VERSION ""

NS_ :

BS_:

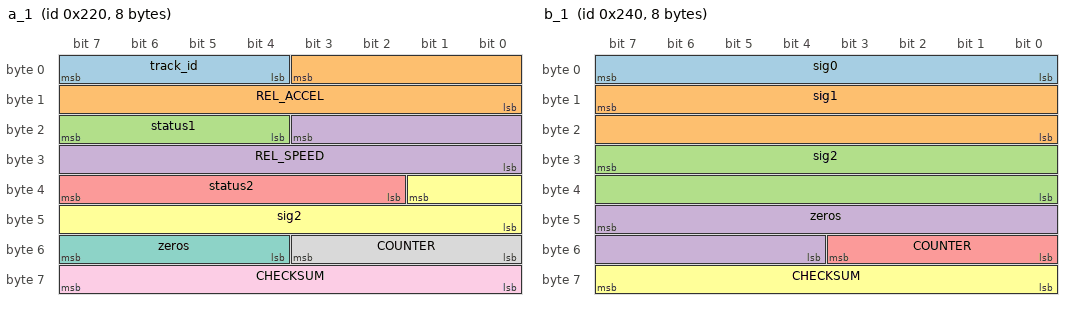
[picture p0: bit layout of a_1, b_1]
BO_ 544 a_1: 8 XXX
 SG_ track_id : 7|4@0+ (1,0) [0|15] "" XXX
 SG_ REL_ACCEL : 3|12@0+ (1,0) [0|31] "" XXX
 SG_ status1 : 23|4@0+ (1,0) [0|15] "" XXX
 SG_ REL_SPEED : 19|12@0+ (1,0) [0|65535] "" XXX
 SG_ status2 : 39|6@0+ (1,0) [0|15] "" XXX
 SG_ sig2 : 33|10@0+ (1,0) [0|255] "" XXX
 SG_ zeros : 55|4@0+ (1,0) [0|15] "" XXX
 SG_ COUNTER : 51|4@0+ (1,0) [0|15] "" XXX
 SG_ CHECKSUM : 63|8@0+ (1,0) [0|255] "" XXX

BO_ 576 b_1: 8 XXX
 SG_ sig0 : 7|8@0+ (1,0) [0|255] "" XXX
 SG_ sig1 : 15|16@0+ (1,0) [0|65535] "" XXX
 SG_ sig2 : 31|16@0+ (1,0) [0|255] "" XXX
 SG_ zeros : 47|12@0+ (1,0) [0|255] "" XXX
 SG_ COUNTER : 51|4@0+ (1,0) [0|15] "" XXX
 SG_ CHECKSUM : 63|8@0+ (1,0) [0|255] "" XXX

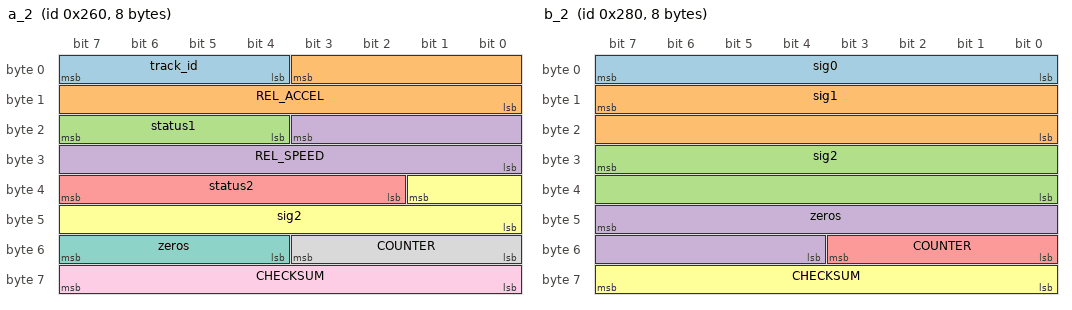
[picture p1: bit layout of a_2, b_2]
BO_ 608 a_2: 8 XXX
 SG_ track_id : 7|4@0+ (1,0) [0|15] "" XXX
 SG_ REL_ACCEL : 3|12@0+ (1,0) [0|31] "" XXX
 SG_ status1 : 23|4@0+ (1,0) [0|15] "" XXX
 SG_ REL_SPEED : 19|12@0+ (1,0) [0|65535] "" XXX
 SG_ status2 : 39|6@0+ (1,0) [0|15] "" XXX
 SG_ sig2 : 33|10@0+ (1,0) [0|255] "" XXX
 SG_ zeros : 55|4@0+ (1,0) [0|15] "" XXX
 SG_ COUNTER : 51|4@0+ (1,0) [0|15] "" XXX
 SG_ CHECKSUM : 63|8@0+ (1,0) [0|255] "" XXX

BO_ 640 b_2: 8 XXX
 SG_ sig0 : 7|8@0+ (1,0) [0|255] "" XXX
 SG_ sig1 : 15|16@0+ (1,0) [0|65535] "" XXX
 SG_ sig2 : 31|16@0+ (1,0) [0|255] "" XXX
 SG_ zeros : 47|12@0+ (1,0) [0|255] "" XXX
 SG_ COUNTER : 51|4@0+ (1,0) [0|15] "" XXX
 SG_ CHECKSUM : 63|8@0+ (1,0) [0|255] "" XXX

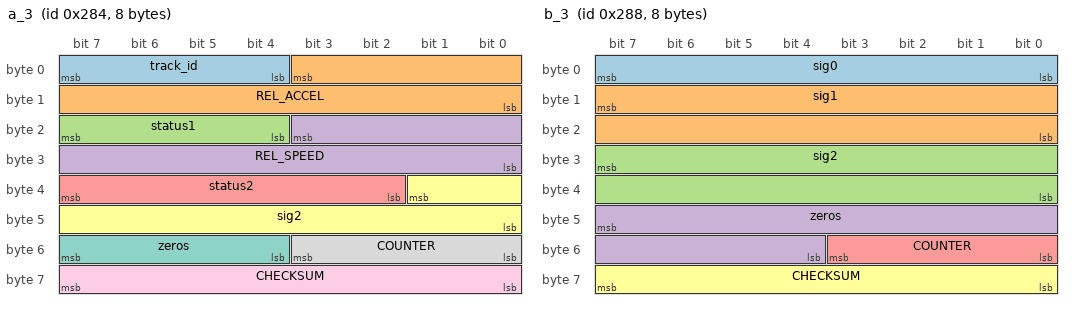
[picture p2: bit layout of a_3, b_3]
BO_ 644 a_3: 8 XXX
 SG_ track_id : 7|4@0+ (1,0) [0|15] "" XXX
 SG_ REL_ACCEL : 3|12@0+ (1,0) [0|31] "" XXX
 SG_ status1 : 23|4@0+ (1,0) [0|15] "" XXX
 SG_ REL_SPEED : 19|12@0+ (1,0) [0|65535] "" XXX
 SG_ status2 : 39|6@0+ (1,0) [0|15] "" XXX
 SG_ sig2 : 33|10@0+ (1,0) [0|255] "" XXX
 SG_ zeros : 55|4@0+ (1,0) [0|15] "" XXX
 SG_ COUNTER : 51|4@0+ (1,0) [0|15] "" XXX
 SG_ CHECKSUM : 63|8@0+ (1,0) [0|255] "" XXX

BO_ 648 b_3: 8 XXX
 SG_ sig0 : 7|8@0+ (1,0) [0|255] "" XXX
 SG_ sig1 : 15|16@0+ (1,0) [0|65535] "" XXX
 SG_ sig2 : 31|16@0+ (1,0) [0|255] "" XXX
 SG_ zeros : 47|12@0+ (1,0) [0|255] "" XXX
 SG_ COUNTER : 51|4@0+ (1,0) [0|15] "" XXX
 SG_ CHECKSUM : 63|8@0+ (1,0) [0|255] "" XXX

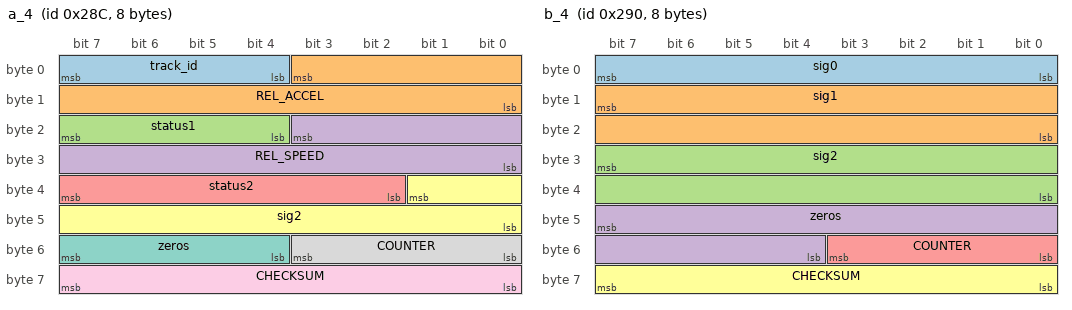
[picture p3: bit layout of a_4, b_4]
BO_ 652 a_4: 8 XXX
 SG_ track_id : 7|4@0+ (1,0) [0|15] "" XXX
 SG_ REL_ACCEL : 3|12@0+ (1,0) [0|31] "" XXX
 SG_ status1 : 23|4@0+ (1,0) [0|15] "" XXX
 SG_ REL_SPEED : 19|12@0+ (1,0) [0|65535] "" XXX
 SG_ status2 : 39|6@0+ (1,0) [0|15] "" XXX
 SG_ sig2 : 33|10@0+ (1,0) [0|255] "" XXX
 SG_ zeros : 55|4@0+ (1,0) [0|15] "" XXX
 SG_ COUNTER : 51|4@0+ (1,0) [0|15] "" XXX
 SG_ CHECKSUM : 63|8@0+ (1,0) [0|255] "" XXX

BO_ 656 b_4: 8 XXX
 SG_ sig0 : 7|8@0+ (1,0) [0|255] "" XXX
 SG_ sig1 : 15|16@0+ (1,0) [0|65535] "" XXX
 SG_ sig2 : 31|16@0+ (1,0) [0|255] "" XXX
 SG_ zeros : 47|12@0+ (1,0) [0|255] "" XXX
 SG_ COUNTER : 51|4@0+ (1,0) [0|15] "" XXX
 SG_ CHECKSUM : 63|8@0+ (1,0) [0|255] "" XXX

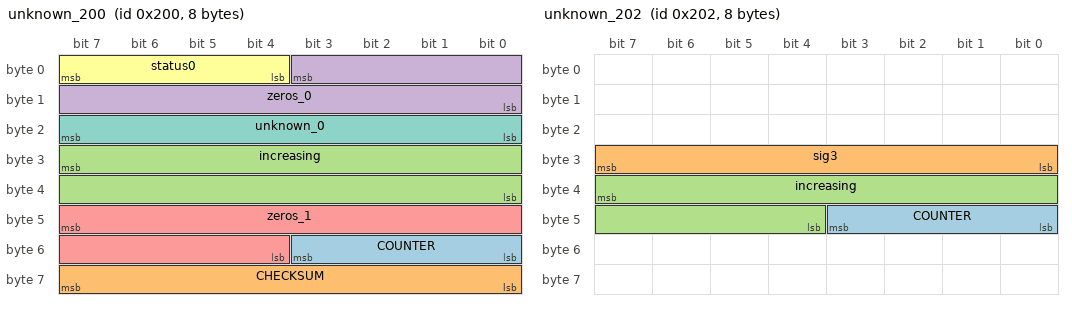
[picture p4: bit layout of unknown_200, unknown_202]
BO_ 512 unknown_200: 8 XXX
 SG_ COUNTER : 51|4@0+ (1,0) [0|15] "" XXX
 SG_ CHECKSUM : 63|8@0+ (1,0) [0|255] "" XXX
 SG_ increasing : 31|16@0+ (1,0) [0|255] "" XXX
 SG_ zeros_0 : 3|12@0+ (1,0) [0|63] "" XXX
 SG_ zeros_1 : 47|12@0+ (1,0) [0|63] "" XXX
 SG_ status0 : 7|4@0+ (1,0) [0|15] "" XXX
 SG_ unknown_0 : 23|8@0+ (1,0) [0|255] "" XXX

BO_ 514 unknown_202: 8 XXX
 SG_ COUNTER : 43|4@0+ (1,0) [0|15] "" XXX
 SG_ sig3 : 31|8@0+ (1,0) [0|65535] "" XXX
 SG_ increasing : 39|12@0+ (1,0) [0|15] "" XXX

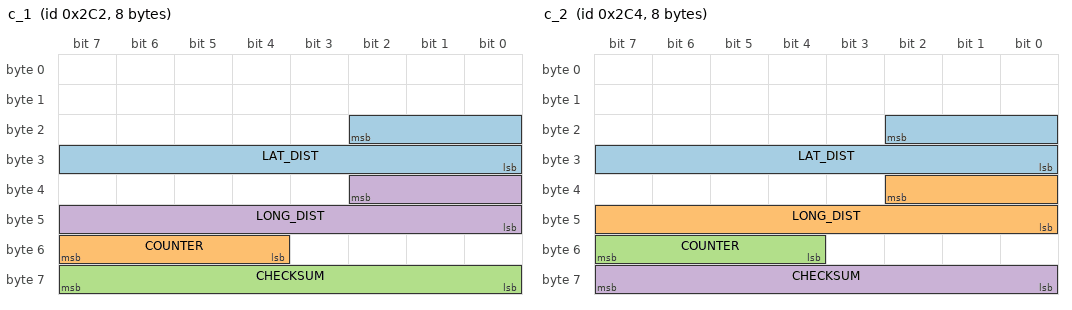
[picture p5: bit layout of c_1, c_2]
BO_ 706 c_1: 8 XXX
 SG_ LAT_DIST : 18|11@0+ (0.005,-1000) [0|2047] "m" XXX
 SG_ COUNTER : 55|4@0+ (1,0) [0|15] "" XXX
 SG_ CHECKSUM : 63|8@0+ (1,0) [0|255] "" XXX
 SG_ LONG_DIST : 34|11@0+ (0.073,0) [0|255] "m" XXX

BO_ 708 c_2: 8 XXX
 SG_ LAT_DIST : 18|11@0+ (0.005,-1000) [0|2047] "m" XXX
 SG_ LONG_DIST : 34|11@0+ (0.073,0) [0|255] "m" XXX
 SG_ COUNTER : 55|4@0+ (1,0) [0|15] "" XXX
 SG_ CHECKSUM : 63|8@0+ (1,0) [0|255] "" XXX

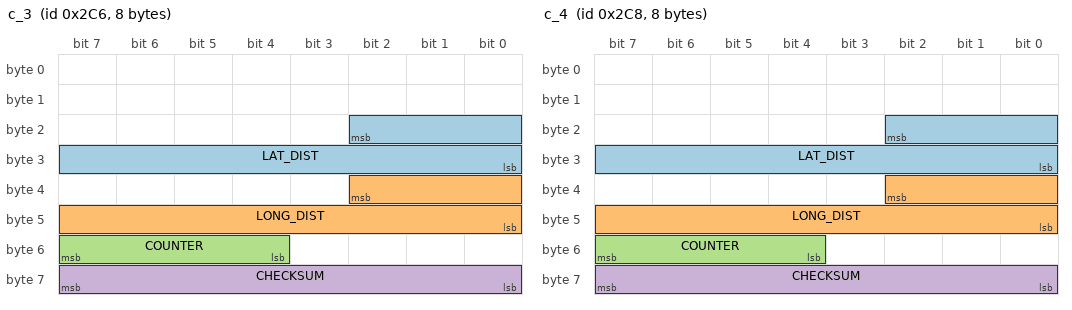
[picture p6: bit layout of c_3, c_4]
BO_ 710 c_3: 8 XXX
 SG_ LAT_DIST : 18|11@0+ (0.005,-1000) [0|2047] "m" XXX
 SG_ LONG_DIST : 34|11@0+ (0.073,0) [0|255] "m" XXX
 SG_ COUNTER : 55|4@0+ (1,0) [0|15] "" XXX
 SG_ CHECKSUM : 63|8@0+ (1,0) [0|255] "" XXX

BO_ 712 c_4: 8 XXX
 SG_ LAT_DIST : 18|11@0+ (0.005,-1000) [0|2047] "m" XXX
 SG_ LONG_DIST : 34|11@0+ (0.073,0) [0|255] "m" XXX
 SG_ COUNTER : 55|4@0+ (1,0) [0|15] "" XXX
 SG_ CHECKSUM : 63|8@0+ (1,0) [0|255] "" XXX

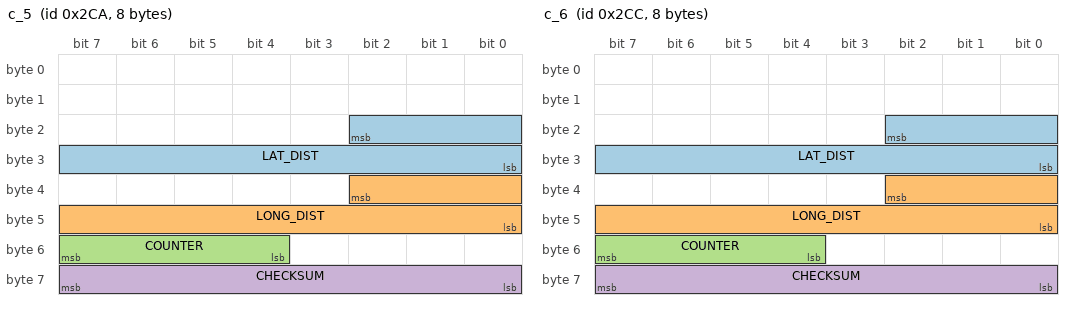
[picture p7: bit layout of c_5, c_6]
BO_ 714 c_5: 8 XXX
 SG_ LAT_DIST : 18|11@0+ (0.005,-1000) [0|2047] "m" XXX
 SG_ LONG_DIST : 34|11@0+ (0.073,0) [0|255] "m" XXX
 SG_ COUNTER : 55|4@0+ (1,0) [0|15] "" XXX
 SG_ CHECKSUM : 63|8@0+ (1,0) [0|255] "" XXX

BO_ 716 c_6: 8 XXX
 SG_ LAT_DIST : 18|11@0+ (0.005,-1000) [0|2047] "m" XXX
 SG_ LONG_DIST : 34|11@0+ (0.073,0) [0|255] "m" XXX
 SG_ COUNTER : 55|4@0+ (1,0) [0|15] "" XXX
 SG_ CHECKSUM : 63|8@0+ (1,0) [0|255] "" XXX

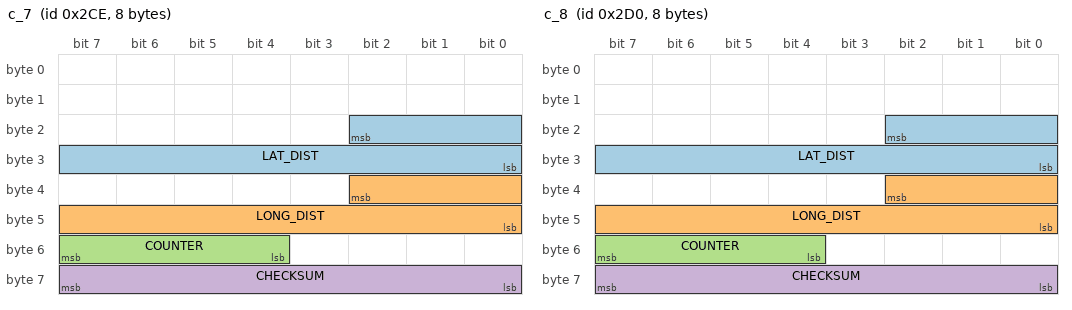
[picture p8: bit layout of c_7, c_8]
BO_ 718 c_7: 8 XXX
 SG_ LAT_DIST : 18|11@0+ (0.005,-1000) [0|2047] "m" XXX
 SG_ LONG_DIST : 34|11@0+ (0.073,0) [0|255] "m" XXX
 SG_ COUNTER : 55|4@0+ (1,0) [0|15] "" XXX
 SG_ CHECKSUM : 63|8@0+ (1,0) [0|255] "" XXX

BO_ 720 c_8: 8 XXX
 SG_ LAT_DIST : 18|11@0+ (0.005,-1000) [0|2047] "m" XXX
 SG_ LONG_DIST : 34|11@0+ (0.073,0) [0|255] "m" XXX
 SG_ COUNTER : 55|4@0+ (1,0) [0|15] "" XXX
 SG_ CHECKSUM : 63|8@0+ (1,0) [0|255] "" XXX

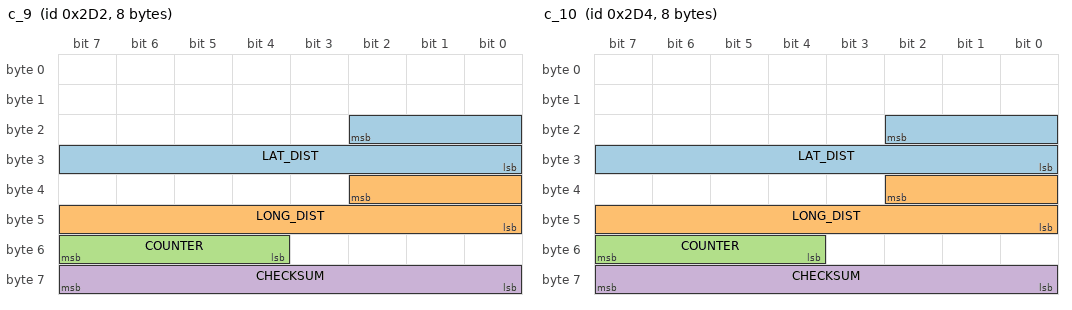
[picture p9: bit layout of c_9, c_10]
BO_ 722 c_9: 8 XXX
 SG_ LAT_DIST : 18|11@0+ (0.005,-1000) [0|2047] "m" XXX
 SG_ LONG_DIST : 34|11@0+ (0.073,0) [0|255] "m" XXX
 SG_ COUNTER : 55|4@0+ (1,0) [0|15] "" XXX
 SG_ CHECKSUM : 63|8@0+ (1,0) [0|255] "" XXX

BO_ 724 c_10: 8 XXX
 SG_ LAT_DIST : 18|11@0+ (0.005,-1000) [0|2047] "m" XXX
 SG_ LONG_DIST : 34|11@0+ (0.073,0) [0|255] "m" XXX
 SG_ COUNTER : 55|4@0+ (1,0) [0|15] "" XXX
 SG_ CHECKSUM : 63|8@0+ (1,0) [0|255] "" XXX

BO_ 674 d_1: 8 XXX
 SG_ REL_SPEED : 17|10@0+ (0.2857,-146.278) [0|1023] "m/s" XXX

BO_ 676 d_2: 8 XXX
 SG_ REL_SPEED : 17|10@0+ (0.2857,-146.278) [0|1023] "m/s" XXX

BO_ 678 d_3: 8 XXX
 SG_ REL_SPEED : 17|10@0+ (0.2857,-146.278) [0|1023] "m/s" XXX

BO_ 680 d_4: 8 XXX
 SG_ REL_SPEED : 17|10@0+ (0.2857,-146.278) [0|1023] "m/s" XXX

BO_ 682 d_5: 8 XXX
 SG_ REL_SPEED : 17|10@0+ (0.2857,-146.278) [0|1023] "m/s" XXX

BO_ 684 d_6: 8 XXX
 SG_ REL_SPEED : 17|10@0+ (0.2857,-146.278) [0|1023] "m/s" XXX

BO_ 686 d_7: 8 XXX
 SG_ REL_SPEED : 17|10@0+ (0.2857,-146.278) [0|1023] "m/s" XXX

BO_ 688 d_8: 8 XXX
 SG_ REL_SPEED : 17|10@0+ (0.2857,-146.278) [0|1023] "m/s" XXX

BO_ 690 d_9: 8 XXX
 SG_ REL_SPEED : 17|10@0+ (0.2857,-146.278) [0|1023] "m/s" XXX

BO_ 692 d_10: 8 XXX
 SG_ REL_SPEED : 17|10@0+ (0.2857,-146.278) [0|1023] "m/s" XXX

BO_ 672 NEW_MSG_5: 8 XXX
 SG_ NEW_SIGNAL_1 : 9|10@0+ (1,0) [0|1023] "" XXX
 SG_ NEW_SIGNAL_2 : 45|10@0+ (1,0) [0|1023] "" XXX

BU_: RRSRR_FO LRSRR_FO CIPM_FO _DOFIMU2_FO _DOFIMU1_FO DMS_FO AMM_FO EOCM2B_IMX6_FO EOCM2B_K2_FO EOCM2B_K1_FO EOCM2A_IMX6_FO EOCM2A_K2_FO EOCM2A_K1_FO NVS_FO Dummy_FO TestTool_FO LRR_FO RFSRR_FO LFSRR_FO RSRR_FO VIS_FO EOCM_F_FO VIS2_FO
VAL_TABLE_ vt_BooleanValues 1 "true" 0 "false" ;
VAL_TABLE_ FrntVsnInPthVehBrkNwSt 10 "Active" 5 "Inactive" ;
VAL_TABLE_ FrntVsnClostPedBrkNwSt 10 "Active" 5 "Inactive" ;
VAL_TABLE_ DrvrMonSysEngSt 7 "Unused and Reserved 1" 6 "Recovering" 5 "Tracking" 4 "Searching" 3 "Video test port only" 2 "Idle" 1 "Invalid state" 0 "Does not exist or DME" ;
VAL_TABLE_ DrvrMonEngUnrecvrFltCod 7 "Unused and Reserved 3" 6 "Unused and Reserved 2" 5 "Unused and Reserved 1" 4 "Vehicle power supply Errors" 3 "Problem with LED illuminators" 2 "Vehicle input signals Errors" 1 "Problem with imager" 0 "Ok" ;
VAL_TABLE_ DrvrMonEngRecvrFltCod 3 "Engine is unable to find a face" 2 "Input Images too dark" 1 "Input images too bright" 0 "Ok" ;
VAL_TABLE_ DrvrMntrSysVTP 1 "Video test port active" 0 "Video test port inactive" ;
VAL_TABLE_ DrvrAttnStatCnfdc 3 "High" 2 "Medium" 1 "Low" 0 "Lowest" ;
VAL_TABLE_ DrvrAttnStat 7 "Invalid" 6 "Driver is exhibiting sleep" 5 "Driver is exhibiting microsleep" 4 "Attention is Center Console" 3 "Attention is Drivers Lap" 2 "Attention is Off Road" 1 "Attention is On Road" 0 "Unknown" ;
VAL_TABLE_ PPSMd 7 "GNSS and RTX and DR and MM" 6 "DR ONLY" 5 "GNSS and RTX and DR" 4 "GNSS and SBAS and DR" 3 "GNSS and DR" 2 "GNSS and  RTX" 1 "GNSS and SBAS" 0 "GNSS Standalone" ;
VAL_TABLE_ AdvDrvAstMpPrfShrtAcur 3 "Accuracy Is Unknown" 2 "Lowest Accuracy" 1 "Medium Accuracy" 0 "Highest Accuracy" ;
VAL_TABLE_ AdvDrAstMpStbRtOfWay 3 "Not Applicable" 2 "Unknown" 1 "Sub Path Has Right Of Way Over Path" 0 "Path Has Right Of Way Over Sub Path" ;
VAL_TABLE_ AdvDrAstMpStbPrtCalRut 3 "Not Applicable" 2 "Unknown" 1 "Path From This Point On Is Part Of Calculated Route" 0 "Path From This Point On Is Not Part Of Calculated Route" ;
VAL_TABLE_ AdvDrAstMpStbMsgTyp 7 "Unused and Reserved 2" 6 "Metadata" 5 "Profile Long" 4 "Profile Short" 3 "Stub" 2 "Segment" 1 "Position" 0 "Unused and Reserved 1" ;
VAL_TABLE_ AdvDrAstMpStbFmOfWay 15 "Not Applicable" 14 "Pedestrian Zone" 13 "Entrance To Or Exit To Service" 12 "Entrance To Or Exit Of A Car Park" 11 "Service Road Or Frontage Road" 10 "Slip Road per Ramp" 9 "Slip Road per Ramp On A Freeway Or Controlled Access Road" 8 "Parallel Road" 7 "Unused and Reserved 2" 6 "Unused and Reserved 1" 5 "Traffic Square per Special Traffic Figure" 4 "Roundabout Circle" 3 "Single Carriageway" 2 "Multiple Carriageway Or Multiply Digitized Road" 1 "Freeway Or Controlled Access Road That Is Not A Slip Road Or Ramp" 0 "Unknown" ;
VAL_TABLE_ AdvDrAstMpStbCmplxInsct 3 "Not Applicable" 2 "Unknown" 1 "Stub Is Part Of Complex Intersection" 0 "Stub Is Not Part Of Complex Intersection" ;
VAL_TABLE_ AdvDrAstMpSegTunl 3 "Not Applicable" 2 "Unknown" 1 "Segment Is Part Of Tunnel" 0 "Segment Is Not A Part Of Tunnel" ;
VAL_TABLE_ AdvDrAstMpSegPrtCalRut 3 "Not Applicable" 2 "Unknown" 1 "Segment Is Part Of Calculated Route" 0 "Segment Is Not Part Of Calculated Route" ;
VAL_TABLE_ AdvDrAstMpSegMsgTyp 7 "Unused and Reserved 2" 6 "Metadata" 5 "Profile Long" 4 "Profile Short" 3 "Stub" 2 "Segment" 1 "Position" 0 "Unused and Reserved 1" ;
VAL_TABLE_ AdvDrAstMpSegFrmOfWay 15 "Not Applicable" 14 "Pedestrian Zone" 13 "Entrance To Or Exit To Service" 12 "Entrance To Or Exit Of A Car Park" 11 "Service Road Or Frontage Road" 10 "Slip Road per Ramp" 9 "Slip Road per Ramp On A Freeway Or Controlled Access Road" 8 "Parallel Road" 7 "Unused and Reserved 2" 6 "Unused and Reserved 1" 5 "Traffic Square per Special Traffic Figure" 4 "Roundabout Circle" 3 "Single Carriageway" 2 "Multiple Carriageway Or Multiply Digitized Road" 1 "Freeway Or Controlled Access Road That Is Not A Slip Road or Ramp" 0 "Unknown" ;
VAL_TABLE_ AdvDrAstMpSegEffSdLmtTp 7 "Not Applicable" 6 "Explicit Snow" 5 "Explicit Rain" 4 "Explicit Time Of Day" 3 "Explicit By Day" 2 "Explicit By Night" 1 "Explicit On Traffic Sign" 0 "Implicit" ;
VAL_TABLE_ AdvDrAstMpSegDivdRd 3 "Not Applicable" 2 "Unknown" 1 "Segment Is Part Of Divided Road" 0 "Segment Is Not Part Of Divided Road" ;
VAL_TABLE_ AdvDrAstMpSegCmplxInsct 3 "Not Applicable" 2 "Unknown" 1 "Segment Is Part Of Complex Intersection" 0 "Segment Is Not Part Of Complex Intersection" ;
VAL_TABLE_ AdvDrAstMpSegBrdg 3 "Not Applicable" 2 "Unknown" 1 "Segment Is Part Of Bridge" 0 "Segment Not Part Of Bridge" ;
VAL_TABLE_ AdvDrAstMpSegBldUpAra 3 "Not Applicable" 2 "Unknown" 1 "Segment Is Part Of Built Up Area" 0 "Segment Is Not Part Of Built Up Area" ;
VAL_TABLE_ AdvDrAstMpMtdtSpdUnt 1 "Miles Per Hour" 0 "Kilometers Per Hour" ;
VAL_TABLE_ AdvDrAstMpMtdtDrvSd 1 "Driving Side Right" 0 "Driving Side Left" ;
VAL_TABLE_ WSMR_WiFiAssnReq 3 "Unexpected Undefined Connection Behavior" 2 "Wi Fi association failed with available credentials" 1 "Failed to receive Wi Fi credentials after 255 attempts" 0 "SSID and Passphrase Request" ;
VAL_TABLE_ StrgColCommsFlt 2 "Disabled Communications DTC" 1 "No Communications Fault" 0 "Communications Fault" ;
VAL_TABLE_ CPMAPINFO4 1 "Hardware Or Software Error" 0 "No Hardware Or Software Error" ;
VAL_TABLE_ AdvDrvAstMpPrfShrt2Acur 3 "Accuracy Is Unknown" 2 "Lowest Accuracy" 1 "Medium Accuracy" 0 "Highest Accuracy" ;
VAL_TABLE_ InterLghtStat 1 "Interior Lights On" 0 "Interior Light Off" ;
VAL_TABLE_ VehLnStatConf 2 "High Confidence" 1 "Low Confidence" 0 "No Confidence" 3 "Very High Confidence" ;
VAL_TABLE_ VehLnStat 3 "Lane Change To Right" 2 "Lane Change To Left" 1 "Staying in Lane" 0 "Unknown" ;
VAL_TABLE_ HrznPrvdRstRq 1 "Reset Not Required" 0 "Reset Required" ;
VAL_TABLE_ ExptNxtTrnstnDirConf 3 "Very High Confidence" 2 "High Confidence" 1 "Low Confidence" 0 "No Confidence" ;
VAL_TABLE_ ExptNxtTrnstnDir 7 "Reserved4" 6 "Reserved3" 5 "Reserved2" 4 "Reserved1" 3 "Traversing Middle Transition" 2 "Traversing Next Transition Right" 1 "Traversing Next Transition Left" 0 "Unknown" ;
VAL_TABLE_ ADASISMsgTypRetrans 7 "GM System Specific" 6 "Meta Data" 5 "Profile Long" 4 "Profile Short" 3 "Stub" 2 "Segment" 1 "Position" 0 "Checksum" ;
VAL_TABLE_ NVSysStat 7 "Needs Headlights" 6 "Temporarily Unavailable" 5 "Not Dark" 4 "Needs Service" 3 "Active" 2 "Inactive" 1 "Initializing" 0 "Unknown" ;
VAL_TABLE_ NVSysPedWrnIndReq 3 "Unused & Reserved" 2 "Pedestrian Alert" 1 "Pedestrian Detected" 0 "None" ;
VAL_TABLE_ NVSysPedDetCstReq 2 "On" 1 "Off" 0 "No Value" ;
VAL_TABLE_ NVSysPedDetCsCrStVal 2 "On" 1 "Off" 0 "No Value" ;
VAL_TABLE_ FwVsnCinCoutPotT9Rev 2 "Right" 1 "Left" 0 "None" ;
VAL_TABLE_ FwVsnCinCoutPotT8Rev 2 "Right" 1 "Left" 0 "None" ;
VAL_TABLE_ FwVsnCinCoutPotT7Rev 2 "Right" 1 "Left" 0 "None" ;
VAL_TABLE_ FwVsnCinCoutPotT6Rev 2 "Right" 1 "Left" 0 "None" ;
VAL_TABLE_ FwVsnCinCoutPotT5Rev 2 "Right" 1 "Left" 0 "None" ;
VAL_TABLE_ FwVsnCinCoutPotT4Rev 2 "Right" 1 "Left" 0 "None" ;
VAL_TABLE_ FwVsnCinCoutPotT3Rev 2 "Right" 1 "Left" 0 "None" ;
VAL_TABLE_ FwVsnCinCoutPotT2Rev 2 "Right" 1 "Left" 0 "None" ;
VAL_TABLE_ FwVsnCinCoutPotT1Rev 2 "Right" 1 "Left" 0 "None" ;
VAL_TABLE_ FwVsnCinCoutPotT12Rev 2 "Right" 1 "Left" 0 "None" ;
VAL_TABLE_ FwVsnCinCoutPotT11Rev 2 "Right" 1 "Left" 0 "None" ;
VAL_TABLE_ FwVsnCinCoutPotT10Rev 2 "Right" 1 "Left" 0 "None" ;
VAL_TABLE_ GFHBObjDirTrk8 1 "Ahead Traffic" 0 "Incoming Traffic" ;
VAL_TABLE_ GFHBObjDirTrk7 1 "Ahead Traffic" 0 "Incoming Traffic" ;
VAL_TABLE_ GFHBObjDirTrk6 1 "Ahead Traffic" 0 "Incoming Traffic" ;
VAL_TABLE_ GFHBObjDirTrk5 1 "Ahead Traffic" 0 "Incoming Traffic" ;
VAL_TABLE_ GFHBObjDirTrk4 1 "Ahead Traffic" 0 "Incoming Traffic" ;
VAL_TABLE_ GFHBObjDirTrk3 1 "Ahead Traffic" 0 "Incoming Traffic" ;
VAL_TABLE_ GFHBObjDirTrk2 1 "Ahead Traffic" 0 "Incoming Traffic" ;
VAL_TABLE_ GFHBObjDirTrk1 1 "Ahead Traffic" 0 "Incoming Traffic" ;
VAL_TABLE_ GFHBFwVsnRelLaneTrk8 3 "Left Lane" 2 "Right Lane" 1 "Host Lane" 0 "Unknown" ;
VAL_TABLE_ GFHBFwVsnRelLaneTrk7 3 "Left Lane" 2 "Right Lane" 1 "Host Lane" 0 "Unknown" ;
VAL_TABLE_ GFHBFwVsnRelLaneTrk6 3 "Left Lane" 2 "Right Lane" 1 "Host Lane" 0 "Unknown" ;
VAL_TABLE_ GFHBFwVsnRelLaneTrk5 3 "Left Lane" 2 "Right Lane" 1 "Host Lane" 0 "Unknown" ;
VAL_TABLE_ GFHBFwVsnRelLaneTrk4 3 "Left Lane" 2 "Right Lane" 1 "Host Lane" 0 "Unknown" ;
VAL_TABLE_ GFHBFwVsnRelLaneTrk3 3 "Left Lane" 2 "Right Lane" 1 "Host Lane" 0 "Unknown" ;
VAL_TABLE_ GFHBFwVsnRelLaneTrk2 3 "Left Lane" 2 "Right Lane" 1 "Host Lane" 0 "Unknown" ;
VAL_TABLE_ GFHBFwVsnRelLaneTrk1 3 "Left Lane" 2 "Right Lane" 1 "Host Lane" 0 "Unknown" ;
VAL_TABLE_ GFHBFwVsnMesStatTrk8 3 "Measured this cycle" 2 "Latent track not detected this cycle" 1 "New Object" 0 "No Object" ;
VAL_TABLE_ GFHBFwVsnMesStatTrk7 3 "Measured this cycle" 2 "Latent track not detected this cycle" 1 "New Object" 0 "No Object" ;
VAL_TABLE_ GFHBFwVsnMesStatTrk6 3 "Measured this cycle" 2 "Latent track not detected this cycle" 1 "New Object" 0 "No Object" ;
VAL_TABLE_ GFHBFwVsnMesStatTrk5 3 "Measured this cycle" 2 "Latent track not detected this cycle" 1 "New Object" 0 "No Object" ;
VAL_TABLE_ GFHBFwVsnMesStatTrk4 3 "Measured this cycle" 2 "Latent track not detected this cycle" 1 "New Object" 0 "No Object" ;
VAL_TABLE_ GFHBFwVsnMesStatTrk3 3 "Measured this cycle" 2 "Latent track not detected this cycle" 1 "New Object" 0 "No Object" ;
VAL_TABLE_ GFHBFwVsnMesStatTrk2 3 "Measured this cycle" 2 "Latent track not detected this cycle" 1 "New Object" 0 "No Object" ;
VAL_TABLE_ GFHBFwVsnMesStatTrk1 3 "Measured this cycle" 2 "Latent track not detected this cycle" 1 "New Object" 0 "No Object" ;
VAL_TABLE_ GFHBFwVsnCnfdncTrk8 3 "Confident" 2 "Speculative" 1 "Highly Speculative" 0 "Invalid" ;
VAL_TABLE_ GFHBFwVsnCnfdncTrk7 3 "Confident" 2 "Speculative" 1 "Highly Speculative" 0 "Invalid" ;
VAL_TABLE_ GFHBFwVsnCnfdncTrk6 3 "Confident" 2 "Speculative" 1 "Highly Speculative" 0 "Invalid" ;
VAL_TABLE_ GFHBFwVsnCnfdncTrk5 3 "Confident" 2 "Speculative" 1 "Highly Speculative" 0 "Invalid" ;
VAL_TABLE_ GFHBFwVsnCnfdncTrk4 3 "Confident" 2 "Speculative" 1 "Highly Speculative" 0 "Invalid" ;
VAL_TABLE_ GFHBFwVsnCnfdncTrk3 3 "Confident" 2 "Speculative" 1 "Highly Speculative" 0 "Invalid" ;
VAL_TABLE_ GFHBFwVsnCnfdncTrk2 3 "Confident" 2 "Speculative" 1 "Highly Speculative" 0 "Invalid" ;
VAL_TABLE_ GFHBFwVsnCnfdncTrk1 0 "Invalid" 3 "Confident" 2 "Speculative" 1 "Highly Speculative" ;
VAL_TABLE_ GFHBFVsnObjTypTrkRev8 12 "Cluster Object" 11 "Child Close to Danger Zone" 10 "Pedestrian Moving Out of Danger Zone" 9 "Pedestrian Moving Into Danger Zone" 8 "Pedestrian Standing Outside Danger Zone" 7 "No Object Present" 6 "Fixed Roadside Object" 5 "Fixed Overhead Object" 4 "Pedestrian" 3 "Motorcycle/ Bicycle" 2 "Large Vehicle (Semi)" 1 "4 Wheel Vehicle (Car)" 0 "Unknown" ;
VAL_TABLE_ GFHBFVsnObjTypTrkRev7 12 "Cluster Object" 11 "Child Close to Danger Zone" 10 "Pedestrian Moving Out of Danger Zone" 9 "Pedestrian Moving Into Danger Zone" 8 "Pedestrian Standing Outside Danger Zone" 7 "No Object Present" 6 "Fixed Roadside Object" 5 "Fixed Overhead Object" 4 "Pedestrian" 3 "Motorcycle/ Bicycle" 2 "Large Vehicle (Semi)" 1 "4 Wheel Vehicle (Car)" 0 "Unknown" ;
VAL_TABLE_ GFHBFVsnObjTypTrkRev6 12 "Cluster Object" 11 "Child Close to Danger Zone" 10 "Pedestrian Moving Out of Danger Zone" 9 "Pedestrian Moving Into Danger Zone" 8 "Pedestrian Standing Outside Danger Zone" 7 "No Object Present" 6 "Fixed Roadside Object" 5 "Fixed Overhead Object" 4 "Pedestrian" 3 "Motorcycle/ Bicycle" 2 "Large Vehicle (Semi)" 1 "4 Wheel Vehicle (Car)" 0 "Unknown" ;
VAL_TABLE_ GFHBFVsnObjTypTrkRev5 12 "Cluster Object" 11 "Child Close to Danger Zone" 10 "Pedestrian Moving Out of Danger Zone" 9 "Pedestrian Moving Into Danger Zone" 8 "Pedestrian Standing Outside Danger Zone" 7 "No Object Present" 6 "Fixed Roadside Object" 5 "Fixed Overhead Object" 4 "Pedestrian" 3 "Motorcycle/ Bicycle" 2 "Large Vehicle (Semi)" 1 "4 Wheel Vehicle (Car)" 0 "Unknown" ;
VAL_TABLE_ GFHBFVsnObjTypTrkRev4 12 "Cluster Object" 11 "Child Close to Danger Zone" 10 "Pedestrian Moving Out of Danger Zone" 9 "Pedestrian Moving Into Danger Zone" 8 "Pedestrian Standing Outside Danger Zone" 7 "No Object Present" 6 "Fixed Roadside Object" 5 "Fixed Overhead Object" 4 "Pedestrian" 3 "Motorcycle/ Bicycle" 2 "Large Vehicle (Semi)" 1 "4 Wheel Vehicle (Car)" 0 "Unknown" ;
VAL_TABLE_ GFHBFVsnObjTypTrkRev3 12 "Cluster Object" 11 "Child Close to Danger Zone" 10 "Pedestrian Moving Out of Danger Zone" 9 "Pedestrian Moving Into Danger Zone" 8 "Pedestrian Standing Outside Danger Zone" 7 "No Object Present" 6 "Fixed Roadside Object" 5 "Fixed Overhead Object" 4 "Pedestrian" 3 "Motorcycle/ Bicycle" 2 "Large Vehicle (Semi)" 1 "4 Wheel Vehicle (Car)" 0 "Unknown" ;
VAL_TABLE_ GFHBFVsnObjTypTrkRev2 12 "Cluster Object" 11 "Child Close to Danger Zone" 10 "Pedestrian Moving Out of Danger Zone" 9 "Pedestrian Moving Into Danger Zone" 8 "Pedestrian Standing Outside Danger Zone" 7 "No Object Present" 6 "Fixed Roadside Object" 5 "Fixed Overhead Object" 4 "Pedestrian" 3 "Motorcycle/ Bicycle" 2 "Large Vehicle (Semi)" 1 "4 Wheel Vehicle (Car)" 0 "Unknown" ;
VAL_TABLE_ GFHBFVsnObjTypTrkRev1 12 "Cluster Object" 11 "Child Close to Danger Zone" 10 "Pedestrian Moving Out of Danger Zone" 9 "Pedestrian Moving Into Danger Zone" 8 "Pedestrian Standing Outside Danger Zone" 7 "No Object Present" 6 "Fixed Roadside Object" 5 "Fixed Overhead Object" 4 "Pedestrian" 3 "Motorcycle/ Bicycle" 2 "Large Vehicle (Semi)" 1 "4 Wheel Vehicle (Car" 0 "Unknown" ;
VAL_TABLE_ CRL_Cnfdnc 7 "Reserved4" 6 "Reserved3" 5 "Reserved2" 4 "Reserved1" 3 "Best" 2 "Marking Present" 1 "Weak Marking" 0 "No Lane" ;
VAL_TABLE_ CLL_Cnfdnc 7 "Reserved4" 6 "Reserved3" 5 "Reserved2" 4 "Reserved1" 3 "Best" 2 "Marking Present" 1 "Weak Marking" 0 "No Lane" ;
VAL_TABLE_ VBBrkCtrlSt 4 "Release Control" 3 "Hold Vehicle" 2 "Apply Brake" 1 "Decrease Torque" 0 "No Action" ;
VAL_TABLE_ ObstacleType 6 "NO_OBJECT" 5 "OBJ_GUARDRAIL" 4 "OBJ_TUNNEL " 3 "OBJ_TRAFFIC_SIGN" 2 "OBJ_VEHICLE" 1 "OBJ_BRIDGE " 0 "OBJ_UNKNOWN" ;
VAL_TABLE_ VpathMode 2 "Mid Hi Speed" 1 "Low Speed" 0 "Disabled" ;
VAL_TABLE_ LaneChngStatus 2 "Lane Change Right" 1 "Lane Change Left" 0 "Idle" ;
VAL_TABLE_ TravelDirection 3 "Other (excessive side slip)" 2 "reverse / stopped in rvrs gear" 1 "Forward / stopped in frwd gear" 0 "Unknown" ;
VAL_TABLE_ TrueOrFalse 1 "true" 0 "false" ;
VAL_TABLE_ ModeCommand 5 "Sensing with Reduced Power" 4 "Undefined" 3 "Radio Silent" 2 "Sensing" 1 "Not Sensing" 0 "Undefined" ;
VAL_TABLE_ LaneSnsLLnPosValid 1 "Invalid" 0 "Valid" ;
VAL_TABLE_ LnSnsRLnPosValid 1 "Invalid" 0 "Valid" ;
VAL_TABLE_ Elevation 3 "Low " 2 "mid (reserved)" 1 "high " 0 "Unknown" ;
VAL_TABLE_ ModeCommandFdbk 5 "Sensing with reduced power" 4 "Undefined" 3 "Radio Silent" 2 "Sensing" 1 "Not Sensing" 0 "Undefined" ;
VAL_TABLE_ relativeLane 3 "Left Lane" 2 "Right Lane" 1 "Host Lane" 0 "Unknown" ;
VAL_TABLE_ RoadTypeInfo 5 "Constiction Zone Exit" 4 "Construction Zone Entry" 3 "Highway" 2 "Secondary Road" 1 "City" 0 "Unknown" ;
VAL_TABLE_ ObjectLossInfo 2 "elevation conditions" 1 "tight curve" 0 "not lost" ;
VAL_TABLE_ MeasurementStatus 3 "Measured this cycle" 2 "Latent track not detctd this cyc" 1 "New Object" 0 "No Object" ;
VAL_TABLE_ ObjectType 7 "no object present" 6 "fixed roadside object" 5 "fixed overhead object" 4 "pedestrian" 3 "motocycle  / bicycle" 2 "Large vehicle (semi)" 1 "4 Wheel Vehicle (car, small trk)" 0 "Unknown" ;
VAL_TABLE_ Confidence 3 "confident" 2 "speculative" 1 "highly speculative" 0 "invalid" ;
VAL_TABLE_ DynamicProp 4 "Moving in opposite direction" 3 "Moving in same direction as host" 2 "Has moved but currently stopped" 1 "Has never moved" 0 "Unknown" ;
VAL_TABLE_ DrvWndPosSt 6 "Fully Opened" 5 "Open More Than C" 4 "Position C" 3 "Position B" 2 "Position A" 1 "Open Less Than A" 0 "Fully Closed" ;
VAL_TABLE_ VehMovSta 4 "Invalid" 3 "Reverse" 2 "Forward" 1 "Neutral" 0 "Parked" ;
VAL_TABLE_ OtsdAmbtLtLvlStat 2 "Day" 1 "Night" 0 "Unknown" ;
VAL_TABLE_ RtTrnLmpAtv 2 "On with telltale" 1 "On without telltale" 0 "Off" ;
VAL_TABLE_ LftTrnLmpAtv 2 "On with telltale" 1 "On without telltale" 0 "Off" ;
VAL_TABLE_ HdlmpBmSelectStat 2 "High Beams" 1 "Low Beams" 0 "Unknown" ;
VAL_TABLE_ DTCI_DTCFaultType 3 "Type C" 2 "Type B" 1 "Type A" 0 "Not Supported" ;
VAL_TABLE_ TrnsShftLvrPos 13 "Forward Range J" 12 "Forward Range I" 15 "Lever Position Unknown" 11 "Forward Range H" 10 "Forward Range G" 9 "Forward Range F" 8 "Forward Range E" 7 "Forward Range D" 6 "Forward Range C" 5 "Forward Range B" 4 "Forward Range A" 3 "Neutral Range" 2 "Reverse Range" 1 "Park Range" 0 "Between Ranges" ;
VAL_TABLE_ SysPwrMd 3 "Crank Request" 2 "Run" 1 "Accessory" 0 "Off" ;
VAL_TABLE_ ValidityStates 1 "Invalid" 0 "Valid" ;

CM_ "AUTOGENERATED FILE, DO NOT EDIT";

CM_ "honda_crv_ex_2017_body.dbc starts here";
VAL_ 823 DteAcceptNew_B_Rq 1 "Yes" 0 "No";
VAL_ 824 DteCldTrlrOn_B_Stat 1 "Yes" 0 "No";
VAL_ 824 DteCldTrlrOff_B_Stat 1 "Yes" 0 "No";
VAL_ 824 DteCldTraffic_B_Stat 1 "Yes" 0 "No";
VAL_ 824 DteCldTerrain_B_Stat 1 "Yes" 0 "No";
VAL_ 824 DteCldRoute_B_Stat 1 "Yes" 0 "No";
VAL_ 824 DteCldPayload_B_Stat 1 "Yes" 0 "No";
VAL_ 824 DteCldExtTe_B_Stat 1 "Yes" 0 "No";
VAL_ 824 DteCldDcac_B_Stat 1 "Yes" 0 "No";
VAL_ 949 Tire_Press_RR_ORR_Data 65535 "Not_Supported" 65534 "Invalid" 65533 "Unknown";
VAL_ 949 Tire_Press_LR_OLR_Data 65535 "Not_Supported" 65534 "Invalid" 65533 "Unknown";
VAL_ 949 Tire_Press_LF_Data 65535 "Not_Supported" 65534 "Invalid" 65533 "Unknown";
VAL_ 949 Tire_Press_RF_Data 65535 "Not_Supported" 65534 "Invalid" 65533 "Unknown";
VAL_ 740 BattAuxCnnct_B_Cmd 1 "Close" 0 "Open";
VAL_ 1160 DgtlCommPncReset_B_Req 1 "Yes" 0 "No";
VAL_ 1160 DataMntrSustn_B_Rq 1 "Active" 0 "Inactive";
VAL_ 1160 PwSustnRdata_B_RqTelem 1 "Active" 0 "Inactive";
VAL_ 776 ScChrgrPwMax_Pw_RqCld 4095 "Faulty";
VAL_ 776 PrcondEdit_D_RqCld 7 "NotUsed_3" 6 "NotUsed_2" 5 "NotUsed_1" 4 "High" 3 "Medium" 2 "Low" 1 "Off" 0 "Null";
VAL_ 776 GoTEditMnte_T_RqCld 15 "Faulty" 14 "NoDataExists" 13 "NotUsed_2" 12 "NotUsed_1" 11 "Minute_55" 10 "Minute_50" 9 "Minute_45" 8 "Minute_40" 7 "Minute_35" 6 "Minute_30" 5 "Minute_25" 4 "Minute_20" 3 "Minute_15" 2 "Minute_10" 1 "Minute_5" 0 "Minute_0";
VAL_ 776 GoTEditHr_T_RqCld 31 "Faulty" 30 "NoDataExists";
VAL_ 776 ChrgToPcEdit_Pc_RqCld 127 "Faulty" 126 "NoDataExists";
VAL_ 776 ScFreshDataEnbl_B_Rq 1 "Yes" 0 "No";
VAL_ 776 ScEnbl_D_RqCld 3 "NotUsed" 2 "On" 1 "Off" 0 "Null";
VAL_ 775 ScDayOfWeekId_D_RqCld 7 "Sunday" 6 "Saturday" 5 "Friday" 4 "Thursday" 3 "Wednesday" 2 "Tuesday" 1 "Monday" 0 "NotUsed";
VAL_ 775 ScChrgDurSet_D_RqCld 3 "NotUsed" 2 "On" 1 "Off" 0 "Null";
VAL_ 775 ScChrgDur_T_RqCld 2047 "Faulty" 2046 "NoDataExists";
VAL_ 774 ScLocLongPostv_B_RqCld 1 "Yes" 0 "No";
VAL_ 774 ScLocLattPostv_B_RqCld 1 "Yes" 0 "No";
VAL_ 774 ScLocDelete_B_RqCld 1 "Request" 0 "NoRequest";
VAL_ 811 DistToStopover_L_Actl 65535 "Faulty";
VAL_ 811 ExtLghtDsply_D_Stat 7 "NotUsed" 6 "PressToOn3" 5 "PressToOff3" 4 "PressToOn2" 3 "PressToOff2" 2 "PressToOn1" 1 "PressToOff1" 0 "Reset";
VAL_ 811 ExtLghtRight_D_RqMnu 7 "NotUsed" 6 "PressToOn3" 5 "PressToOff3" 4 "PressToOn2" 3 "PressToOff2" 2 "PressToOn1" 1 "PressToOff1" 0 "Reset";
VAL_ 811 AutoLghtOvrrd_B_RqDrv 1 "Allowed" 0 "NotAllowed";
VAL_ 811 ExtLghtRear_D_RqMnu 7 "NotUsed" 6 "PressToOn3" 5 "PressToOff3" 4 "PressToOn2" 3 "PressToOff2" 2 "PressToOn1" 1 "PressToOff1" 0 "Reset";
VAL_ 811 ExtLghtLeft_D_RqMnu 7 "NotUsed" 6 "PressToOn3" 5 "PressToOff3" 4 "PressToOn2" 3 "PressToOff2" 2 "PressToOn1" 1 "PressToOff1" 0 "Reset";
VAL_ 811 ExtLghtFront_D_RqMnu 7 "NotUsed" 6 "PressToOn3" 5 "PressToOff3" 4 "PressToOn2" 3 "PressToOff2" 2 "PressToOn1" 1 "PressToOff1" 0 "Reset";
VAL_ 811 GoTEditMnte_T_RqMnu 15 "Faulty" 14 "NoDataExists" 13 "NotUsed_2" 12 "NotUsed_1" 11 "Minute_55" 10 "Minute_50" 9 "Minute_45" 8 "Minute_40" 7 "Minute_35" 6 "Minute_30" 5 "Minute_25" 4 "Minute_20" 3 "Minute_15" 2 "Minute_10" 1 "Minute_5" 0 "Minute_0";
VAL_ 811 GoTEditHr_T_RqMnu 31 "Faulty" 30 "NoDataExists";
VAL_ 850 VehElRngeNut_L_Dsply 4095 "Faulty" 4094 "NoDataExists";
VAL_ 850 NxtUsgSocEst_Pc_Dsply 255 "Faulty" 254 "NoDataExists";
VAL_ 850 EstmChrgTimeLP_St 255 "Invalid";
VAL_ 850 EstmChrgTimeHP_St 255 "Invalid";
VAL_ 850 ChargeNowDuration_St 255 "Invalid";
VAL_ 563 DrvBhavWarn_B_Rq 1 "On" 0 "Off";
VAL_ 563 OfbChrgSetSync_D_Rq 3 "Fail" 2 "Success" 1 "InProgress" 0 "NoSyncInProgress";
VAL_ 563 KeyOffPwMde_D_Stat 7 "NotUsed_6" 6 "NotUsed_5" 5 "NotUsed_4" 4 "NotUsed_3" 0 "Inactive" 1 "On" 2 "NotUsed_1" 3 "NotUsed_2";
VAL_ 563 ModemReset_D_Stat 15 "NotUsed_10" 14 "NotUsed_9" 13 "NotUsed_8" 12 "NotUsed_7" 11 "NotUsed_6" 10 "NotUsed_5" 9 "NotUsed_4" 8 "NotUsed_3" 7 "NotUsed_2" 6 "NotUsed_1" 5 "WifiHotSpotResetComplete" 4 "CcsResetComplete" 3 "OnlineTrafficResetComplete" 2 "PaakResetComplete" 1 "ResetNotComplete" 0 "Null";
VAL_ 563 FactoryReset_St 3 "NotUsed_2" 2 "NotUsed_1" 1 "FactoryDefaultsRestored" 0 "Null";
VAL_ 570 SuspClkSync_No_Rq 255 "Faulty" 254 "NoDataExists";
VAL_ 570 SuspRearRight_L_Actl 511 "Faulty";
VAL_ 570 SuspFrntRight_L_Actl 511 "Faulty";
VAL_ 570 SuspRear_L_Prev 511 "Fault";
VAL_ 570 SuspRear_L_Actl 511 "Fault";
VAL_ 570 SuspFrnt_L_Prev 511 "Fault";
VAL_ 570 SuspFrnt_L_Actl 511 "Fault";
VAL_ 837 Ccd_B_Falt 1 "Yes" 0 "No";
VAL_ 837 SelDrvMdeSusp_D_Stat 3 "Faulty" 2 "TemporarilyNotAvailable" 1 "Available" 0 "NotAvailable";
VAL_ 837 AdptDrvMdePt_D_Rq 7 "Faulty" 6 "NotUsed3" 5 "NotUsed2" 4 "NotUsed1" 3 "Powertrain2Sport" 2 "Powertrain2Normal" 1 "Powertrain2Comfort" 0 "AdaptiveNotActive";
VAL_ 837 AdptDrvMdeChassis_D_Rq 7 "Faulty" 6 "NotUsed3" 5 "NotUsed2" 4 "NotUsed1" 3 "Chassis2Sport" 2 "Chassis2Normal" 1 "Chassis2Comfort" 0 "AdaptiveNotActive";
VAL_ 837 CcdMsgTxt_D_RqDsply 15 "Unused8" 14 "Unused7" 13 "Unused6" 12 "Unused5" 11 "Unused4" 10 "Unused3" 9 "Unused2" 8 "StationaryMode" 7 "Mode_Change_Unavailable" 6 "CCD_Temporarily_Off" 5 "CCD_Service_Required" 4 "Faulty" 3 "Sport" 2 "Normal" 1 "Comfort" 0 "No_Mode_Selected";
VAL_ 885 BattULoChrg_D_RqOta 1 "Yes" 0 "No";
VAL_ 885 VehStrtInhbt_T_Dsply 15 "NotUsed_12" 14 "NotUsed_11" 13 "NotUsed_10" 12 "NotUsed_9" 11 "NotUsed_8" 10 "NotUsed_7" 9 "NotUsed_6" 8 "NotUsed_5" 7 "NotUsed_4" 6 "NotUsed_3" 5 "NotUsed_2" 4 "NotUsed_1" 3 "PostOtaActivatePermFail" 2 "PostOtaActivateWarning" 1 "DuringOtaActivate" 0 "NoMessage";
VAL_ 885 VehStrtInhbt_D_Dsply 15 "NotUsed_12" 14 "NotUsed_11" 13 "NotUsed_10" 12 "NotUsed_9" 11 "NotUsed_8" 10 "NotUsed_7" 9 "NotUsed_6" 8 "NotUsed_5" 7 "NotUsed_4" 6 "NotUsed_3" 5 "NotUsed_2" 4 "NotUsed_1" 3 "PostOtaActivatePermFail" 2 "PostOtaActivateWarning" 1 "DuringOtaActivate" 0 "NoMessage";
VAL_ 885 VehOnRqstr_D_Stat 11 "NotUsed_8" 10 "NotUsed_7" 9 "NotUsed_6" 8 "NotUsed_5" 7 "NotUsed_4" 6 "NotUsed_3" 5 "NotUsed_2" 4 "NotUsed_1" 3 "FleetVehInhbt" 2 "StolenVehInhbt" 1 "OverTheAir" 0 "NoRequestor" 15 "NotUsed_12" 14 "NotUsed_11" 13 "NotUsed_10" 12 "NotUsed_9";
VAL_ 885 VehStrtInhbt_D_RqCld 3 "NotUsed" 2 "On" 1 "Off" 0 "Null";
VAL_ 885 VehOn_D_RqCld 3 "NoControl" 2 "On" 1 "Off" 0 "Null";
VAL_ 885 OtaActv_D_Stat 15 "NotUsed_10" 14 "NotUsed_9" 13 "NotUsed_8" 12 "NotUsed_7" 11 "NotUsed_6" 10 "NotUsed_5" 9 "NotUsed_4" 8 "NotUsed_3" 7 "NotUsed_2" 6 "NotUsed_1" 5 "NonInterruptible_Pending" 4 "NonInterruptible_Config" 3 "NonInterruptible_ER" 2 "NonInterruptible_AB" 1 "Interruptible_AB" 0 "NoInVehicleOta";
VAL_ 810 OBCCSerial_D_Rq 3 "PresentAndProvisioned" 2 "PresentAndProvAlertAck" 1 "PresentAndUnprovisioned" 0 "NotPresent";
VAL_ 810 TlghtTest_D_RqArb 3 "TestEndAcknowledge" 2 "StartTest" 1 "StopTest" 0 "Null";
VAL_ 810 ChrgrPncSustn_B_Rq 1 "Active" 0 "Inactive";
VAL_ 810 NtfyDrvTrgtDist_L_Rq 4095 "Trip_dist_alert_disabled" 0 "Inactive";
VAL_ 810 NtfyDrvSocLvl1_Pc_Rq 127 "TargetSOCNotificationAlert" 0 "Inactive";
VAL_ 810 PtRmtRprt_D_Stat 15 "NotUsed_4" 14 "NotUsed_3" 13 "NotUsed_2" 12 "NotUsed_1" 11 "SettingUpdated" 10 "FastChargeComplete" 9 "ChargeNotOccurring" 8 "OneTimeSocReached" 7 "BatteryTemperatureRemind" 6 "ReducedPerformance" 5 "LimitedPerformance" 4 "ChargeFault" 3 "ChargeComplete" 2 "VehiclePreconditioned" 1 "TripDistanceAchieved" 0 "NoReportRequest";
VAL_ 810 ChrgrPncEnbl_D_Rq 3 "NotUsed" 2 "Enable" 1 "Disable" 0 "Null";
VAL_ 810 ExtLghtDsply_B_StatArb 1 "On" 0 "Off";
VAL_ 810 ExtLghtRight_D_RqOta 7 "NotUsed" 6 "PressToOn3" 5 "PressToOff3" 4 "PressToOn2" 3 "PressToOff2" 2 "PressToOn1" 1 "PressToOff1" 0 "Reset";
VAL_ 810 ExtLghtRear_D_RqOta 7 "NotUsed" 6 "PressToOn3" 5 "PressToOff3" 4 "PressToOn2" 3 "PressToOff2" 2 "PressToOn1" 1 "PressToOff1" 0 "Reset";
VAL_ 810 ExtLghtLeft_D_RqOta 7 "NotUsed" 6 "PressToOn3" 5 "PressToOff3" 4 "PressToOn2" 3 "PressToOff2" 2 "PressToOn1" 1 "PressToOff1" 0 "Reset";
VAL_ 810 ExtLghtFront_D_RqOta 7 "NotUsed" 6 "PressToOn3" 5 "PressToOff3" 4 "PressToOn2" 3 "PressToOff2" 2 "PressToOn1" 1 "PressToOff1" 0 "Reset";
VAL_ 550 PtWakeupActv1_B_Rq 1 "Wake_up_Powertrain_via_HW" 0 "Don_t_Wake_Up_Powertrain";
VAL_ 639 OfbChrgPrflUpdate_B_Rq 1 "Request" 0 "NoRequest";
VAL_ 639 OfbChrgClearAll_B_Rq 1 "Request" 0 "NoRequest";
VAL_ 639 OfbChrgGoTTouch_D_Rq 3 "NotUsed" 2 "On" 1 "Off" 0 "Null";
VAL_ 639 OfbChrgGoTPrcond_D_Rq 3 "High" 2 "Medium" 1 "Low" 0 "Off";
VAL_ 639 OfbChrgGoTOn_D_Rq 3 "NotUsed" 2 "On" 1 "Off" 0 "Null";
VAL_ 639 OfbChrgGoTMnte_D_Rq 15 "NotUsed_4" 14 "NotUsed_3" 13 "NotUsed_2" 12 "NotUsed_1" 11 "Minute_55" 10 "Minute_50" 9 "Minute_45" 8 "Minute_40" 7 "Minute_35" 6 "Minute_30" 5 "Minute_25" 4 "Minute_20" 3 "Minute_15" 2 "Minute_10" 1 "Minute_5" 0 "Minute_0";
VAL_ 639 OfbChrgGoTHr_T_Rq 31 "Faulty" 30 "NoDataExists";
VAL_ 639 OfbChrgGoTExtHtr_D_Rq 3 "NotUsed" 2 "On" 1 "Off" 0 "Null";
VAL_ 639 OfbChrgGoTDelete_B_Rq 1 "Request" 0 "NoRequest";
VAL_ 639 OfbChrgGoTUpdate_B_Rq 1 "Request" 0 "NoRequest";
VAL_ 530 OfbChrgToPcWknd_D_Actl 7 "Percent_50" 6 "Percent_60" 5 "Percent_70" 4 "Percent_80" 3 "Percent_85" 2 "Percent_90" 1 "Percent_95" 0 "Percent_100";
VAL_ 530 OfbChrgToPcWkdy_D_Actl 7 "Percent_50" 6 "Percent_60" 5 "Percent_70" 4 "Percent_80" 3 "Percent_85" 2 "Percent_90" 1 "Percent_95" 0 "Percent_100";
VAL_ 530 OfbChrgSetNow_D_Rq 3 "NotUsed" 2 "On" 1 "Off" 0 "Null";
VAL_ 530 OfbChrgSetDelete_B_Rq 1 "Request" 0 "NoRequest";
VAL_ 530 OfbChrgLocIdUns_B_Rq 1 "Request" 0 "NoRequest";
VAL_ 1142 ConsTipV_No_Dsply 1023 "Faulty" 1022 "NoDataExists";
VAL_ 817 ChildLckMde_B_Stat 1 "Enable" 0 "Disable";
VAL_ 817 VehLckInd_D_Rq 3 "NotUsed" 2 "On_Day" 1 "On_Night" 0 "Off";
VAL_ 817 DrTgateOpen_B_Rq 1 "Open" 0 "Null";
VAL_ 817 DrTgateExtSwMde_B_Stat 1 "Enable" 0 "Disable";
VAL_ 817 Remote_Device_Feedback 7 "Unused3" 6 "Unused2" 5 "Unused1" 4 "Shutdown" 3 "Running" 2 "Starting" 1 "Acknowledge" 0 "Null";
VAL_ 817 Veh_Lock_Requestor 31 "Unused8" 30 "Unused7" 29 "Unused6" 28 "Rgtm_Shutlock_Switch" 27 "Boundary_Alert" 26 "Transit_Vehicle_Relock" 25 "Transit_Cargo_Relock" 24 "Transit_Ajar_Lock" 23 "Diagnostics" 22 "Console_Lock" 21 "Child_Lock" 20 "Double_Lock" 19 "Passive_Pasenger" 18 "Passive_Driver" 17 "Slam_Lock_Protect" 16 "SYNC" 15 "Passport" 14 "Passive_Smart_Unlock" 13 "Autorelock" 12 "RemoteStart" 0 "Null" 1 "Autolock" 11 "Smart_Unlock" 10 "Sliding_Door" 9 "Passive" 8 "Remote" 7 "Programming" 6 "Powerslide" 5 "Keypad" 4 "Key_Cylinder" 3 "Interior" 2 "Auto_Unlock";
VAL_ 817 R_Pwr_Sliding_Dr_Rqst 1 "Active" 0 "Null";
VAL_ 817 Power_Liftgate_Rqst 1 "Active" 0 "Null";
VAL_ 817 Power_Decklid_Rqst 1 "Active" 0 "Null";
VAL_ 817 L_Pwr_Sliding_Dr_Rqst 1 "Active" 0 "Null";
VAL_ 817 Veh_Lock_Sub_Id 15 "Unused7" 14 "Unused6" 13 "Unused5" 12 "Unused4" 11 "Unused3" 10 "Unused2" 9 "Unused1" 8 "Customer_8" 7 "Customer_7" 6 "Customer_6" 5 "Customer_5" 4 "Customer_4" 3 "Customer_3" 2 "Customer_2" 1 "Customer_1" 0 "Null";
VAL_ 817 Veh_Lock_Status 3 "UNLOCK_DRV" 2 "UNLOCK_ALL" 1 "LOCK_ALL" 0 "LOCK_DBL";
VAL_ 817 ChildLck_D_Dsply 3 "NOT_SUPPORTED" 2 "ERROR" 1 "CHILD_UNLOCK" 0 "CHILD_LOCK";
VAL_ 817 WindowLockout_B_Stat 1 "Locked" 0 "Unlock";
VAL_ 817 Lockmsgtxt_D_Rq 7 "MSG7" 6 "MSG6" 5 "MSG5" 4 "MSG4" 3 "MSG3" 2 "MSG2" 1 "MSG1" 0 "NO_WARNING";
VAL_ 817 FobComm_D_Stat 3 "NotUsed" 2 "RemEngStartOK" 1 "RemEngStartFail" 0 "Null";
VAL_ 817 LockInhibit 1 "Inhibit" 0 "No_Inhibit";
VAL_ 879 WndwRearHeat_I_Actl 2047 "Faulty";
VAL_ 879 WndwRearHeat_D_Stat 7 "NotUsed" 6 "FetLiftLimitReached" 5 "FetOpenCircuit" 4 "FetOutputShortToPower" 3 "FetOutputShortToGround" 2 "FetNotControlled" 1 "OnPowerToLoad" 0 "OffNoPowerToLoad";
VAL_ 878 DcacGfciTest_B_Rq 1 "Pressed" 0 "Not_Pressed";
VAL_ 878 DcacOut_Pw_DsplyMx 1023 "Faulty";
VAL_ 878 DcacOut1_Pw_Dsply 63 "Faulty";
VAL_ 878 DcacOut2_Pw_Dsply 63 "Faulty";
VAL_ 878 DcacHw_D_Confg 15 "NotUsed_11" 14 "NotUsed_10" 13 "NotUsed_9" 12 "NotUsed_8" 11 "NotUsed_7" 10 "NotUsed_6" 9 "NotUsed_5" 8 "NotUsed_4" 7 "NotUsed_3" 6 "NotUsed_2" 5 "NotUsed_1" 4 "Power_2300W" 3 "Power_7200W" 2 "Power_2400W" 1 "Power_2000W" 0 "NoDcacHardware";
VAL_ 878 DcacFaltMsgTxt_D_Rq 15 "NotUsed" 14 "OvercurrentLP" 13 "EngineRun" 12 "Service" 11 "NotAvailable" 10 "PlugWarn" 9 "PlugWarnDrive" 8 "BreakerC" 7 "BreakerB" 6 "BreakerA" 5 "FuelLow" 4 "AcOnOutput" 3 "Temperature" 2 "Gfci" 1 "Overcurrent" 0 "Ok";
VAL_ 878 DcacLoFuelMsgTxt_D_Rq 31 "Minute_31" 30 "Minute_30" 29 "Minute_29" 28 "Minute_28" 27 "Minute_27" 26 "Minute_26" 25 "Minute_25" 24 "Minute_24" 23 "Minute_23" 22 "Minute_22" 21 "Minute_21" 20 "Minute_20" 19 "Minute_19" 18 "Minute_18" 17 "Minute_17" 16 "Minute_16" 15 "Minute_15" 14 "Minute_14" 13 "Minute_13" 12 "Minute_12" 11 "Minute_11" 10 "Minute_10" 9 "Minute_9" 8 "Minute_8" 7 "Minute_7" 6 "Minute_6" 5 "Minute_5" 4 "Minute_4" 3 "Minute_3" 2 "Minute_2" 1 "Minute_1" 0 "Ok";
VAL_ 878 DcacEngOnMsgTxt_D_Rq 3 "NotUsed" 2 "DisplayQuestion" 1 "DisplayWarning" 0 "Ok";
VAL_ 878 DcacElPw_D_Stat 3 "NotUsed" 2 "High" 1 "Low" 0 "Off";
VAL_ 878 PwBedPnlEnbl_B_Rq 1 "Enable" 0 "Disable";
VAL_ 878 DcacOn_B_Rq 1 "Enable" 0 "Disable";
VAL_ 878 DcacSys_B_Falt 1 "Yes" 0 "No";
VAL_ 878 DcacLedCtl_D_Rq 3 "Fast_Flash" 2 "Slow_Flash" 1 "On" 0 "Off";
VAL_ 395 SelDrvMdeCnfm_D_Stat 3 "NotUsed" 2 "Accepted" 1 "NotAccepted" 0 "Null";
VAL_ 984 PersIndexIpma_D_Actl 7 "Unused_3" 6 "Unused_2" 5 "Unused_1" 4 "Vehicle" 3 "PERS_4" 2 "PERS_3" 1 "PERS_2" 0 "PERS_1";
VAL_ 984 AhbcRampingV_D_Rq 3 "Slow" 2 "Medium" 1 "Fast" 0 "Immediately";
VAL_ 984 LaActvStats_D_Dsply 31 "Unused7" 30 "LA_Off" 29 "Unused5" 28 "Unused4" 27 "Unused3" 26 "Unused2" 25 "Unused1" 24 "InerveneLeft_InterveneRght" 23 "WarnLeft_InterveneRight" 22 "SuppressLeft_InterveneRght" 21 "AvailLeft_InterveneRhtt" 20 "NoLeft_InterveneRight" 19 "InterveneLeft_WarnRight" 18 "WarnLeft_WarnRight" 17 "SuppressLeft_WarnRight" 16 "AvailableLeft_WarnRight" 15 "NoLeft_WarnRight" 14 "InterveneLeft_SuppressRght" 13 "WarnLeft_SuppressRight" 12 "SuppressLeft_SuppressRight" 11 "AvailLeft_SuppressRight" 10 "NoLeft_SuppressRight" 9 "InterveneLeft_AvailRight" 8 "WarnLeft_AvailRight" 7 "SuppressLeft_AvailRight" 6 "AvailableLeft_AvailRight" 5 "NoLeft_AvailableRight" 4 "InterveneLeft_NoRight" 3 "WarnLeft_NoRight" 2 "SuppressLeft_NoRight" 1 "AvailableLeft_NoRight" 0 "NoLeft_NoRight";
VAL_ 984 LaDenyStats_B_Dsply 1 "Unavailable" 0 "Available";
VAL_ 984 LaHandsOff_D_Dsply 3 "Suppressed" 2 "Level2" 1 "Level1" 0 "HandsOn";
VAL_ 984 CamraDefog_B_Req 1 "On" 0 "Off";
VAL_ 984 CamraStats_D_Dsply 3 "FrtCam_TempUnavailOther" 2 "FrtCam_TempUnavailVisibile" 1 "Front_Camera_Service_Reqd" 0 "Front_Camera_OK";
VAL_ 984 DasAlrtLvl_D_Dsply 5 "Alertness_Level_5" 4 "Alertness_Level_4" 3 "Alertness_Level_3" 2 "Alertness_Level_2" 1 "Alertness_Level_1" 0 "Undefined";
VAL_ 984 DasStats_D_Dsply 3 "Available" 2 "Unavailable_Other" 1 "Feedback_due_to_Speed" 0 "Off";
VAL_ 984 DasWarn_D_Dsply 3 "Undefined" 2 "Warning_Level_2" 1 "Warning_Level_1" 0 "No_Warning";
VAL_ 984 AhbHiBeam_D_Rq 3 "NotUsed" 2 "HighBeamRecommended" 1 "LowBeamRecommended" 0 "DeactivatedUnavailable";
VAL_ 985 LdwChime_B_Rq 1 "On" 0 "Off";
VAL_ 985 TsrRegionTxt_D_Stat 31 "Faulty" 30 "NotUsed_8" 29 "NotUsed_7" 28 "NotUsed_6" 27 "NotUsed_5" 26 "NotUsed_4" 25 "NotUsed_3" 24 "NotUsed_2" 23 "NotUsed_1" 22 "Region_22" 21 "Region_21" 20 "Region_20" 19 "Region_19" 18 "Region_18" 17 "Region_17" 16 "Region_16" 15 "Region_15" 14 "Region_14" 13 "Region_13" 12 "Region_12" 11 "Region_11" 10 "Region_10" 9 "Region_09" 8 "Region_08" 7 "Region_07" 6 "Region_06" 5 "Region_05" 4 "Region_04" 3 "Region_03" 2 "Region_02" 1 "Region_01" 0 "NotDetermined";
VAL_ 985 SblmPedCrossScnr_B_Stat 1 "Yes" 0 "No";
VAL_ 985 LongCtrlEnbl_D_Rq 7 "NotUsed_4" 6 "NotUsed_3" 5 "NotUsed_2" 4 "NotUsed_1" 3 "RemoteParking" 2 "Autohitch" 1 "AutomaticParking" 0 "None";
VAL_ 985 SblmRndAbtScnr_B_Stat 1 "Yes" 0 "No";
VAL_ 985 DasAlrtInfo_D_Dsply 3 "NotUsed" 2 "On" 1 "Off" 0 "Null";
VAL_ 985 IaccVLim_D_Rq 252 "NotUsed_2" 250 "LimitSpeed_250" 240 "LimitSpeed_240" 230 "LimitSpeed_230" 220 "LimitSpeed_220" 210 "LimitSpeed_210" 200 "LimitSpeed_200" 190 "LimitSpeed_190" 150 "LimitSpeed_150" 140 "LimitSpeed_140" 130 "LimitSpeed_130" 120 "LimitSpeed_120" 110 "LimitSpeed_110" 100 "LimitSpeed_100" 90 "LimitSpeed_90" 80 "LimitSpeed_80" 70 "LimitSpeed_70" 60 "LimitSpeed_60" 50 "LimitSpeed_50" 40 "LimitSpeed_40" 30 "LimitSpeed_30" 20 "LimtSpeed_20" 251 "NotUsed_1" 255 "Faulty" 254 "NoDataExists" 253 "NotUsed_3" 180 "LimitSpeed_180" 179 "LimitSpeed_179" 178 "LimitSpeed_178" 177 "LimitSpeed_177" 176 "LimitSpeed_176" 175 "LimitSpeed_175" 174 "LimitSpeed_174" 173 "LimitSpeed_173" 172 "LimitSpeed_172" 171 "LimitSpeed_171" 170 "LimitSpeed_170" 169 "LimitSpeed_169" 168 "LimitSpeed_168" 167 "LimitSpeed_167" 166 "LimitSpeed_166" 165 "LimitSpeed_165" 164 "LimitSpeed_164" 163 "LimitSpeed_163" 162 "LimitSpeed_162" 161 "LimitSpeed_161" 160 "LimitSpeed_160" 15 "LimitSpeed_15" 14 "LimitSpeed_14" 13 "LimitSpeed_13" 12 "LimitSpeed_12" 11 "LimitSpeed_11" 10 "LimitSpeed_10" 9 "LimitSpeed_9" 8 "LimitSpeed_8" 7 "LimitSpeed_7" 6 "LimitSpeed_6" 5 "LimitSpeed_5" 4 "LimitSpeed_4" 3 "LimitSpeed_3" 2 "LimitSpeed_2" 1 "LimitSpeed_1" 0 "LimitSpeed_0";
VAL_ 985 IaccVLimUnit_D_Rq 3 "NoDataExists" 2 "Mph" 1 "Kph" 0 "Null";
VAL_ 985 IsaVLim_D_Rq 252 "NotUsed_2" 250 "LimitSpeed_250" 240 "LimitSpeed_240" 230 "LimitSpeed_230" 220 "LimitSpeed_220" 210 "LimitSpeed_210" 200 "LimitSpeed_200" 190 "LimitSpeed_190" 150 "LimitSpeed_150" 140 "LimitSpeed_140" 130 "LimitSpeed_130" 120 "LimitSpeed_120" 110 "LimitSpeed_110" 100 "LimitSpeed_100" 90 "LimitSpeed_90" 80 "LimitSpeed_80" 70 "LimitSpeed_70" 60 "LimitSpeed_60" 50 "LimitSpeed_50" 40 "LimitSpeed_40" 30 "LimitSpeed_30" 20 "LimtSpeed_20" 251 "NotUsed_1" 255 "Faulty" 254 "NoDataExists" 253 "NotUsed_3" 180 "LimitSpeed_180" 179 "LimitSpeed_179" 178 "LimitSpeed_178" 177 "LimitSpeed_177" 176 "LimitSpeed_176" 175 "LimitSpeed_175" 174 "LimitSpeed_174" 173 "LimitSpeed_173" 172 "LimitSpeed_172" 171 "LimitSpeed_171" 170 "LimitSpeed_170" 169 "LimitSpeed_169" 168 "LimitSpeed_168" 167 "LimitSpeed_167" 166 "LimitSpeed_166" 165 "LimitSpeed_165" 164 "LimitSpeed_164" 163 "LimitSpeed_163" 162 "LimitSpeed_162" 161 "LimitSpeed_161" 160 "LimitSpeed_160" 15 "LimitSpeed_15" 14 "LimitSpeed_14" 13 "LimitSpeed_13" 12 "LimitSpeed_12" 11 "LimitSpeed_11" 10 "LimitSpeed_10" 9 "LimitSpeed_9" 8 "LimitSpeed_8" 7 "LimitSpeed_7" 6 "LimitSpeed_6" 5 "LimitSpeed_5" 4 "LimitSpeed_4" 3 "LimitSpeed_3" 2 "LimitSpeed_2" 1 "LimitSpeed_1" 0 "LimitSpeed_0";
VAL_ 985 SblmStopScnr_B_Stat 1 "Yes" 0 "No";
VAL_ 985 SblmYieldScnr_B_Stat 1 "Yes" 0 "No";
VAL_ 985 IsaVLimUnit_D_Rq 3 "NoDataExists" 2 "Mph" 1 "Kph" 0 "Null";
VAL_ 985 AdbDividedRoad_B_Stat 1 "Yes" 0 "No";
VAL_ 985 LcwaMsgTxt_D_Stat 3 "SodXFaulty" 2 "SodXBlocked" 1 "TrailerConnected" 0 "NoMessage";
VAL_ 985 AdbDrvSide_B_Stat 1 "Left_Hand_Traffic" 0 "Right_Hand_Traffic";
VAL_ 992 MsgCntrDsplyOp_D_Rq 7 "Unused_2" 6 "Unused_1" 5 "Copy" 4 "Restore" 3 "Upload" 2 "Set" 1 "Query" 0 "Null";
VAL_ 992 MsgCntrPersIndex_D_Rq 7 "Unused_3" 6 "Unused_2" 5 "Unused_1" 4 "Vehicle" 3 "PERS_4" 2 "PERS_3" 1 "PERS_2" 0 "PERS_1";
VAL_ 943 VehVActlAdas_D_Qf 3 "OK" 2 "Not_Within_Specifications" 1 "No_Data_Exists" 0 "Faulty";
VAL_ 943 AdasLcDistToObj_L_Actl 4095 "Faulty" 4094 "NoDataExists";
VAL_ 515 PtIgnSwtch_D_Stat 3 "Faulty" 2 "No_Data_Exists" 1 "On" 0 "Off";
VAL_ 1111 TrlrYawWActl_D_Qf 3 "OK" 2 "Not_Within_Specifications" 1 "No_Data_Exists" 0 "Faulty";
VAL_ 1111 TrlrYaw_W_Actl 65535 "Faulty" 65534 "NoDataExists";
VAL_ 1111 TrlrHitYaw_AnRate_Actl 4095 "Fault" 4094 "NoDataExists";
VAL_ 1111 TrlrHitchYaw_D_Stat 15 "Faulty" 14 "NotUsed_4" 13 "NotUsed_3" 12 "NotUsed_2" 11 "NotUsed_1" 10 "FaultyYrsuConnection" 9 "FaultyYrsu" 8 "HiConfdLrndAngle" 7 "LowConfdLrndAngle" 6 "HiConfdAngleMem" 5 "LowConfdAngleMem" 4 "InitNoTadAngle" 3 "InitInputs" 2 "TadTrlrDataOutOfRange" 1 "TadNotWithinSpecification" 0 "NoConnectionWithYrsu";
VAL_ 1111 TrlrHitchYaw_An_Actl 4095 "Faulty" 4094 "NoDataExists";
VAL_ 1106 TrlrSnsId_No_Actl -1 "Faulty_FFFFFFFFFFFF" -2 "NoDataExists_FFFFFFFFFFFE";
VAL_ 982 LatCtl_D2_Rq 7 "NotUsed_5" 6 "NotUsed_4" 5 "NotUsed_3" 4 "NotUsed_2" 3 "SafeRampOut" 2 "PathFollowingExtendedMode" 1 "PathFollowingLimitedMode" 0 "NoLateralControl";
VAL_ 982 HandsOffCnfm_B_Rq 1 "Active" 0 "Inactive";
VAL_ 982 LatCtlRampType_D_Rq 3 "Immediately" 2 "Fast" 1 "Medium" 0 "Slow";
VAL_ 982 LatCtlPrecision_D_Rq 3 "NotUsed2" 2 "NotUsed1" 1 "Precise" 0 "Comfortable";
VAL_ 1104 DrvEngageLevel_D_Stat 7 "Faulty" 6 "NotUsed_2" 5 "NotUsed_1" 4 "Disengaged" 3 "Distracted" 2 "Attentive" 1 "Invalid" 0 "NotDetermined";
VAL_ 1104 DrvImpLvlConfid_D_Stat 7 "Faulty" 6 "NotUsed" 5 "High" 4 "MediumHigh" 3 "Medium" 2 "LowMedium" 1 "Low" 0 "NotDetermined";
VAL_ 1104 DrvImpairLvl_D_Stat 15 "Faulty" 14 "NotUsed_5" 13 "NotUsed_4" 12 "NotUsed_3" 11 "NotUsed_2" 10 "NotUsed_1" 9 "Incapacitated" 8 "Asleep" 7 "Microsleep" 6 "MostDrowsy" 5 "Drowsy_4" 4 "Drowsy_3" 3 "Drowsy_2" 2 "LeastDrowsy" 1 "Alert" 0 "NotDetermined";
VAL_ 1104 DrvEngLvlConfid_D_Stat 7 "Faulty" 6 "NotUsed" 5 "High" 4 "MediumHigh" 3 "Medium" 2 "LowMedium" 1 "Low" 0 "NotDetermined";
VAL_ 1104 DrvCamPassIR_D_Stat 3 "Faulty" 2 "Blocked" 1 "Ok" 0 "TemporaryUnavailable";
VAL_ 1104 DrvCamera_D_Stat 3 "Faulty" 2 "Blocked" 1 "Ok" 0 "TemporaryUnavailable";
VAL_ 1104 DrvCamDrvIR_D_Stat 3 "Faulty" 2 "Blocked" 1 "Ok" 0 "TemporaryUnavailable";
VAL_ 1104 DrvAttentZone_D_Stat 15 "Faulty" 14 "NotUsed_5" 13 "NotUsed_4" 12 "NotUsed_3" 11 "NotUsed_2" 10 "NotUsed_1" 9 "PassengerSideWindow" 8 "DriverSideWindow" 7 "DriverSideMirror" 6 "RearviewMirror" 5 "PassengerSideMirror" 4 "Infotainment" 3 "Cluster" 2 "FrontWindshield" 1 "Other" 0 "NotDetermined";
VAL_ 1104 DrvAlertSt_D_Stat 3 "Faulty" 2 "EyesOffRoad" 1 "EyesOnRoad" 0 "NotDetermined";
VAL_ 1114 TrailCtlSwtch_B_Stat2 1 "Pressed" 0 "Not_Pressed";
VAL_ 1114 TrlBrkInitOut_D_Rq 3 "Heavy" 2 "Medium" 1 "Light" 0 "Null";
VAL_ 1116 TrlrAidSetup_D2_Rq 15 "NotUsed_9" 14 "NotUsed_8" 13 "NotUsed_7" 12 "NotUsed_6" 11 "NotUsed_5" 10 "NotUsed_4" 9 "NotUsed_3" 8 "NotUsed_2" 7 "NotUsed_1" 6 "CompleteSetup" 5 "ReturnToSetup" 4 "StickerNotCircled" 3 "ConfirmSetup" 2 "EndSetup" 1 "BeginSetup" 0 "Inactive";
VAL_ 1116 TrlrAidEnbl_D2_Rq 7 "NotUsed_4" 6 "NotUsed_3" 5 "NotUsed_2" 4 "NotUsed_1" 3 "Deactivate" 2 "ActivateTrg" 1 "ActivateTba" 0 "Inactive";
VAL_ 1116 TrlrRvrseCancl_B_Rq 1 "Cancel" 0 "Null";
VAL_ 1116 TrlrIdType_D_Stat 3 "Gooseneck" 2 "FifthWheel" 1 "Conventional" 0 "Null";
VAL_ 1116 TrlrAnOffstDir_D_Mem 3 "NotUSed" 2 "Right" 1 "Left_or_Center" 0 "Null";
VAL_ 1085 ULoRgenTestMde_B_Stat 1 "Active" 0 "Inactive";
VAL_ 1085 PwSrcULoOvrTe_B_Actl 1 "Yes" 0 "No";
VAL_ 1085 PwSrcULoFalt_D_Stat 3 "Fault_No_Output" 2 "Fault_Reduced_Output" 1 "Fault_NonSpecific" 0 "No_Fault";
VAL_ 1085 PwSrcULoDcnnt_B_Stat 1 "Loose_or_Disconnected" 0 "Connected";
VAL_ 1085 PwSrcULo_Pc_Mx 255 "Fault";
VAL_ 1085 PwSrcULoComm_B_Falt 1 "Fault" 0 "No_Fault";
VAL_ 1085 PwSrcULo_I_Mx 255 "Fault";
VAL_ 1085 PwSrcULo_I_Actl 255 "Fault";
VAL_ 981 AdbBrdrTop_An_Rq 255 "Faulty" 254 "NoDataExists";
VAL_ 981 AdbBrdrRight_L_Stat 511 "Faulty" 510 "NoDataExists";
VAL_ 981 AdbBrdrRight_An_Rq 1023 "Faulty" 1022 "NoDataExists";
VAL_ 981 AdbBrdrLeft_L_Stat 511 "Faulty" 510 "NoDataExists";
VAL_ 981 AdbBrdrLeft_An_Rq 1023 "Faulty" 1022 "NoDataExists";
VAL_ 981 AdbBrdrBottom_An_Rq 63 "Faulty" 62 "NoDataExists";
VAL_ 981 AdbBeam_D_Rq 7 "NotUsed_3" 6 "NotUsed_2" 5 "NotUsed_1" 4 "FullHighBeam" 3 "Spot_BothSide" 2 "Spot_OnlyRightSide" 1 "Spot_OnlyLeftSide" 0 "NoHighBeam";
VAL_ 791 EngAirFilt_B_RqReset 1 "Yes" 0 "No";
VAL_ 791 GpsElMdeSel_B_Rq 1 "On" 0 "Off";
VAL_ 791 LongTermReset_B_Rq 1 "On" 0 "Off";
VAL_ 791 DrvEffLvl_No_Stat 63 "Fault" 62 "NoDataExists";
VAL_ 868 BattRgenLoStat_D_Qlty 3 "OK" 2 "Not_Within_Spec" 1 "Eval_In_Progress" 0 "Faulty";
VAL_ 868 BattRgenLoPrtct_B_Stat 1 "Yes" 0 "No";
VAL_ 868 BattRgenLoDChrg_D_Stat 3 "StuckClosed" 2 "StuckOpen" 1 "Closed" 0 "Open";
VAL_ 868 BattRgenLoDchrg_B_Rq 1 "Yes" 0 "No";
VAL_ 868 BattRgenLoChrg_D_Stat 3 "StuckClosed" 2 "StuckOpen" 1 "Closed" 0 "Open";
VAL_ 868 BattRgenLoChrg_B_Rq 1 "Yes" 0 "No";
VAL_ 868 BattRgenLo_B_Falt 1 "Yes" 0 "No";
VAL_ 867 BattRgenLoBalnc_B_Rq 1 "Yes" 0 "No";
VAL_ 867 BattRgenLo_Te_Actl 255 "Fault";
VAL_ 865 BattRgenLo_U_Actl 2047 "Faulty";
VAL_ 865 BattRgenLo_I_Actl 65535 "Faulty";
VAL_ 1144 WakeAlarm0_B_Typ 1 "CanAndEcuDriveCircuit" 0 "CanOnly";
VAL_ 1144 PreCondBatt_B_Actl 1 "On" 0 "Off";
VAL_ 1144 HtrnDcdcDis_B_Rq 1 "Yes" 0 "No";
VAL_ 1144 ChrgNowEvnt_B_Stat 1 "Active" 0 "Inactive";
VAL_ 1144 CabinDrvSustn_B_Rq 1 "Active" 0 "Inactive";
VAL_ 1144 BattChrgTrgtSoC_D_Rq 7 "Percent_50" 6 "Percent_60" 5 "Percent_70" 4 "Percent_80" 3 "Percent_85" 2 "Percent_90" 1 "Percent_95" 0 "Percent_100";
VAL_ 1144 CabnEvapSovFront_B_Rq 1 "On" 0 "Off";
VAL_ 1144 HeatCoreSovRear_B_Rq 1 "On" 0 "Off";
VAL_ 1144 BattChlrSov_B_Rq 1 "On" 0 "Off";
VAL_ 1144 CabnEvapSovRear_B_Rq 1 "On" 0 "Off";
VAL_ 1144 BrkAppl_D_RqPt 3 "BrakesSlowRelease" 2 "BrakesFastRelease" 1 "BrakesEngage" 0 "NotActive";
VAL_ 1144 HtrnCnnctPwr_B_Stat 1 "Asserted" 0 "NotAsserted";
VAL_ 1144 PtcHtr_D_Stat 3 "Faulty" 2 "NotUsed" 1 "On" 0 "Off";
VAL_ 1144 HtrnClntFlw_D_Rq 3 "High" 2 "Medium" 1 "Low" 0 "Off";
VAL_ 1144 BattTracDrvSustn_B_Rq 1 "Active" 0 "Inactive";
VAL_ 1144 BattTracClntVlv_B_Rq 1 "On" 0 "Off";
VAL_ 1141 OfbChrgSetSync_D_Stat 3 "Fail" 2 "Success" 1 "InProgress" 0 "NoSyncInProgress";
VAL_ 1141 PtRmtRprt_D_Rq 15 "NotUsed_4" 14 "NotUsed_3" 13 "NotUsed_2" 12 "PlugInToMaintain12vBattery" 11 "SettingUpdated" 10 "FastChargeComplete" 9 "ChargeNotOccurring" 8 "OneTimeSocReached" 7 "BatteryTemperatureReminder" 6 "ReducedPerformance" 5 "LimitedPerformance" 4 "ChargeFault" 3 "ChargeComplete" 2 "VehiclePreconditioned" 1 "TripDistanceAchieved" 0 "NoReportRequest";
VAL_ 1141 NtfctnConflict1_D_Rq 7 "NotUsed5" 6 "NotUsed4" 5 "NotUsed3" 4 "NotUsed2" 3 "NotUsed1" 2 "Clonflict_Exists" 1 "No_Conflict" 0 "Invalid";
VAL_ 1140 RgenEvntLvl_Pc_Dsply 1023 "Fault" 1022 "NoDataExists";
VAL_ 1140 BrkEvntComplt_B_Dsply 1 "On" 0 "Off";
VAL_ 1140 PreCondStat_D_Dsply 7 "Reserved3" 6 "Reserved2" 5 "Reserved1" 4 "Faulted" 3 "Complete" 2 "In_Progress" 1 "Scheduled" 0 "Not_Scheduled";
VAL_ 1139 BattChrgTrgtLMax_T_Est 2047 "Faulty" 2046 "NoDataExists";
VAL_ 1139 ActChrgStrtYr_No_Actl 31 "Invalid";
VAL_ 1139 ActChrgStrtMin_No_Actl 63 "Invalid" 62 "Unknown";
VAL_ 1139 ActChrgStrtHr_No_Actl 31 "Invalid" 30 "Unknown";
VAL_ 1139 ActChrgStrtDay_No_Actl 31 "Invalid";
VAL_ 1139 ActChrgStrMnth_No_Actl 15 "Invalid";
VAL_ 1138 BattChrgTrgtLMin_T_Est 2047 "Faulty" 2046 "NoDataExists";
VAL_ 1138 ActChrgEndYr_No_Actl 31 "Invalid";
VAL_ 1138 ActChrgEndMnth_No_Actl 15 "Invalid";
VAL_ 1138 ActChrgEndMin_No_Actl 63 "Invalid" 62 "Unknown";
VAL_ 1138 ActChrgEndHr_No_Actl 31 "Invalid" 30 "Unknown";
VAL_ 1138 ActChrgEndDay_No_Actl 31 "Invalid";
VAL_ 1089 Mtr2Aout_W_ActlMntr 1023 "Faulty";
VAL_ 1089 Inv1_Te_Actl 255 "Faulty" 254 "NoDataExists";
VAL_ 1089 MtrTrac2Coil_Te_Actl 255 "Faulty" 254 "NoDataExists";
VAL_ 1089 MtrTrac2Falt_B_Stat 1 "Active" 0 "Inactive";
VAL_ 1089 MtrTrac2TeAlrm_B_Stat 1 "Active" 0 "Inactive";
VAL_ 1089 Mtr2CntlTeAlrm_B_Stat 1 "Active" 0 "Inactive";
VAL_ 1089 MtrTrac2Inv_Te_Actl 255 "Faulty" 254 "NoDataExists";
VAL_ 1089 MtrTrac2_I_Actl 65535 "Faulty";
VAL_ 1088 ChrgTMatch_B_Stat 1 "True" 0 "False";
VAL_ 1088 ChrgStat_D2_Dsply 15 "NotUsed_2" 14 "NotUsed_1" 13 "ChargeTargetReached" 12 "DriveConditioning" 11 "CabinPreconditioning" 10 "ChargingSystemMaintain" 9 "ChargingInductive" 8 "ChargingDCFastChange" 7 "ChargingAC" 6 "ChargeScheduled" 5 "EvsePaused" 4 "EvseNotDetected" 3 "EvseNotCompatible" 2 "FaultOutsideCar" 1 "FaultInsideCar" 0 "NotReady";
VAL_ 1088 HvacPrecondRecirc_D_Rq 3 "Last_User_Setting" 2 "Auto" 1 "Recirc" 0 "Outside";
VAL_ 1088 HvacPrecondMode2_D_Rq 15 "NotUsed4" 14 "NotUsed3" 13 "NotUsed2" 12 "NotUsed1" 11 "Last_User_Settings" 10 "Auto" 9 "Max_Defrost" 8 "Windshield_Panel_Floor" 7 "Windshield_Panel" 6 "Windshield" 5 "Windshield_Floor" 4 "Floor" 3 "Panel_Floor" 2 "Panel" 1 "MAX_AC" 0 "Off";
VAL_ 1088 HvacPrecondBlwr2_D_Rq 15 "NotUsed6" 14 "NotUsed5" 13 "NotUsed4" 12 "NotUsed3" 11 "NotUsed2" 10 "NotUsed1" 9 "Last_User_Setting" 8 "Auto" 7 "Speed7" 6 "Speed6" 5 "Speed5" 4 "Speed4" 3 "Speed3" 2 "Speed2" 1 "Speed1" 0 "Off";
VAL_ 1088 HvacPrecondAC_D_Rq 3 "Last_User_Setting" 2 "Auto" 1 "On" 0 "Off";
VAL_ 1088 BattChrgInhbt_D_Rq 3 "MaintainTargetSoc" 2 "NotUsed" 1 "InhibitChargingThermal" 0 "Enable_Charging";
VAL_ 1040 ElCmprEnbl_B_Rq 1 "Enable" 0 "Disable";
VAL_ 1016 ChrgGoTElement_B_Dsply 1 "Yes" 0 "No";
VAL_ 1016 ChrgGoTTouchEnbl_B_Rq 1 "Request" 0 "NoRequest";
VAL_ 1016 ChrgGoTTouch_B_Stat 1 "On" 0 "Off";
VAL_ 1016 ChrgGoTPrcond_D_Stat 3 "High" 2 "Medium" 1 "Low" 0 "Off";
VAL_ 1016 ChrgGoTMnte_D_Stat 15 "NotUsed_4" 14 "NotUsed_3" 13 "NotUsed_2" 12 "NotUsed_1" 11 "Minute_55" 10 "Minute_50" 9 "Minute_45" 8 "Minute_40" 7 "Minute_35" 6 "Minute_30" 5 "Minute_25" 4 "Minute_20" 3 "Minute_15" 2 "Minute_10" 1 "Minute_5" 0 "Minute_0";
VAL_ 1016 ChrgGoTHr_T_Stat 31 "Faulty" 30 "NoDataExists";
VAL_ 1016 ChrgGoTExtHtrEnbl_B_Rq 1 "Request" 0 "NoRequest";
VAL_ 1016 ChrgGoTExtHtr_B_Stat 1 "On" 0 "Off";
VAL_ 1016 ChrgGoTAllOn_B_Stat 1 "On" 0 "Off";
VAL_ 1013 ChrgToPcWkndSav_D_Stat 7 "Percent_50" 6 "Percent_60" 5 "Percent_70" 4 "Percent_80" 3 "Percent_85" 2 "Percent_90" 1 "Percent_95" 0 "Percent_100";
VAL_ 1013 ChrgToPcWkdySav_D_Stat 7 "Percent_50" 6 "Percent_60" 5 "Percent_70" 4 "Percent_80" 3 "Percent_85" 2 "Percent_90" 1 "Percent_95" 0 "Percent_100";
VAL_ 1013 ChrgNowEnbl_B_Saved 1 "On" 0 "Off";
VAL_ 1013 ChrgLocIdUnsAck_B_Stat 1 "Yes" 0 "No";
VAL_ 1012 ChrgNowCurnt_B_Dsply 1 "On" 0 "Off";
VAL_ 1012 ChrgLocSaved_B_Dsply 1 "Yes" 0 "No";
VAL_ 1012 ChrgLocLongPostv_B_Sav 1 "Yes" 0 "No";
VAL_ 1012 ChrgLocLattPostv_B_Sav 1 "Yes" 0 "No";
VAL_ 1011 ChrgLocLongPostv_B_Uns 1 "Yes" 0 "No";
VAL_ 1011 ChrgLocLattPostv_B_Uns 1 "Yes" 0 "No";
VAL_ 871 BattElecPerf_D_Actl 7 "NotUsed" 6 "Hot_Batt_Severe_Lim_Perf" 5 "Hot_Batt_Reduced_Perf" 4 "Hot_Batt_Close_to_lim_Per" 3 "Cold_Batt_Severe_Lim_Perf" 2 "Cold_Batt_Reduced_Perf" 1 "Cold_Batt_Close_to_lim_Pe" 0 "Ok_no_message_displayed";
VAL_ 871 BattChrgTrgtLPt_T_Est 2047 "Faulty" 2046 "NoDataExists";
VAL_ 871 BattChrgTrgSocPt_T_Est 2047 "Faulty" 2046 "NoDataExists";
VAL_ 871 BattChrgCmpltPt_T_Est 2047 "Faulty" 2046 "NoDataExists";
VAL_ 786 RgenTrip_L_Dsply 65535 "Fault" 65534 "NoDataExists";
VAL_ 786 ChrgStat_D_Dsply 7 "NotUsed" 6 "Complete" 5 "Scheduled" 4 "In_Progress" 3 "Fault_Outside_Car" 2 "Fault_Inside_Car" 1 "Fault_Unknown_Location" 0 "Not_Ready";
VAL_ 72 immoTarget2Status 7 "Unused4" 6 "Unused3" 5 "Unused2" 4 "Unused1" 3 "DISABLED_RESET   " 2 "ENABLED_NONMOTIVE_START" 1 "ENABLED_MOTIVE_START" 0 "DISABLED";
VAL_ 72 immoTarget2Cmd 7 "Unused4" 6 "Unused3" 5 "Unused2" 4 "Unused1" 3 "TARGET1_IDBLOCK2" 2 "TARGET1_IDBLOCK1" 1 "CHALLENGE" 0 "IDLE";
VAL_ 912 CabnEvapSovFront_D_Stat 7 "NotUsed_1" 6 "FetLifeLimitReached" 5 "FetOpenCircuit" 4 "FetOutputShortToPower" 3 "FetOutputShortToGround" 2 "FetNotControlled" 1 "OnPowerToLoad" 0 "OffNoPowerToLoad";
VAL_ 912 BattChlrSov_D_Stat 7 "NotUsed_1" 6 "FetLifeLimitReached" 5 "FetOpenCircuit" 4 "FetOutputShortToPower" 3 "FetOutputShortToGround" 2 "FetNotControlled" 1 "OnPowerToLoad" 0 "OffNoPowerToLoad";
VAL_ 912 BattTracClntVlv_D_Stat 7 "NotUsed" 6 "FetLifeLimitReached" 5 "FetOpenCircuit" 4 "FetOutputShortToPower" 3 "FetOutputShortToGround" 2 "FetNotControlled" 1 "OnPowerToLoad" 0 "OffNoPowerToLoad";
VAL_ 874 AirCondCluOpen_D_Falt 3 "NotUsed" 2 "Pass" 1 "Fail" 0 "Not_Diagnose_Yet";
VAL_ 874 AirCondCluLife_D_Falt 3 "NotUsed" 2 "Pass" 1 "Fail" 0 "Not_Diagnose_Yet";
VAL_ 874 AirCondCluGnd_D_Falt 3 "NotUsed" 2 "Pass" 1 "Fail" 0 "Not_Diagnose_Yet";
VAL_ 874 AirCondClu_D_Stat 7 "NotUsed" 6 "FetLifeLimitReached" 5 "FetOpenCircuit" 4 "FetOutputShortToPower" 3 "FetOutputShortToGround" 2 "FetNotControlled" 1 "OnPowerToLoad" 0 "OffNoPowerToLoad";
VAL_ 874 AirCondCluBatt_D_Falt 3 "NotUsed" 2 "Pass" 1 "Fail" 0 "Not_Diagnose_Yet";
VAL_ 874 BattTracShrtGrnd_D_Falt 3 "NotUsed" 2 "Pass" 1 "Fail" 0 "Not_Diagnose_Yet";
VAL_ 874 BattTracShrtBatt_D_Falt 3 "NotUsed" 2 "Pass" 1 "Fail" 0 "Not_Diagnose_Yet";
VAL_ 874 BattTracOpnCirct_D_Falt 3 "NotUsed" 2 "Pass" 1 "Fail" 0 "Not_Diagnose_Yet";
VAL_ 874 BattTracLifeLim_D_Falt 3 "NotUsed" 2 "Pass" 1 "Fail" 0 "Not_Diagnose_Yet";
VAL_ 874 BattChlrShrtGrnd_D_Falt 3 "NotUsed" 2 "Pass" 1 "Fail" 0 "Not_Diagnose_Yet";
VAL_ 874 BattChlrShrtBatt_D_Falt 3 "NotUsed" 2 "Pass" 1 "Fail" 0 "Not_Diagnose_Yet";
VAL_ 874 BattChlrOpnCirct_D_Falt 3 "NotUsed" 2 "Pass" 1 "Fail" 0 "Not_Diagnose_Yet";
VAL_ 874 BattChlrLifeLim_D_Falt 3 "NotUsed" 2 "Pass" 1 "Fail" 0 "Not_Diagnose_Yet";
VAL_ 874 BattTracLow_D_Falt 3 "NotUsed" 2 "Pass" 1 "Fail" 0 "Not_Diagnose_Yet";
VAL_ 651 TelematicsSrvc_D_St 7 "NotUsed" 6 "NotifyNotActivatedYet" 5 "NotActivatedYet" 4 "NotifyExpired" 3 "Expired" 2 "ExpiringSoon" 1 "Active" 0 "Null";
VAL_ 651 EmgcyCallMute_D_Stat 7 "NotUsed4" 6 "NotUsed3" 5 "NotUsed2" 4 "NotUsed1" 3 "ManualEmergencyCallMute" 2 "AutomaticEmergencyCallMute" 1 "EmergencyCallUnmute" 0 "Null";
VAL_ 651 OfbChrgSetSync_D_Rq 3 "Fail" 2 "Success" 1 "InProgress" 0 "NoSyncInProgress";
VAL_ 529 OnbChrgToPcWknd_D_Actl 7 "Percent_50" 6 "Percent_60" 5 "Percent_70" 4 "Percent_80" 3 "Percent_85" 2 "Percent_90" 1 "Percent_95" 0 "Percent_100";
VAL_ 529 OnbChrgToPcWkdy_D_Actl 7 "Percent_50" 6 "Percent_60" 5 "Percent_70" 4 "Percent_80" 3 "Percent_85" 2 "Percent_90" 1 "Percent_95" 0 "Percent_100";
VAL_ 529 OnbChrgSetNow_D_Rq 3 "NotUsed" 2 "On" 1 "Off" 0 "Null";
VAL_ 529 OnbChrgSetDelete_B_Rq 1 "Request" 0 "NoRequest";
VAL_ 529 OnbChrgPrflUpdate_B_Rq 1 "Request" 0 "NoRequest";
VAL_ 529 OnbChrgLocIdUns_B_Rq 1 "Request" 0 "NoRequest";
VAL_ 66 immoControlCmd_T2 0 "IDLE" 1 "MOTIVE_START_RQST" 2 "NONMOTIVE_START_RQST" 3 "RQST_TARGET2_IDBLOCK1" 4 "RQST_TARGET2_IDBLOCK2" 5 "Unused" 6 "ECHO_TARGET2_IDBLOCK2" 7 "SHUTDOWN";
VAL_ 1124 GPS_Vdop 31 "Invalid" 30 "Unknown";
VAL_ 1124 GPS_Speed 255 "Invalid" 254 "Unknown";
VAL_ 1124 GPS_Sat_num_in_view 31 "Invalid" 30 "Unknown";
VAL_ 1124 GPS_MSL_altitude 4095 "Fault" 4094 "Unknown";
VAL_ 1124 GPS_Heading 65535 "Fault" 65534 "Unknown";
VAL_ 1124 GPS_Hdop 31 "Invalid" 30 "Unknown";
VAL_ 1124 GPS_dimension 2 "_3D" 1 "_2D" 0 "No_Fix";
VAL_ 1119 CoolFanDcdc_D_Rq 3 "High" 2 "Medium" 1 "Low" 0 "Off";
VAL_ 1119 DcdcClntFlw_D_Rq 3 "High" 2 "Medium" 1 "Low" 0 "Off";
VAL_ 1123 GpsUtcYr_No_Actl 31 "Fault";
VAL_ 1123 GpsUtcMnth_No_Actl 15 "Fault";
VAL_ 1123 GPS_UTC_seconds 63 "Fault" 62 "Unknown";
VAL_ 1123 GPS_UTC_minutes 63 "Fault" 62 "Unknown";
VAL_ 1123 GPS_UTC_hours 31 "Invalid" 30 "Unknown";
VAL_ 1123 GPS_Pdop 31 "Invalid" 30 "Unknown";
VAL_ 1123 GPS_Compass_direction 7 "NorthWest" 6 "West" 5 "SouthWest" 4 "South" 3 "SouthEast" 2 "East" 1 "NorthEast" 0 "North";
VAL_ 1123 GPS_Actual_vs_Infer_pos 1 "Inferred_Position" 0 "Actual_Postition";
VAL_ 1123 Gps_B_Falt 1 "Yes" 0 "No";
VAL_ 1122 GpsHsphLongEast_D_Actl 0 "Invalid" 1 "Eastern" 2 "Western" 3 "Fault";
VAL_ 1122 GpsHsphLattSth_D_Actl 3 "Fault" 2 "Northern" 1 "Southern" 0 "Invalid";
VAL_ 1122 GPS_Longitude_Minutes 63 "Fault" 62 "Unknown";
VAL_ 1122 GPS_Longitude_Min_dec 16383 "Invalid" 16382 "Unknown";
VAL_ 1122 GPS_Longitude_Degrees 511 "Fault" 510 "Unknown";
VAL_ 1122 GPS_Latitude_Minutes 63 "Fault" 62 "Unknown";
VAL_ 1122 GPS_Latitude_Min_dec 16383 "Invalid" 16382 "Unknown";
VAL_ 1122 GPS_Latitude_Degrees 255 "Invalid" 254 "Unknown";
VAL_ 1003 PersRecallSrc_D_Actl 7 "NotUsed_3" 6 "NotUsed_2" 5 "NotUsed_1" 4 "MemorySwitch" 3 "RemoteStart" 2 "KeyFob" 1 "CenterStack" 0 "Null";
VAL_ 1003 Pers4Key_D_Stat 3 "NotUsed_1" 2 "KeyUnAssociated" 1 "KeyAssociated" 0 "Null";
VAL_ 1003 Pers3Key_D_Stat 3 "NotUsed_1" 2 "KeyUnAssociated" 1 "KeyAssociated" 0 "Null";
VAL_ 1003 Pers2Key_D_Stat 3 "NotUsed_1" 2 "KeyUnAssociated" 1 "KeyAssociated" 0 "Null";
VAL_ 1003 Pers1Key_D_Stat 3 "NotUsed_1" 2 "KeyUnAssociated" 1 "KeyAssociated" 0 "Null";
VAL_ 1003 EmPrflNo_D_Stat 7 "NotUsed_3" 6 "NotUsed_2" 5 "NotUsed_1" 4 "Pers4" 3 "Pers3" 2 "Pers2" 1 "Pers1" 0 "Null";
VAL_ 1003 EmPrflKeyAssoc_D_Stat 7 "WrongDevice" 6 "KeyAssociateFailed" 5 "KeyAssociateSuccess" 4 "KeyAlreadyInUse" 3 "KeyDisassociated" 2 "KeyAssociationExited" 1 "KeyAssociationEntered" 0 "Null";
VAL_ 1003 VehKeyActv_D_Stat 15 "NotUsed7" 14 "NotUsed6" 13 "NotUsed5" 12 "NotUsed4" 11 "NotUsed3" 10 "NotUsed2" 9 "NotUsed1" 8 "Key8Active" 7 "Key7Active" 6 "Key6Active" 5 "Key5Active" 4 "Key4Active" 3 "Key3Active" 2 "Key2Active" 1 "Key1Active" 0 "NoKeyActive";
VAL_ 1003 PersNoPos_D_Actl 7 "Unused_3" 6 "Unused_2" 5 "Unused_1" 4 "Vehicle" 3 "PERS_4" 2 "PERS_3" 1 "PERS_2" 0 "PERS_1";
VAL_ 1003 PersSetupRestr_D_Actl 3 "Non_Moveable_Person" 2 "Moveable_Person" 1 "Vehicle" 0 "Factory";
VAL_ 1003 PersSetupAccessCtrl 1 "Limited" 0 "Full";
VAL_ 1003 PersConflict_D_Actl 1 "Conflict" 0 "No_Conflict";
VAL_ 1003 AssocConfirm_D_Actl 0 "None" 7 "Associate" 6 "Keycode_Rejected" 5 "Keycode_Accepted" 4 "In_Progress" 3 "Erase" 2 "Duplicate" 1 "Disassociate";
VAL_ 1003 PersNo_D_Actl 7 "Unused_3" 6 "Unused_2" 5 "NotDetermined" 4 "Vehicle" 3 "PERS_4" 2 "PERS_3" 1 "PERS_2" 0 "PERS_1";
VAL_ 994 PersStore_D_Rq 7 "Unused_2" 6 "Unused_1" 5 "Vehicle" 4 "PERS_4" 3 "PERS_3" 2 "PERS_2" 1 "PERS_1" 0 "Null";
VAL_ 994 Pers4OptIn_B_Stats 1 "OPTED_IN" 0 "NOT_OPTED_IN";
VAL_ 994 Pers3OptIn_B_Stats 1 "OPTED_IN" 0 "NOT_OPTED_IN";
VAL_ 994 Pers2OptIn_B_Stats 1 "OPTED_IN" 0 "NOT_OPTED_IN";
VAL_ 994 Pers1OptIn_B_Stats 1 "OPTED_IN" 0 "NOT_OPTED_IN";
VAL_ 994 CtrStkPersIndex_D_Actl 7 "Unused_3" 6 "Unused_2" 5 "Unused_1" 4 "Vehicle" 3 "PERS_4" 2 "PERS_3" 1 "PERS_2" 0 "PERS_1";
VAL_ 994 CtrStkDsplyOp_D_Rq 7 "Unused_2" 6 "Unused_1" 5 "Copy" 4 "Restore" 3 "Upload" 2 "Set" 1 "Query" 0 "Null";
VAL_ 778 PrkAidFront_D_RqDrv 2 "Status" 3 "NotUsed" 1 "Enabled" 0 "Disabled";
VAL_ 778 PrkAidAcsyRear_D_RqDrv 3 "NotUsed" 2 "On" 1 "Off" 0 "Null";
VAL_ 778 PrkAidAcsyFront_D_RqDrv 3 "NotUsed" 2 "On" 1 "Off" 0 "Null";
VAL_ 778 Cta_D_Rq 3 "Unused" 2 "NoDataExists" 1 "On" 0 "Off";
VAL_ 778 PrkAidRear_D_RqDrv 2 "Status" 3 "NotUsed" 1 "Enabled" 0 "Disabled";
VAL_ 778 SteEffort_D_Rq 7 "NotUsed_3" 6 "NotUsed_2" 5 "NotUsed_1" 4 "SpecialMode_2" 3 "SpecialMode_1" 2 "Comfort" 1 "Sport" 0 "Normal";
VAL_ 778 Sod_D_Rq 2 "BLIS_On_Second_Warning_ON" 1 "BLIS_On_Second_Warning_OFF" 0 "Off";
VAL_ 549 IPC_MyKeyVolLimit_St 0 "Invalid" 1 "Off" 2 "On";
VAL_ 549 HdcOn_B_Rq 1 "On" 0 "Off";
VAL_ 549 IPC_Attn_Info_Audio 7 "Unknown" 6 "Attenuation_6" 5 "Attenuation_5" 4 "Attenuation_4" 3 "Attenuation_3" 2 "Attenuation_2" 1 "Attenuation_1" 0 "No_Attenuation_of_Audio";
VAL_ 549 BeltminderAudioMute 2 "On" 1 "Off" 0 "Invalid";
VAL_ 549 Power_Up_Chime_Modules 1 "Active" 0 "Inactive";
VAL_ 549 Chime_Source 2 "Cluster" 1 "Infotainment_Sys" 0 "Invalid";
VAL_ 549 IPC_New_Attn_Event 1 "Active" 0 "Inactive";
VAL_ 551 PmCabnLvl_D_Stat 7 "NotUsed_1" 6 "Level_6_Worst" 5 "Level_5" 4 "Level_4" 3 "Level_3" 2 "Level_2" 1 "Level_1_Best" 0 "NotKnown";
VAL_ 551 PmCabn_D_Stat 3 "FilteringComplete" 2 "FilteringOn" 1 "FilteringOff" 0 "NotKnown";
VAL_ 551 Cntr_Plg_Mode_Cmd 1 "Enable" 0 "Disable";
VAL_ 551 ChrgCrdLckEnbl_B_Stat 1 "Enable" 0 "Disable";
VAL_ 551 PwRnngBoardT_D_Rq 3 "NotUsed" 2 "Timer2" 1 "Timer1" 0 "Inactive";
VAL_ 551 PwRnngBoardSwtch_D_Rq 3 "NotUsed" 2 "DeployUnlocked" 1 "AlwaysActive" 0 "Inactive";
VAL_ 551 PwRnngBoardMde_D_Rq 0 "Inactive" 1 "Off" 2 "Out" 3 "Auto";
VAL_ 551 Btt_L_Actl2 127 "Faulty" 126 "NoDataExists";
VAL_ 551 Rba_D_Rq 3 "NotUsed" 2 "On" 1 "Off" 0 "Null";
VAL_ 551 EmPrflNo_D_Rq 7 "NotUsed_3" 6 "NotUsed_2" 5 "NotUsed_1" 4 "Pers4" 3 "Pers3" 2 "Pers2" 1 "Pers1" 0 "Null";
VAL_ 551 EmPrflButtnAssoc_D_Rq 3 "NotUsed" 2 "ExitButtonAssociation" 1 "EnterButtonAssociation" 0 "Null";
VAL_ 551 EmPrflKeyAssoc_D_Rq 7 "NotUsed_3" 6 "DisassociatePhone" 5 "EnterPhoneAssociation" 4 "OverwriteKey" 3 "DisassociateKey" 2 "ExitKeyAssociation" 1 "EnterKeyAssociation" 0 "Null";
VAL_ 551 Em_D_Stat 3 "NotSupported" 2 "ProfilesOff" 1 "ProfilesOn" 0 "Null";
VAL_ 551 ChrgOvrdExitScrn_D_Rq 3 "NotUsed_1" 2 "Request_override" 1 "Do_not_request_override" 0 "Inactive";
VAL_ 1010 MbdblActv_B_RqAdas 1 "Yes" 0 "No";
VAL_ 1010 CbdblActv_B_RqAdas 1 "Yes" 0 "No";
VAL_ 1010 AdbUrbanArea_B_Stat 1 "Yes" 0 "No";
VAL_ 1070 BattULo24_D_Falt 3 "NotUsed" 2 "TemporaryFault" 1 "Fault" 0 "NoFault";
VAL_ 1070 BattULo24_Te_Actl 127 "Fault";
VAL_ 1070 BattULo24State_D_Qlty 3 "OK" 2 "Not_Within_Spec" 1 "Eval_In_Progress" 0 "Faulty";
VAL_ 1070 BattULo24_I_Actl 16383 "Faulty";
VAL_ 1070 BattULo24_B_Falt 1 "Yes" 0 "No";
VAL_ 1186 SelDrvMdeAwd2_D_Stat 31 "Faulty" 30 "NotUsed_17" 29 "NotUsed_16" 28 "NotUsed_15" 27 "NotUsed_14" 26 "NotUsed_13" 25 "NotUsed_12" 24 "NotUsed_11" 23 "NotUsed_10" 22 "NotUsed_9" 21 "NotUsed_8" 20 "NotUsed_7" 19 "NotUsed_6" 18 "NotUsed_5" 17 "EvLaterChargeMode" 16 "EvNowMode" 15 "TrackMode" 14 "RoughRoadMode" 13 "NotAvailable" 12 "HighSpeedDesertMode_Baja" 11 "SportAdaptiveMode" 10 "RockCrawlMode" 9 "MudRutsMode" 8 "SandMode" 7 "EconomyMode" 6 "GrassGravelSnow" 5 "TowHaulMode" 4 "SportMode" 3 "Normal_4L" 2 "Normal_4A" 1 "Normal_2H" 0 "NormalMode";
VAL_ 1186 RearDiffLckMsg_D_Rq 7 "Locker_Disabled" 6 "Locker_Enabled" 5 "Locker_Accel_Pedal" 4 "Speed4" 3 "Speed3" 2 "Spee2" 1 "Speed1" 0 "Normal__No_Message ";
VAL_ 1186 RearDiffLckLamp_D_Rq 3 "Not_Used" 2 "Flash" 1 "On" 0 "Off";
VAL_ 1186 RearDiffLck_Tq_Actl 4095 "Fault" 4094 "Unknown";
VAL_ 1186 RearDiffFalt_D_Stat 3 "Diff_Failed_Closed" 2 "Diff_Failed_Open" 1 "Fault_Non_Specific" 0 "No_Fault";
VAL_ 1186 LsdSrvcRqd_B_Rq 1 "On" 0 "Off";
VAL_ 611 AwdSys_D_Stat 3 "Faulty" 2 "NotUsed" 1 "_4x4_L_H_Active" 0 "_4x4_L_H_Inactive";
VAL_ 611 AwdStat_D_RqDsply 31 "NotUsed9" 30 "NotUsed8" 29 "NotUsed7" 28 "To_Engage_4x4_Release_Aped" 27 "To_Engage_4x4_Slow_To_3MPH" 26 "Shift_To_Neutral" 25 "Lkr_Mode_Unavail_TMS" 24 " _4x4_Mode_Unavail_TMS" 23 "Out_of_4Low_Crawl" 22 "AWD_PTU_Oil_Changed" 21 "Change_AWD_PTU_Oil" 20 "Neutral_Tow_Disabled" 19 "Neutral_Tow_Enabled" 18 "AWD_OFF" 17 "_4x4_Off_Road_Speed" 16 "_4x4_Extreme_Off_Road_Mode" 15 "_4x4_Exiting_Off_Road" 14 "_4x4_Off_Road_Mode" 10 "_4x4_Locked_Temporarily" 9 "Shift_In_Progress" 13 "Blocked_Shift_Assist" 12 "_4x4_Auto_Restored" 11 "_4x4_Disabled_Temporarily" 7 "Out_of_4Low__Neutral" 6 "Out_of_4Low__Brake" 5 "Out_of_4Low__Speed" 4 "Into_4Low__Clutch" 3 "Into_4Low__Neutral" 2 "Into_4Low__Brake" 1 "Into_4Low__Speed" 0 "Normal__No_Message" 8 "Out_of_4Low__Clutch";
VAL_ 611 AwdLck_D_Stat 9 "Undefined" 8 "Under_External_Torque_Ctrl" 7 "Torque_Limited_by_Cmd" 6 "Fully_Locked_by_Cmd" 5 "Disabled" 4 "Warning" 3 "Fault" 2 "Inactive" 1 "Completely_Opened_by_Cmd" 0 "OK";
VAL_ 611 AwdSrvcRqd_B_Rq 1 "On" 0 "Off";
VAL_ 611 NtrlTowAvail_B_Stat 1 "Available" 0 "NotAvailable";
VAL_ 611 AwdLck_Tq_Rq 4095 "Fault" 4094 "Unknown";
VAL_ 611 AwdOffRoadMode_D_Stats 3 "Invalid" 2 "Extreme_Off_Road" 1 "Off_Road" 0 "Normal_Mode";
VAL_ 611 AwdLoLamp_D_RqDsply 3 "Not_Used" 2 "Flash" 1 "On" 0 "Off";
VAL_ 611 AwdHiLamp_D_RqDsply 3 "Not_Used" 2 "Flash" 1 "On" 0 "Off";
VAL_ 611 AwdAutoLamp_D_RqDsply 3 "Not_Used" 2 "Flash" 1 "On" 0 "Off";
VAL_ 611 Awd2wdLamp_D_RqDsply 3 "Not_Used" 2 "Flash" 1 "On" 0 "Off";
VAL_ 611 AwdRnge_D_Actl 7 "Unknown" 6 "High_Range_2wd" 5 "High_Range_Auto" 4 "High_Range_Locked" 3 "Neutral" 2 "Low_Range_2wd" 1 "Low_Range_Auto" 0 "Low_Range_Locked";
VAL_ 1047 TrlrAidSetup_D2_Stat 7 "NotUsed_2" 6 "NotUsed_1" 5 "SetupAcquisitionSuccess" 4 "TbaTadMonitor" 3 "SetupStartAcquisition" 2 "SetupPrepForAcquisition" 1 "TbaActive" 0 "Null";
VAL_ 1047 TrlrAidEnbl_D2_Stat 7 "NotUsed_1" 6 "TbaActiveExpertActive" 5 "TbaActiveExpertAvail" 4 "TbaOffTrgActive" 3 "TbaOffTrgSetup" 2 "TbaSetup" 1 "TbaActive" 0 "Inactive";
VAL_ 1047 TrlrAidMsgTxt_D2_Rq 63 "Message63" 62 "Message62" 61 "Message61" 60 "Message60" 55 "Message55" 50 "Message50" 45 "Message45" 40 "Message40" 35 "Message35" 31 "Message31" 30 "Message30" 29 "Message29" 28 "Message28" 27 "Message27" 26 "Message26" 25 "Message25" 24 "Message24" 23 "Message23" 22 "Message22" 21 "Message21" 20 "Message20" 19 "Message19" 18 "Message18" 17 "Message17" 16 "Message16" 15 "Message15" 14 "Message14" 13 "Message13" 12 "Message12" 11 "Message11" 10 "Message10" 9 "Message9" 8 "Message8" 7 "Message7" 6 "Message6" 5 "Message5" 4 "Message4" 3 "Message3" 2 "Message2" 1 "Message1" 0 "NoMessage";
VAL_ 1047 EsaOn_B_Stat 1 "On" 0 "Off";
VAL_ 1047 SelDrvMdeSte_D_Stat 0 "NotAvailable" 1 "Available" 2 "TemporarilyNotAvailable" 3 "Faulty";
VAL_ 972 LatCtlSte_D_Stat 7 "NotUsed3" 6 "NotUsed2" 5 "NotUsed1" 4 "Denied" 3 "RampOut" 2 "ContLatControlInProgress" 1 "Available" 0 "Unavailable";
VAL_ 972 LatCtlLim_D_Stat 3 "LimitWithDriverActive" 2 "LimitReached" 1 "LimitClose" 0 "LimitNotReached";
VAL_ 972 LatCtlCpblty_D_Stat 3 "Faulty" 2 "ExtendedModeAvailable" 1 "LimitedModeAvailable" 0 "NoModeAvailable";
VAL_ 972 LsmcBrkDecelEnbl_D_Rq 3 "NotUsed2" 2 "NotUsed1" 1 "On" 0 "Off";
VAL_ 972 TjaHandsOnCnfdnc_B_Est 1 "High_Confidence" 0 "Low_Confidence";
VAL_ 972 LaHandsOff_B_Actl 1 "Hands_Off" 0 "Hands_On";
VAL_ 972 LaActDeny_B_Actl 1 "LA_Denied" 0 "LA_Not_Denied";
VAL_ 972 LaActAvail_D_Actl 3 "LKA_LCA_LDW_Avail" 2 "LCA_LKA_Avail_LDW_Suppress" 1 "LCA_LKA_Suppress_LDW_Avail" 0 "LCA_LKA_LDW_Suppress";
VAL_ 130 TrlrHitchLamp_D_Rqst 1 "On" 0 "Off";
VAL_ 130 VehVTrlrAid_B_Rq 1 "Request" 0 "NoRequest";
VAL_ 130 DrvSteActv_B_Stat 1 "Active" 0 "Inactive";
VAL_ 130 DrvSte_Tq_Actl 255 "Invalid" 254 "Unknown";
VAL_ 130 SteMdule_D_Stat 7 "NotUsed" 6 "EPAS_Failure3" 5 "EPAS_Failure2" 4 "System_Failure" 3 "EPAS_Shutdown" 2 "Normal_Op_Full_Assist" 1 "Normal_Op_Limited_Assist" 0 "EPAS_Initialization";
VAL_ 130 SteMdule_U_Meas 255 "Invalid";
VAL_ 130 SteMdule_I_Est 4095 "Invalid";
VAL_ 130 EPAS_Failure 3 "SERVICE_POWER_STEERING_NOW" 2 "SERVICE_POWER_STEERING" 1 "POWER_STRG_ASSIST_FAULT" 0 "EPAS_OK_NO_MESSAGE";
VAL_ 130 SteeringColumnTorque 255 "Invalid" 254 "Unknown";
VAL_ 130 SAPPAngleControlStat6 1 "RequestedAngleNotReached" 0 "RequestedAngleCanBeReached";
VAL_ 130 SAPPAngleControlStat5 1 "StrgColTorqueExceed_EAROn" 0 "ExternalSigContentOKforEAC";
VAL_ 130 SAPPAngleControlStat4 1 "SpeedLimitExceededEAROn" 0 "ExternalSigContentOKforEAC";
VAL_ 130 SAPPAngleControlStat3 1 "EARactiveNoReverseEngage" 0 "ExternalSigContentOKforEAC";
VAL_ 130 SAPPAngleControlStat2 1 "Rel_ExtSteeringAngleReqx" 0 "NoRel_ExtSteeringAngleReqx";
VAL_ 130 SAPPAngleControlStat1 3 "Fault" 2 "Active" 1 "Open" 0 "Closed";
VAL_ 126 StePw_B_Rq 1 "Yes" 0 "No";
VAL_ 126 StePinRelInit_An_Sns 65535 "Faulty" 65534 "NoDataExists";
VAL_ 126 StePinCompAnEst_D_Qf 3 "OK" 2 "Degraded" 1 "No_Data_Exists" 0 "Faulty";
VAL_ 1200 BrkHold_D_Stat 7 "NotUsed_3" 6 "NotUsed_2" 5 "NotUsed_1" 4 "HeldSecondary" 3 "HeldSecure" 2 "Held" 1 "Inactive" 0 "Off";
VAL_ 1200 HsaTrnAout_Tq_Rq 65535 "Fault" 65534 "Unknown";
VAL_ 1200 BrkBstrVac_P_Actl 127 "Invalid";
VAL_ 1200 YawStabilityIndex 511 "Fault" 510 "NoDataExists";
VAL_ 1200 BrkTot_Tq_RqDrv 8191 "Fault";
VAL_ 1200 HsaStat_D_Dsply 7 "NotUsed3" 6 "NotUsed2" 5 "NotUsed1" 4 "NotAvailable" 3 "SlowReleaseWithChime" 2 "SlowReleaseWithoutChime" 1 "Active" 0 "Inactive";
VAL_ 1102 SelDrvMdePos12_D_Stat 31 "Faulty" 30 "SelDrvMde31" 29 "SelDrvMde30" 28 "SelDrvMde29" 27 "SelDrvMde28" 26 "SelDrvMde27" 25 "SelDrvMde26" 24 "SelDrvMde25" 23 "SelDrvMde24" 22 "SelDrvMde23" 21 "SelDrvMde22" 20 "SelDrvMde21" 19 "SelDrvMde20" 18 "SelDrvMde19" 17 "SelDrvMde18" 16 "SelDrvMde17" 15 "SelDrvMde16" 14 "SelDrvMde15" 13 "SelDrvMde14" 12 "SelDrvMde13" 11 "SelDrvMde12" 10 "SelDrvMde11" 9 "SelDrvMde10" 8 "SelDrvMde09" 7 "SelDrvMde08" 6 "SelDrvMde07" 5 "SelDrvMde06" 4 "SelDrvMde05" 3 "SelDrvMde04" 2 "SelDrvMde03" 1 "SelDrvMde02" 0 "SelDrvMde01";
VAL_ 1102 SelDrvMdePos11_D_Stat 31 "Faulty" 30 "SelDrvMde31" 29 "SelDrvMde30" 28 "SelDrvMde29" 27 "SelDrvMde28" 26 "SelDrvMde27" 25 "SelDrvMde26" 24 "SelDrvMde25" 23 "SelDrvMde24" 22 "SelDrvMde23" 21 "SelDrvMde22" 20 "SelDrvMde21" 19 "SelDrvMde20" 18 "SelDrvMde19" 17 "SelDrvMde18" 16 "SelDrvMde17" 15 "SelDrvMde16" 14 "SelDrvMde15" 13 "SelDrvMde14" 12 "SelDrvMde13" 11 "SelDrvMde12" 10 "SelDrvMde11" 9 "SelDrvMde10" 8 "SelDrvMde09" 7 "SelDrvMde08" 6 "SelDrvMde07" 5 "SelDrvMde06" 4 "SelDrvMde05" 3 "SelDrvMde04" 2 "SelDrvMde03" 1 "SelDrvMde02" 0 "SelDrvMde01";
VAL_ 1102 SelDrvMdePos10_D_Stat 31 "Faulty" 30 "SelDrvMde31" 29 "SelDrvMde30" 28 "SelDrvMde29" 27 "SelDrvMde28" 26 "SelDrvMde27" 25 "SelDrvMde26" 24 "SelDrvMde25" 23 "SelDrvMde24" 22 "SelDrvMde23" 21 "SelDrvMde22" 20 "SelDrvMde21" 19 "SelDrvMde20" 18 "SelDrvMde19" 17 "SelDrvMde18" 16 "SelDrvMde17" 15 "SelDrvMde16" 14 "SelDrvMde15" 13 "SelDrvMde14" 12 "SelDrvMde13" 11 "SelDrvMde12" 10 "SelDrvMde11" 9 "SelDrvMde10" 8 "SelDrvMde09" 7 "SelDrvMde08" 6 "SelDrvMde07" 5 "SelDrvMde06" 4 "SelDrvMde05" 3 "SelDrvMde04" 2 "SelDrvMde03" 1 "SelDrvMde02" 0 "SelDrvMde01";
VAL_ 1102 SelDrvMdePos09_D_Stat 31 "Faulty" 30 "SelDrvMde31" 29 "SelDrvMde30" 28 "SelDrvMde29" 27 "SelDrvMde28" 26 "SelDrvMde27" 25 "SelDrvMde26" 24 "SelDrvMde25" 23 "SelDrvMde24" 22 "SelDrvMde23" 21 "SelDrvMde22" 20 "SelDrvMde21" 19 "SelDrvMde20" 18 "SelDrvMde19" 17 "SelDrvMde18" 16 "SelDrvMde17" 15 "SelDrvMde16" 14 "SelDrvMde15" 13 "SelDrvMde14" 12 "SelDrvMde13" 11 "SelDrvMde12" 10 "SelDrvMde11" 9 "SelDrvMde10" 8 "SelDrvMde09" 7 "SelDrvMde08" 6 "SelDrvMde07" 5 "SelDrvMde06" 4 "SelDrvMde05" 3 "SelDrvMde04" 2 "SelDrvMde03" 1 "SelDrvMde02" 0 "SelDrvMde01";
VAL_ 1102 SelDrvMdePos08_D_Stat 31 "Faulty" 30 "SelDrvMde31" 29 "SelDrvMde30" 28 "SelDrvMde29" 27 "SelDrvMde28" 26 "SelDrvMde27" 25 "SelDrvMde26" 24 "SelDrvMde25" 23 "SelDrvMde24" 22 "SelDrvMde23" 21 "SelDrvMde22" 20 "SelDrvMde21" 19 "SelDrvMde20" 18 "SelDrvMde19" 17 "SelDrvMde18" 16 "SelDrvMde17" 15 "SelDrvMde16" 14 "SelDrvMde15" 13 "SelDrvMde14" 12 "SelDrvMde13" 11 "SelDrvMde12" 10 "SelDrvMde11" 9 "SelDrvMde10" 8 "SelDrvMde09" 7 "SelDrvMde08" 6 "SelDrvMde07" 5 "SelDrvMde06" 4 "SelDrvMde05" 3 "SelDrvMde04" 2 "SelDrvMde03" 1 "SelDrvMde02" 0 "SelDrvMde01";
VAL_ 1102 SelDrvMdePos07_D_Stat 31 "Faulty" 30 "SelDrvMde31" 29 "SelDrvMde30" 28 "SelDrvMde29" 27 "SelDrvMde28" 26 "SelDrvMde27" 25 "SelDrvMde26" 24 "SelDrvMde25" 23 "SelDrvMde24" 22 "SelDrvMde23" 21 "SelDrvMde22" 20 "SelDrvMde21" 19 "SelDrvMde20" 18 "SelDrvMde19" 17 "SelDrvMde18" 16 "SelDrvMde17" 15 "SelDrvMde16" 14 "SelDrvMde15" 13 "SelDrvMde14" 12 "SelDrvMde13" 11 "SelDrvMde12" 10 "SelDrvMde11" 9 "SelDrvMde10" 8 "SelDrvMde09" 7 "SelDrvMde08" 6 "SelDrvMde07" 5 "SelDrvMde06" 4 "SelDrvMde05" 3 "SelDrvMde04" 2 "SelDrvMde03" 1 "SelDrvMde02" 0 "SelDrvMde01";
VAL_ 1102 SelDrvMdePos06_D_Stat 31 "Faulty" 30 "SelDrvMde31" 29 "SelDrvMde30" 28 "SelDrvMde29" 27 "SelDrvMde28" 26 "SelDrvMde27" 25 "SelDrvMde26" 24 "SelDrvMde25" 23 "SelDrvMde24" 22 "SelDrvMde23" 21 "SelDrvMde22" 20 "SelDrvMde21" 19 "SelDrvMde20" 18 "SelDrvMde19" 17 "SelDrvMde18" 16 "SelDrvMde17" 15 "SelDrvMde16" 14 "SelDrvMde15" 13 "SelDrvMde14" 12 "SelDrvMde13" 11 "SelDrvMde12" 10 "SelDrvMde11" 9 "SelDrvMde10" 8 "SelDrvMde09" 7 "SelDrvMde08" 6 "SelDrvMde07" 5 "SelDrvMde06" 4 "SelDrvMde05" 3 "SelDrvMde04" 2 "SelDrvMde03" 1 "SelDrvMde02" 0 "SelDrvMde01";
VAL_ 1102 SelDrvMdePos05_D_Stat 31 "Faulty" 30 "SelDrvMde31" 29 "SelDrvMde30" 28 "SelDrvMde29" 27 "SelDrvMde28" 26 "SelDrvMde27" 25 "SelDrvMde26" 24 "SelDrvMde25" 23 "SelDrvMde24" 22 "SelDrvMde23" 21 "SelDrvMde22" 20 "SelDrvMde21" 19 "SelDrvMde20" 18 "SelDrvMde19" 17 "SelDrvMde18" 16 "SelDrvMde17" 15 "SelDrvMde16" 14 "SelDrvMde15" 13 "SelDrvMde14" 12 "SelDrvMde13" 11 "SelDrvMde12" 10 "SelDrvMde11" 9 "SelDrvMde10" 8 "SelDrvMde09" 7 "SelDrvMde08" 6 "SelDrvMde07" 5 "SelDrvMde06" 4 "SelDrvMde05" 3 "SelDrvMde04" 2 "SelDrvMde03" 1 "SelDrvMde02" 0 "SelDrvMde01";
VAL_ 1102 SelDrvMdePos04_D_Stat 31 "Faulty" 30 "SelDrvMde31" 29 "SelDrvMde30" 28 "SelDrvMde29" 27 "SelDrvMde28" 26 "SelDrvMde27" 25 "SelDrvMde26" 24 "SelDrvMde25" 23 "SelDrvMde24" 22 "SelDrvMde23" 21 "SelDrvMde22" 20 "SelDrvMde21" 19 "SelDrvMde20" 18 "SelDrvMde19" 17 "SelDrvMde18" 16 "SelDrvMde17" 15 "SelDrvMde16" 14 "SelDrvMde15" 13 "SelDrvMde14" 12 "SelDrvMde13" 11 "SelDrvMde12" 10 "SelDrvMde11" 9 "SelDrvMde10" 8 "SelDrvMde09" 7 "SelDrvMde08" 6 "SelDrvMde07" 5 "SelDrvMde06" 4 "SelDrvMde05" 3 "SelDrvMde04" 2 "SelDrvMde03" 1 "SelDrvMde02" 0 "SelDrvMde01";
VAL_ 1102 SelDrvMdePos03_D_Stat 31 "Faulty" 30 "SelDrvMde31" 29 "SelDrvMde30" 28 "SelDrvMde29" 27 "SelDrvMde28" 26 "SelDrvMde27" 25 "SelDrvMde26" 24 "SelDrvMde25" 23 "SelDrvMde24" 22 "SelDrvMde23" 21 "SelDrvMde22" 20 "SelDrvMde21" 19 "SelDrvMde20" 18 "SelDrvMde19" 17 "SelDrvMde18" 16 "SelDrvMde17" 15 "SelDrvMde16" 14 "SelDrvMde15" 13 "SelDrvMde14" 12 "SelDrvMde13" 11 "SelDrvMde12" 10 "SelDrvMde11" 9 "SelDrvMde10" 8 "SelDrvMde09" 7 "SelDrvMde08" 6 "SelDrvMde07" 5 "SelDrvMde06" 4 "SelDrvMde05" 3 "SelDrvMde04" 2 "SelDrvMde03" 1 "SelDrvMde02" 0 "SelDrvMde01";
VAL_ 1102 SelDrvMdePos02_D_Stat 31 "Faulty" 30 "SelDrvMde31" 29 "SelDrvMde30" 28 "SelDrvMde29" 27 "SelDrvMde28" 26 "SelDrvMde27" 25 "SelDrvMde26" 24 "SelDrvMde25" 23 "SelDrvMde24" 22 "SelDrvMde23" 21 "SelDrvMde22" 20 "SelDrvMde21" 19 "SelDrvMde20" 18 "SelDrvMde19" 17 "SelDrvMde18" 16 "SelDrvMde17" 15 "SelDrvMde16" 14 "SelDrvMde15" 13 "SelDrvMde14" 12 "SelDrvMde13" 11 "SelDrvMde12" 10 "SelDrvMde11" 9 "SelDrvMde10" 8 "SelDrvMde09" 7 "SelDrvMde08" 6 "SelDrvMde07" 5 "SelDrvMde06" 4 "SelDrvMde05" 3 "SelDrvMde04" 2 "SelDrvMde03" 1 "SelDrvMde02" 0 "SelDrvMde01";
VAL_ 1102 SelDrvMdePos01_D_Stat 31 "Faulty" 30 "SelDrvMde31" 29 "SelDrvMde30" 28 "SelDrvMde29" 27 "SelDrvMde28" 26 "SelDrvMde27" 25 "SelDrvMde26" 24 "SelDrvMde25" 23 "SelDrvMde24" 22 "SelDrvMde23" 21 "SelDrvMde22" 20 "SelDrvMde21" 19 "SelDrvMde20" 18 "SelDrvMde19" 17 "SelDrvMde18" 16 "SelDrvMde17" 15 "SelDrvMde16" 14 "SelDrvMde15" 13 "SelDrvMde14" 12 "SelDrvMde13" 11 "SelDrvMde12" 10 "SelDrvMde11" 9 "SelDrvMde10" 8 "SelDrvMde09" 7 "SelDrvMde08" 6 "SelDrvMde07" 5 "SelDrvMde06" 4 "SelDrvMde05" 3 "SelDrvMde04" 2 "SelDrvMde03" 1 "SelDrvMde02" 0 "SelDrvMde01";
VAL_ 1056 AutoEpbMsgTxt_D_Rq 7 "Message7" 6 "Message6" 5 "Message5" 4 "Message4" 3 "Message3" 2 "Message2" 1 "Message1" 0 "NoMessage";
VAL_ 1056 AutoEpbDsply_D_Stat 1 "Available" 0 "NotAvailable";
VAL_ 1056 AutoEpbButtnOn_B_Stat 1 "On" 0 "Off";
VAL_ 1056 SelDrvMdePos12_B_Avail 1 "Available" 0 "NotAvailable";
VAL_ 1056 SelDrvMdePos11_B_Avail 1 "Available" 0 "NotAvailable";
VAL_ 1056 SelDrvMdePos10_B_Avail 1 "Available" 0 "NotAvailable";
VAL_ 1056 SelDrvMdePos09_B_Avail 1 "Available" 0 "NotAvailable";
VAL_ 1056 SelDrvMdePos08_B_Avail 1 "Available" 0 "NotAvailable";
VAL_ 1056 SelDrvMdePos07_B_Avail 1 "Available" 0 "NotAvailable";
VAL_ 1056 SelDrvMdePos06_B_Avail 1 "Available" 0 "NotAvailable";
VAL_ 1056 SelDrvMdePos05_B_Avail 1 "Available" 0 "NotAvailable";
VAL_ 1056 SelDrvMdePos04_B_Avail 1 "Available" 0 "NotAvailable";
VAL_ 1056 SelDrvMdePos03_B_Avail 1 "Available" 0 "NotAvailable";
VAL_ 1056 SelDrvMdePos02_B_Avail 1 "Available" 0 "NotAvailable";
VAL_ 1056 SelDrvMdePos01_B_Avail 1 "Available" 0 "NotAvailable";
VAL_ 1056 ActvDrvMde_D2_Stat 31 "Faulty" 30 "SelDrvMde31" 29 "SelDrvMde30" 28 "SelDrvMde29" 27 "SelDrvMde28" 26 "SelDrvMde27" 25 "SelDrvMde26" 24 "SelDrvMde25" 23 "SelDrvMde24" 22 "SelDrvMde23" 21 "SelDrvMde22" 20 "SelDrvMde21" 19 "SelDrvMde20" 18 "SelDrvMde19" 17 "SelDrvMde18" 16 "SelDrvMde17" 15 "SelDrvMde16" 14 "SelDrvMde15" 13 "SelDrvMde14" 12 "SelDrvMde13" 11 "SelDrvMde12" 10 "SelDrvMde11" 9 "SelDrvMde10" 8 "SelDrvMde09" 7 "SelDrvMde08" 6 "SelDrvMde07" 5 "SelDrvMde06" 4 "SelDrvMde05" 3 "SelDrvMde04" 2 "SelDrvMde03" 1 "SelDrvMde02" 0 "SelDrvMde01";
VAL_ 1056 SelDrvMde_D2_Rq 31 "Faulty" 30 "SelDrvMde31" 29 "SelDrvMde30" 28 "SelDrvMde29" 27 "SelDrvMde28" 26 "SelDrvMde27" 25 "SelDrvMde26" 24 "SelDrvMde25" 23 "SelDrvMde24" 22 "SelDrvMde23" 21 "SelDrvMde22" 20 "SelDrvMde21" 19 "SelDrvMde20" 18 "SelDrvMde19" 17 "SelDrvMde18" 16 "SelDrvMde17" 15 "SelDrvMde16" 14 "SelDrvMde15" 13 "SelDrvMde14" 12 "SelDrvMde13" 11 "SelDrvMde12" 10 "SelDrvMde11" 9 "SelDrvMde10" 8 "SelDrvMde09" 7 "SelDrvMde08" 6 "SelDrvMde07" 5 "SelDrvMde06" 4 "SelDrvMde05" 3 "SelDrvMde04" 2 "SelDrvMde03" 1 "SelDrvMde02" 0 "SelDrvMde01";
VAL_ 1056 SelDrvMdePt_D_Rq 31 "Faulty" 30 "NotUsed15" 29 "NotUsed14" 28 "NotUsed13" 27 "NotUsed12" 26 "NotUsed11" 25 "NotUsed10" 24 "NotUsed9" 23 "NotUsed8" 22 "NotUsed7" 21 "NotUsed6" 20 "NotUsed5" 19 "NotUsed4" 18 "EvLaterChargerMode" 17 "EvNowMode" 16 "DragMode" 15 "HighSpeedDesertMode_Baja" 14 "SportAdaptiveMode" 13 "NotAvailable_13" 12 "NotAvailable_12" 11 "NotAvailable_11" 10 "NotAvailable_10" 9 "RockCrawlMode" 8 "MudRutsMode" 7 "SandMode" 6 "EconomyMode" 5 "GrassGravelSnow" 4 "NotAvailable_04" 3 "TowHaulMode" 2 "NotAvailable_02" 1 "SportMode" 0 "NormalMode";
VAL_ 1056 SelDrvMdeMsgTxt_D_Rq 15 "Message15" 14 "Message14" 13 "Message13" 12 "Message12" 11 "Message11" 10 "Message10" 9 "Message9" 8 "Message8" 7 "Message7" 6 "Message6" 5 "Message5" 4 "Message4" 3 "Message3" 2 "Message2" 1 "Message1" 0 "NoMessage";
VAL_ 1056 SelDrvMde_D_Stat 3 "NotUsed" 2 "DriveModeChangeRequest" 1 "DriveModeChangeSelection" 0 "NoDriveModeChangeRequest";
VAL_ 1056 AwdMde_D_RqBrk 7 "Faulty" 6 "NotUsed2" 5 "NoRequest" 4 "Neutral" 3 "FourByFourLow" 2 "FourByFourHigh" 1 "FourByFourAuto" 0 "FourByTwo";
VAL_ 1054 AirDamUp_B_RqBrk 1 "Up" 0 "NoRequest";
VAL_ 1054 RbaBrk_D_Stat 3 "Denied" 2 "Active" 1 "Open" 0 "Closed";
VAL_ 1054 SelDrvMdeChassis2_D_Rq 31 "Faulty" 30 "NotUsed17" 29 "NotUsed16" 28 "NotUsed15" 27 "NotUsed14" 26 "NotUsed13" 25 "NotUsed12" 24 "NotUsed11" 23 "NotUsed10" 22 "NotUsed9" 21 "NotUsed8" 20 "NotUsed7" 19 "NotUsed6" 18 "NotUsed5" 17 "NotUsed4" 16 "NotUsed3" 15 "NotUsed2" 14 "RoughRoadMode" 13 "TrackMode" 12 "HighSpeedDesertMode" 11 "TowHaulMode" 10 "RockCrawlMode" 9 "SandMode" 8 "MudAndRutsMode" 7 "LowMuMode" 6 "ComfortAdaptiveMode" 5 "ComfortMode" 4 "SportAdaptiveMode" 3 "SportMode" 2 "EconomyMode" 1 "NormalAdaptiveMode" 0 "NormalMode";
VAL_ 1054 TrailCtl_D_Stat 7 "Faulty" 6 "DescentOnly" 5 "EnabledDeny" 4 "StandbyOverThreshold" 3 "StandbyOverride" 2 "Active" 1 "EnabledDescent" 0 "Off";
VAL_ 1054 TrailCtlMsgTxt_D_Rq 15 "Message15" 14 "Message14" 13 "Message13" 12 "Message12" 11 "Message11" 10 "Message10" 9 "Message9" 8 "Message8" 7 "Message7" 6 "Message6" 5 "Message5" 4 "Message4" 3 "Message3" 2 "Message2" 1 "Message1" 0 "NoMessage";
VAL_ 1054 BrkBstrVac_D_Stat 3 "NotUsed" 2 "BoosterVacEstimator" 1 "BoosterVacSensor" 0 "NoBoosterVacuumMonitor";
VAL_ 1054 DrvSlipCtlOffLamp_D_Rq 3 "Fast_Flash" 2 "Slow_Flash" 1 "On" 0 "Off";
VAL_ 1054 DrvSlipCtlMdeMsg_D_Rq 31 "Message31" 30 "Message30" 29 "Message29" 28 "Message28" 27 "Message27" 26 "Message26" 25 "Message25" 24 "Message24" 23 "Message23" 22 "Message22" 21 "Message21" 20 "Message20" 19 "Message19" 18 "Message18" 17 "Message17" 16 "Message16" 15 "Message15" 14 "Message14" 13 "Message13" 12 "Message12" 11 "Message11" 10 "Message10" 9 "Message9" 8 "Message8" 7 "Message7" 6 "Message6" 5 "Message5" 4 "Message4" 3 "Message3" 2 "Message2" 1 "Message1" 0 "NoMessage";
VAL_ 1054 AutoHoldMsgTxt_D_Rq 15 "Message15" 14 "Message14" 13 "Message13" 12 "Message12" 11 "Message11" 10 "Message10" 9 "Message9" 8 "Message8" 7 "Message7" 6 "Message6" 5 "Message5" 4 "Message4" 3 "Message3" 2 "Message2" 1 "Message1" 0 "NoMessage";
VAL_ 1054 CtaBrk_D_Stat 3 "Denied" 2 "Active" 1 "Open" 0 "Closed";
VAL_ 1054 SelDrvMdeAwd_D_Rq 31 "Faulty" 30 "NotUsed_17" 29 "NotUsed_16" 28 "NotUsed_15" 27 "NotUsed_14" 26 "NotUsed_13" 25 "NotUsed_12" 24 "NotUsed_11" 23 "NotUsed_10" 22 "NotUsed_9" 21 "NotUsed_8" 20 "NotUsed_7" 19 "NotUsed_6" 18 "NotUsed_5" 17 "EvLaterChargeMode" 16 "EvNowMode" 15 "TrackMode" 14 "RoughRoadMode" 13 "NotAvailable" 12 "HighSpeedDesertMode_Baja" 11 "SportAdaptiveMode" 10 "RockCrawlMode" 9 "MudRutsMode" 8 "SandMode" 7 "EconomyMode" 6 "GrassGravelSnow" 5 "TowHaulMode" 4 "SportMode" 3 "Normal_4L" 2 "Normal_4A" 1 "Normal_2H" 0 "NormalMode";
VAL_ 1054 AutoHoldSwMde_B_Ind 1 "On" 0 "Off";
VAL_ 1054 AutoHoldMde_D_Ind 3 "Indication_3" 2 "Indication_2" 1 "Indication_1" 0 "Off";
VAL_ 1054 SelDrvMdeChassis_D_Rq 31 "Faulty" 30 "NotUsed17" 29 "NotUsed16" 28 "NotUsed15" 27 "NotUsed14" 26 "NotUsed13" 25 "NotUsed12" 24 "NotUsed11" 23 "NotUsed10" 22 "NotUsed9" 21 "NotUsed8" 20 "NotUsed7" 19 "NotUsed6" 18 "NotUsed5" 17 "NotUsed4" 16 "NotUsed3" 15 "NotUsed2" 14 "NotUsed1" 13 "TrackMode" 12 "HighSpeedDesertMode" 11 "TowHaulMode" 10 "RockCrawlMode" 9 "SandMode" 8 "MudAndRutsMode" 7 "LowMuMode" 6 "ComfortAdaptiveMode" 5 "ComfortMode" 4 "SportAdaptiveMode" 3 "SportMode" 2 "EconomyMode" 1 "NormalAdaptiveMode" 0 "NormalMode";
VAL_ 1054 ApaBrk_D_Stat 3 "Denied" 2 "Active" 1 "Open" 0 "Closed";
VAL_ 1046 HsaMde_D_Mem 3 "Undefined" 2 "Manual" 1 "Automatic" 0 "Off";
VAL_ 1046 BrkBstrVac_B_Rq 1 "Yes" 0 "No";
VAL_ 1046 HdcMde_D_Actl 7 "Fault" 6 "Temporarily_Unavailable" 5 "NotEnabled_WrongGearSel" 4 "NotEnabled_SpdLimitExceed" 3 "Active_Braking" 2 "Not_Active_Braking" 1 "Off" 0 "Undefined";
VAL_ 1046 RearDiffLck_Tq2_RqMx 4095 "Faulty";
VAL_ 1046 TRLR_SWAY_EVNT_IN_PROG 1 "Yes" 0 "No";
VAL_ 1046 TRLR_SWAY_CONFIG_STAT 1 "On" 0 "Off";
VAL_ 1046 TCMode 1 "Active" 0 "Inactive";
VAL_ 1046 DrvSlipCtlLamp_D_Rq 3 "Fast_Flash" 2 "Slow_Flash" 1 "On" 0 "Off";
VAL_ 1046 Abs_B_Falt 1 "Yes" 0 "No";
VAL_ 1046 DrvSlipCtlMde_D_Ind 3 "App_Specific_Off_Mode_3" 2 "App_Specific_Off_Mode_2" 1 "App_Specific_Off_Mode_1" 0 "Default_Mode";
VAL_ 1046 DrvAntiLckLamp_D_Rq 3 "Fast_Flash" 2 "Slow_Flash" 1 "On" 0 "Off";
VAL_ 1046 StabCtlBrk_B_Avail 1 "Yes" 0 "No";
VAL_ 1046 DrvHdcWarnInfo_D_Rq 3 "Undefined" 2 "Lamp_On_Continuously" 1 "Lamp_Flashing" 0 "Lamp_Off_Continuously";
VAL_ 1046 DrvHdcMsg_D_Rq 7 "Undefined" 6 "Speed_too_High" 5 "Temporarily_Unavailable" 4 "System_Fault" 3 "Select_Gear" 2 "Off" 1 "On" 0 "No_Message";
VAL_ 1046 DrvHdcLampInfo_D_Rq 3 "Fast_Flash" 2 "Slow_Flash" 1 "On" 0 "Off";
VAL_ 1046 BpedMove_D_Actl 3 "Unknown" 2 "DriverApplyingBrakePedal" 1 "NoAutonomousBrkPdlMovement" 0 "AutonomousBrkPedalMove";
VAL_ 1046 ChimeBrk_B_Rq 1 "Yes" 0 "No";
VAL_ 1046 BrkLamp_B_Rq 1 "Yes" 0 "No";
VAL_ 1046 HILL_DESC_MC 7 "Fault_Detected" 6 "Cooling_Down" 5 "Abort_Apply_Brakes" 4 "Active" 3 "Disabled" 2 "Enabled" 1 "Off_Road" 0 "Normal";
VAL_ 1046 RearDiffElckrOpen_B_Rq 1 "Yes" 0 "No";
VAL_ 1045 VehStab_D_Stat 15 "Faulty" 14 "No_Data_Exists" 13 "NotUsed6" 12 "NotUsed5" 11 "NotUsed4" 10 "NotUsed3" 9 "NotUsed2" 8 "NotUsed1" 7 "High_SSRA_no_OS" 6 "Straight" 5 "Post_Oversteer" 4 "Post_Transition" 3 "Countersteer" 2 "Understeer" 1 "Oversteer" 0 "Linear";
VAL_ 1045 BrkFluidLvl_D_Stat 3 "Invalid" 2 "Unknown" 1 "Low" 0 "OK";
VAL_ 1045 LsmcBrkDecel_D_Stat 7 "NotUsed_3" 6 "NotUsed_2" 5 "NotUsed_1" 4 "Denied" 3 "FaultDegraded" 2 "FaultExt" 1 "On" 0 "Off";
VAL_ 1045 VehYawNonLin_W_Rq 4095 "Fault" 4094 "Unknown";
VAL_ 1045 VehYawLin_W_Rq 4095 "Fault" 4094 "Unknown";
VAL_ 1045 VehVActlBrk_D_Qf 3 "OK" 2 "Not_Within_Specifications" 1 "No_Data_Exists" 0 "Faulty";
VAL_ 1044 StePinOffst_An_Est 65535 "Faulty" 65534 "NoDataExists";
VAL_ 1044 StePinOffst_D_Stat 3 "FineOffset" 2 "CoarseOffset" 1 "StoredOffset" 0 "OffsetNotCalculated";
VAL_ 1042 VehRol_An_Dsply 127 "Faulty" 126 "NoDataExists";
VAL_ 1042 VehPtch_An_Dsply 127 "Faulty" 126 "NoDataExists";
VAL_ 535 WhlRr_W_Meas 32767 "Fault" 32766 "Unknown";
VAL_ 535 WhlRl_W_Meas 32767 "Fault" 32766 "Unknown";
VAL_ 535 WhlFr_W_Meas 32767 "Fault" 32766 "Unknown";
VAL_ 535 WhlFl_W_Meas 32767 "Fault" 32766 "Unknown";
VAL_ 534 WhlDirRr_D_Actl 3 "Faulty" 2 "NoDataExists" 1 "Backward" 0 "Forward";
VAL_ 534 WhlDirRl_D_Actl 3 "Faulty" 2 "NoDataExists" 1 "Backward" 0 "Forward";
VAL_ 534 WhlDirFr_D_Actl 3 "Faulty" 2 "NoDataExists" 1 "Backward" 0 "Forward";
VAL_ 534 WhlDirFl_D_Actl 3 "Faulty" 2 "NoDataExists" 1 "Backward" 0 "Forward";
VAL_ 532 RgenTqFalt_B_Actl 1 "Fault" 0 "No_Fault";
VAL_ 532 RgenBrkDynoMde_B_Actl 1 "TwoWheelDyno" 0 "NormalOperation";
VAL_ 531 VehStop_D_Stat 3 "Faulty" 2 "NoDataExists" 1 "Yes" 0 "No";
VAL_ 531 TracCtlPtActv_B_Actl 1 "Active" 0 "Inactive";
VAL_ 531 LscmbbMntr_B_Err 1 "DisplayMessage" 0 "NoMessage";
VAL_ 531 LscmbbBrkDis_B_Actl 1 "Yes" 0 "No";
VAL_ 531 LscmbbDeny_B_ActlBrk 1 "Yes" 0 "No";
VAL_ 531 PrkBrkYwLamp_D_Rq 3 "Fast_Flash" 2 "Slow_Flash" 1 "On" 0 "Off";
VAL_ 531 PrkBrkRedLamp_D_Rq 3 "Fast_Flash" 2 "Slow_Flash" 1 "On" 0 "Off";
VAL_ 531 LscmbbBrkDecel_B_Actl 1 "Yes" 0 "No";
VAL_ 531 AbsActv_B_Actl 1 "Yes" 0 "No";
VAL_ 531 StabCtlBrkActv_B_Actl 1 "Yes" 0 "No";
VAL_ 531 CmbbBrkPrchg_B_Actl 1 "Yes" 0 "No";
VAL_ 531 CmbbBrkDecel_B_Actl 1 "Yes" 0 "No";
VAL_ 531 CmbbBaSensInc_B_Actl 1 "Yes" 0 "No";
VAL_ 531 AccBrkWarm_B_Actl 1 "Yes" 0 "No";
VAL_ 531 AccBrkTotTqMn_B_Actl 1 "Yes" 0 "No";
VAL_ 531 AccBrkPrchgActv_B_Actl 1 "Yes" 0 "No";
VAL_ 531 AccBrkDis_B_Actl 1 "Yes" 0 "No";
VAL_ 531 AccBrkDeny_B_Actl 1 "Yes" 0 "No";
VAL_ 531 AccBrkActv_B_Actl 1 "Yes" 0 "No";
VAL_ 531 PrplDrgCtlActv_B_Actl 1 "Active" 0 "Inactive";
VAL_ 531 LscmbbBaSensInc_B_Actl 1 "Yes" 0 "No";
VAL_ 531 CmbbBrkDis_B_Actl 1 "Yes" 0 "No";
VAL_ 531 CmbbDeny_B_ActlBrk 1 "Yes" 0 "No";
VAL_ 531 CcDis_B_Cmd 1 "Yes" 0 "No";
VAL_ 531 VehLongOvrGnd_A_Est 1023 "Fault" 1022 "Unknown";
VAL_ 531 LscmbBrkPrchg_B_Actl 1 "Active" 0 "Inactive";
VAL_ 531 AccStopActv_B_ActlBrk 1 "Yes" 0 "No";
VAL_ 531 AccDis_B_ActlEpb 1 "Yes" 0 "No";
VAL_ 531 PrkBrkMsgTxt_D_Rq 15 "Message15" 14 "Message14" 13 "Message13" 12 "Message12" 11 "Message11" 10 "Message10" 9 "Message9" 8 "Message8" 7 "Message7" 6 "Message6" 5 "Message5" 4 "Message4" 3 "Message3" 2 "Message2" 1 "Message1" 0 "No_Message";
VAL_ 531 PrkBrkStatus 7 "GeneralFault_MaintenceMode" 6 "ECD_by_Brake_ECU_Active" 5 "EPB_Limphome_Active" 4 "Rear_Caliper_Open" 3 "RWU_By_EPB_Active" 2 "Rear_Caliper_Transition" 1 "Rear_Caliper_Closed" 0 "Not_Supported";
VAL_ 136 SteWhlBrkOffst_An_Rq 32767 "Faulty" 32766 "NoDataExists";
VAL_ 125 VehRolComp_W_Actl 4094 "NoDataExists" 4095 "Fault";
VAL_ 125 VehVertComp_A_Actl 1022 "NoDataExists" 1023 "Fault";
VAL_ 125 BrkTot_Tq_RqArb 8191 "Fault" 8190 "Unknown";
VAL_ 125 BrkTot_Tq_Actl 8191 "Fault" 8190 "Unknown";
VAL_ 125 HsaStat_D_Actl 7 "Faulty" 6 "FaultyWithDriverIndication" 5 "SlowRelease" 4 "FastRelease" 3 "ActiveBrakePedalReleased" 2 "ActiveBrakePedalPressed" 1 "FindingGradient" 0 "Inactive";
VAL_ 119 VehTrvlDir_D_Stat 7 "Faulty" 6 "NoDataExists" 5 "NotUsed2" 4 "NotUsed1" 3 "Reverse" 2 "LikelyReverse" 1 "Forward" 0 "LikelyForward";
VAL_ 119 VehOverGnd_V_Est 65535 "Invalid" 65534 "Unknown";
VAL_ 119 VehLongComp_A_Actl 1023 "Fault" 1022 "NoDataExists";
VAL_ 119 VehLatComp_A_Actl 1023 "Fault" 1022 "NoDataExists";
VAL_ 119 VehYawComp_W_Actl 4095 "Fault" 4094 "NoDataExists";
VAL_ 118 BrkCtrFnd_B_Stat 1 "Yes" 0 "No";
VAL_ 118 DrvSte_D_Stat 15 "NotUsed10" 14 "NotUsed9" 13 "NotUsed8" 12 "NotUsed7" 11 "NotUsed6" 10 "NotUsed5" 9 "NotUsed4" 8 "NotUsed3" 7 "NotUsed2" 6 "NotUsed1" 5 "Request_Active" 4 "Ignition_Off" 3 "DSR_in_Normal_Idle_Mode" 2 "EPAS_Comm_Disturbed" 1 "DSR_Request_Not_Applicable" 0 "DSR_Deactivated";
VAL_ 118 DrvSte_Tq_Rq 255 "Invalid" 254 "Unknown";
VAL_ 118 EmgcyBrkLamp_D_Rq 3 "NotUsed" 2 "Active_at_standstill" 1 "Active_at_speed" 0 "Inactive";
VAL_ 118 StopLamp_B_RqBrk 1 "Active" 0 "Inactive";
VAL_ 73 immoSubTarget1Cmd_T1 7 "Unused3" 6 "Unused2" 5 "ECHO_TARGET1_IDBLOCK2" 4 "Unused1" 3 "RQST_TARGET1_IDBLOCK2" 2 "RQST_TARGET1_IDBLOCK1" 1 "RESPONSE" 0 "IDLE";
VAL_ 561 TrnMsgTxt2_D_Rq 7 "NotUsed3" 6 "NotUsed2" 5 "NotUsed1" 4 "TransTooHot_LoudChime" 3 "PressBrake_LoudChime" 2 "PressBrake_SoftChime" 1 "PressBrake_NoChime" 0 "NoText_NoChime";
VAL_ 561 TrnMsgTxt_D_Rq 15 "Message_15" 14 "Message_14" 13 "Message_13" 12 "Message_12" 11 "Message_11" 10 "Message_10" 9 "Message_9" 8 "Message_8" 7 "Message_7" 6 "Message_6" 5 "Message_5" 4 "Message_4" 3 "Message_3" 2 "Message_2" 1 "Message_1" 0 "NoMessage";
VAL_ 330 TrnAout_W_ActlUnfilt 32767 "Fault" 32766 "Unknown";
VAL_ 1090 Mtr2State_D_ActlMntr 7 "Faulty" 6 "NoDataExists" 5 "NotUsed_1" 4 "ReadinessState" 3 "DeactivationState" 2 "PowerGeneration" 1 "PowerConsumption" 0 "Null";
VAL_ 1090 Inv1Ain_I_ActlMntr 32767 "Faulty" 32766 "NoDataExists";
VAL_ 1090 HybVehMde_D_ActlMntr 7 "Faulty" 6 "NoDataExists" 5 "NotUsed_2" 4 "NotUsed_1" 3 "Fuel" 2 "HybridElectric" 1 "AllElectric" 0 "Null";
VAL_ 1090 ChrgStat_D_ActlMntr 7 "Faulty" 6 "NoDataExists" 5 "NotUsed" 4 "ChargingCompleted" 3 "NotCharging" 2 "ChargingInDrivingState" 1 "ChargingInParkingState" 0 "Null";
VAL_ 1090 VehElRnge_L_Dsply 4094 "NoDataExists" 4095 "Fault";
VAL_ 870 EngMdeMsgTxt_D_Rq 7 "NotUsed_3" 6 "NotUsed_2" 5 "NotUsed_1" 4 "Charge" 3 "GlowingCharge" 2 "Hybrid" 1 "Ev" 0 "NoMessage";
VAL_ 870 RngPerChrgInst_L_Dsply 4095 "Faulty" 4094 "NoDataExists";
VAL_ 869 PwrFlowTxt_D_Dsply 15 "NotUsed7" 14 "NotUsed6" 13 "NotUsed5" 12 "NotUsed4" 11 "Disply_Rgen_Chrg_Txt" 10 "Disp_Fast_Charge_Txt" 9 "Disp_Fast_Charge_Cmplt_Txt" 8 "Disp_Charge_Cmplt_Txt" 7 "Disp_Remote_Start_Txt" 6 "Disp_Eng_Drv_Txt" 5 "Disp_Elec_Drv_Txt" 4 "Disp_Idle_with_Chrg_Txt" 3 "Disp_Idle_Txt" 2 "Disp_Charg_HV_Batt_Txt" 1 "Disp_Hyb_Drive_Txt" 0 "No_Text";
VAL_ 869 EngOnMsg2_D_Dsply 14 "_0xE_to_1F_NotUsed" 12 "Battery_Temperature" 11 "Hill_Decent_Control" 10 "Fuel_Maintenance" 9 "Oil_Maintenance" 8 "Normal_Operation" 7 "Low_Gear" 6 "Batt_Charging" 5 "Engine_Cold" 4 "Neutral_Gear" 3 "Heater_Setting" 2 "High_Speed" 1 "Acceleration" 0 "No_Display" 13 "Drive_Mode_Selection";
VAL_ 869 EngOnMsg1_D_Dsply 14 "_0xE_to_1F_NotUsed" 12 "Battery_Temperature" 11 "Hill_Decent_Control" 10 "Fuel_Maintenance" 9 "Oil_Maintenance" 8 "Normal_Operation" 7 "Low_Gear" 6 "Batt_Charging" 5 "Engine_Cold" 4 "Neutral_Gear" 3 "Heater_Setting" 2 "High_Speed" 1 "Acceleration" 0 "No_Display" 13 "Drive_Mode_Selection";
VAL_ 869 FuelMaintMde_D_Dsply 3 "Feature_Not_Present" 2 "In_Fuel_Maint_Mode" 1 "Close_to_Fuel_Maint" 0 "OK";
VAL_ 869 EngActv_B_Dsply 1 "On" 0 "Off";
VAL_ 869 EffWhlThresOn_B_Dsply 1 "On" 0 "Off";
VAL_ 606 ElVehLaterMde_D_Stat 3 "NotUsed" 2 "Available" 1 "NotAvailable" 0 "Null";
VAL_ 606 ElVehNowMde_D_Stat 3 "NotUsed" 2 "Available" 1 "NotAvailable" 0 "Null";
VAL_ 374 GearEngag_D_Actl 7 "Undefined" 6 "Fwd_Clutch_Fully_Engaged" 5 "Neutral_Idle" 4 "Disengaged_to_Neutral_Idle" 3 "Disengaged_to_Neutral_Park" 2 "Engagement_in_Progress" 1 "InitializeFwdClutchEngagmt" 0 "Park_Neutral";
VAL_ 374 TrnRng_D_Rq 15 "Fault" 14 "Unknown_Position" 13 "NotUsed_2" 12 "NotUsed_1" 11 "Range6" 10 "Range5" 9 "Range4" 8 "Range3_M3_L3" 7 "Range2_M2_L2" 6 "Range1_M1_L1" 5 "Low" 4 "Sport_DriveSport_Mposition" 3 "Drive" 2 "Neutral" 1 "Reverse" 0 "Park";
VAL_ 374 TrnPrkSys_D_Actl 15 "Faulty" 14 "NotUsed_5" 13 "NotUsed_4" 12 "NotUsed_3" 11 "NotUsed_2" 10 "NotUsed_1" 9 "FrequencyError" 8 "OutOfRangeHigh" 7 "OutOfRangeLow" 6 "Override" 5 "OutOfPark" 4 "TransitionCloseToOutOfPark" 3 "AtNoSpring" 2 "TransitionCloseToPark" 1 "Park" 0 "NotKnown";
VAL_ 374 GearLvr_D_ActlDrv 15 "Fault" 14 "Unknown_Position" 13 "NotUsed_2" 12 "NotUsed_1" 11 "Range6" 10 "Range5" 9 "Range4" 8 "Range3_M3_L3" 7 "Range2_M2_L2" 6 "Range1_M1_L1" 5 "Low" 4 "Sport_DriveSport_Mposition" 3 "Drive" 2 "Neutral" 1 "Reverse" 0 "Park";
VAL_ 374 GearPos_D_Trg 15 "Unknown" 14 "Reverse" 13 "Undefined_5" 12 "Undefined_4" 11 "Undefined_3" 10 "Tenth" 9 "Ninth" 8 "Eighth" 7 "Seventh" 6 "Sixth" 5 "Fifth" 4 "Fourth" 3 "Third" 2 "Second" 1 "First" 0 "Neutral";
VAL_ 374 GearPos_D_Actl 15 "Unknown" 14 "Reverse" 13 "Undefined_5" 12 "Undefined_4" 11 "Undefined_3" 10 "Tenth" 9 "Ninth" 8 "Eighth" 7 "Seventh" 6 "Sixth" 5 "Fifth" 4 "Fourth" 3 "Third" 2 "Second" 1 "First" 0 "Neutral";
VAL_ 603 WhlDirAvgDrv_D_Actl 3 "Failed" 2 "Unknown" 1 "Backward" 0 "Forward";
VAL_ 603 PrplTqMnRgen_B_Actl 1 "Yes" 0 "No";
VAL_ 603 BattTracCnnct_D_Rq 3 "Undefined" 2 "Retain" 1 "Close" 0 "Open";
VAL_ 602 HtrnWarnLamp_B_Dsply 1 "On" 0 "Off";
VAL_ 602 HybPwLimOn_B_Stat 1 "Yes" 0 "No";
VAL_ 602 PwPckTqRdy_B_Dsply 1 "On" 0 "Off";
VAL_ 1152 BattTracDiagClr_B_Stat 1 "On" 0 "Off";
VAL_ 1152 EngTeHi_B_Actl 1 "EngineTempHigh" 0 "Normal";
VAL_ 1152 DcdcOn_B_Rq 1 "On" 0 "Off";
VAL_ 1152 ULoBattSpprtSustn_B_Rq 1 "Active" 0 "Inactive";
VAL_ 1152 VehElEff_No_Avg 127 "Faulty" 126 "NoDataExists";
VAL_ 872 PlgActvArb_B_Dsply 1 "On" 0 "Off";
VAL_ 872 HybMdeStat_D_Dsply 7 "NotUsed2" 6 "EV_Charge" 5 "EV_Override" 4 "Forced_EV_Mode" 3 "Forced_Charge_Sustain_Mode" 2 "Auto_Charge_Sustain_Mode" 1 "Auto_Charge_Deplete_Mode" 0 "Null_State";
VAL_ 560 SelDrvMdeSwtch_D_Stat3 3 "Faulty" 2 "SwitchState2" 1 "SwitchState1" 0 "NotPressed";
VAL_ 560 TrnSrvcRqd_B_Rq 1 "On" 0 "Off";
VAL_ 560 TrnShifActv_B_Actl 1 "Active" 0 "Inactive";
VAL_ 560 GearLvrPos_D_Actl 15 "Fault" 14 "Unknown_Position" 13 "Undefined_Treat_as__Fault" 12 "Undefined_Treat_as_Fault" 11 "sixth" 10 "fifth" 9 "fourth" 8 "third" 7 "second" 6 "first" 5 "Low" 4 "Sport_DriveSport" 3 "Drive" 2 "Neutral" 1 "Reverse" 0 "Park";
VAL_ 560 GboxOil_Te_Actl 255 "Faulty" 254 "NoDataExists";
VAL_ 369 SeatWorkSrfc_B_Falt 1 "Active" 0 "Inactive";
VAL_ 369 TrnIpcDsplyRng2_D_Actl 15 "No_Range_Selected" 14 "Range_14" 13 "Range_13" 12 "Range_12" 11 "Range_11" 10 "Range_10" 9 "Range_9" 8 "Range_8" 7 "Range_7" 6 "Range_6" 5 "Range_5" 4 "Range_4" 3 "Range_3" 2 "Range_2" 1 "Range_1" 0 "NotUsed";
VAL_ 369 TrnIpcDsplyRng_D_Stat 3 "NotUsed" 2 "Flash" 1 "On" 0 "Blank_No_Display";
VAL_ 369 TrnIpcDsplyGear_D_Actl 15 "No_Gear_Selected" 14 "_14th_Gear" 13 "_13th_Gear" 12 "_12th_Gear" 11 "_11th_Gear" 10 "_10th_Gear" 9 "_9th_Gear" 8 "_8th_Gear" 7 "_7th_Gear" 6 "_6th_Gear" 5 "_5th_Gear" 4 "_4th_Gear" 3 "_3rd_Gear" 2 "_2nd_Gear" 1 "_1st_Gear" 0 "Neutral";
VAL_ 369 TrnIpcDsplyMde_D_Stat 3 "Reserved_Blank_No_Display" 2 "Flash" 1 "On" 0 "Blank_No_Display";
VAL_ 369 TrnIpcDsplyMde_D_Actl 7 "Manual_3" 6 "Manual_2" 5 "Manual_1_Low" 4 "Sport" 3 "Drive" 2 "Neutral" 1 "Reverse" 0 "Park";
VAL_ 369 TrnIpcDsplyGear_D_Stat 3 "Reserved_Blank_No_Display" 2 "Flash" 1 "On" 0 "Blank_No_Display";
VAL_ 92 TrnLvrV_D_Rq 3 "Full_Speed" 2 "Aggressive" 1 "Normal" 0 "Quiet";
VAL_ 92 TrnSbwSysHlth_D_Actl 3 "OK" 2 "Degraded" 1 "No_Data_Exists" 0 "Faulty";
VAL_ 92 TrnGearNtmAllow_B_Stat 1 "Yes" 0 "No";
VAL_ 92 TrnDtpCmd_D_Actl 7 "NotUsed4" 6 "NotUsed3" 5 "NotUsed2" 4 "Relatch" 3 "Deploy" 2 "Self_Test" 1 "No_Command" 0 "NotUsed1";
VAL_ 92 GearSelLck_D_Rq 3 "PreventionBlocker" 2 "Unlock" 1 "Lock" 0 "Null";
VAL_ 92 TrnValidGear_D_Cnfm 3 "Accept" 2 "Reject" 1 "Internal_Request" 0 "No_Command";
VAL_ 92 TrnNtrlTowCmd_D_Actl 3 "NotUsed" 2 "Neutral_Tow_Entry" 1 "Car_Wash_Mode" 0 "Normal_Mode";
VAL_ 92 TrnGearCmd_Pc_ActlPt 1023 "Fault";
VAL_ 92 TrnGear_D_RqPt 7 "Fault" 6 "NotUsed" 5 "Manual" 4 "Drive" 3 "Neutral" 2 "Reverse" 1 "Park" 0 "No_Gear";
VAL_ 92 TrnCmdState_B_Actl 1 "Yes" 0 "No";
VAL_ 92 PrkBrkActv_D_RqTrnGear 3 "NotUsed2" 2 "RequestParkBrakeEngage" 1 "NoRequest" 0 "NotUsed1";
VAL_ 92 TrnGearMsgTxt_D_Rq 15 "Message_15" 14 "Message_14" 13 "Message_13" 12 "Message_12" 11 "Message_11" 10 "Message_10" 9 "Message_9" 8 "Message_8" 7 "Message_7" 6 "Message_6" 5 "Message_5" 4 "Message_4" 3 "Message_3" 2 "Message_2" 1 "Message_1" 0 "NoMessage";
VAL_ 1087 BattRgenLoChrg_D_RqEng 3 "Disable" 2 "Retain" 1 "Closed" 0 "Open";
VAL_ 1087 AdasLcObtclAbrt_B_Stat 1 "Yes" 0 "No";
VAL_ 1087 BattRgenLoDChrg_D_RqEng 3 "Disable" 2 "Retain" 1 "Closed" 0 "Open";
VAL_ 1087 AirDamPos_D_Stat 3 "Faulty" 2 "NotUsed" 1 "Down" 0 "Up";
VAL_ 1087 FapLcInhbt_B_Rq 1 "Yes" 0 "No";
VAL_ 1087 FapLcStopHold_B_Rq 1 "Yes" 0 "No";
VAL_ 1087 FapLcPrchgBrk_B_Rq 1 "Yes" 0 "No";
VAL_ 1087 FapLcObstcl_B_Stat 1 "Yes" 0 "No";
VAL_ 1087 FapLcMaxGrdInhbt_B_Stat 1 "Yes" 0 "No";
VAL_ 1087 FapLcMaxGrdAbrt_B_Stat 1 "Yes" 0 "No";
VAL_ 1087 FapLcActv_B_Stat 1 "Yes" 0 "No";
VAL_ 332 UreaLvlQlty_D_RqDsply 7 "NotUsed_5" 6 "NotUsed_4" 5 "NotUsed_3" 4 "NotUsed_2" 3 "NotUsed_1" 2 "FlashChime" 1 "On" 0 "Off";
VAL_ 332 UreaLvlTxtWarn_D_Rq 15 "NotUsed_4" 14 "NotUsed_3" 13 "NotUsed_2" 12 "NotUsed_1" 11 "System_Error" 10 "Engine_Idled_See_Manual" 9 "Engine_Idled_Upon_Refuel" 8 "Speed_Limited_To_XX_mph" 7 "XXmph_Max_Upon_Restart" 6 "Speed_Limited_To_YY_mph" 5 "YYmph_Max_Upon_Restart" 4 "SpdLimtd_YYmph_In_XXmiles" 3 "ExFlRange_XXMiles_ScndWarn" 2 "Exh_Fluid_Range_XX_Miles" 1 "Exh_Fluid_Under_Half_Full" 0 "Exh_Fluid_Over_Half_Full";
VAL_ 332 UreaQltySysWarn_D_Rq 7 "Undefined" 6 "ZZ_Overrides" 5 "EngineIdled" 4 "Engine_Idle_Upon_Refuel" 3 "SPEED_LIMITED_to_YY_mph" 2 "YY_MPH_MAX_UPON_Restart" 1 "CONTAMINATED_ExhFluid" 0 "NoQualityProblem";
VAL_ 332 DieslPrtcWarn_D_Rq 15 "NotUsed_4" 14 "NotUsed_3" 13 "NotUsed_2" 12 "NotUsed_1" 11 "OCR_ExhFilterClean_Stopped" 10 "OCR_ExhFilterCleaned" 9 "RgnOff_AtLimit" 8 "RgnOff_OverLoaded" 7 "RgnOff_Loaded" 6 "Exhaust_Filter_Full" 5 "DPF_OverLimit" 4 "DPF_AtLimit" 3 "ExhFilter_Drive_Completed" 2 "Cleaning_Exhaust_Filter" 1 "DPF_OverLoaded" 0 "DPF_Normal_Operation";
VAL_ 332 UreaQltyFlg_B_RqDsply 1 "True" 0 "False";
VAL_ 332 UreaQltySys_D_RqDsply 7 "Undefined" 6 "ZZ_Overrides" 5 "EngineIdled" 4 "Engine_Idle_Upon_Refuel" 3 "SPEED_LIMITED_to_YY_mph" 2 "YY_MPH_MAX_UPON_Restart" 1 "CONTAMINATED_ExhFluid" 0 "NoQualityProblem";
VAL_ 332 UreaLvlTxt_D_RqDsply 15 "NotUsed_4" 14 "NotUsed_3" 13 "NotUsed_2" 12 "NotUsed_1" 11 "System_Error" 10 "Engine_Idled_See_Manual" 9 "Engine_Idled_Upon_Refuel" 8 "Speed_Limited_To_XX_mph" 7 "XXmph_Max_Upon_Restart" 6 "Speed_Limited_To_YY_mph" 5 "YYmph_Max_Upon_Restart" 4 "SpdLimtd_YYmph_In_XXmiles" 3 "ExFlRange_XXMiles_ScndWarn" 2 "Exh_Fluid_Range_XX_Miles" 1 "Exh_Fluid_Under_Half_Full" 0 "Exh_Fluid_Over_Half_Full";
VAL_ 1100 EngExhMdeQuiet_D2_Stat 7 "Faulty" 6 "NotUsed_2" 5 "NotUsed_1" 4 "Track" 3 "Sport" 2 "Normal" 1 "Stealth" 0 "Null";
VAL_ 1100 HvacCmprLim_D_Stat 7 "NotUsed_2" 6 "NotUsed_1" 5 "CompressorHeadPressure" 4 "AvailableTorque" 3 "PedalPosition" 2 "RPM" 1 "ECT" 0 "NoLimit";
VAL_ 1100 WakeAlarm1_B_Typ 1 "CanAndEcuDriveCircuit" 0 "CanOnly";
VAL_ 1100 Veh_V_DsplyTrailCtlSet 63 "Faulty";
VAL_ 1100 TrailCtlPt_B_Falt 1 "Fault" 0 "No_Fault";
VAL_ 1100 AutoTowAllw_D_StatMnu 3 "TowHaulCommandedOn" 2 "AutoTowHaulEnabled" 1 "AutoTowHaulDisabled" 0 "NoSelection";
VAL_ 1100 AutoTowActv_B_Stat 1 "Yes" 0 "No";
VAL_ 1100 GrossTrainWeight_M_Est 255 "Faulty" 254 "NoDataExists";
VAL_ 1098 EdmSailMdeOn_B_Stat 1 "On" 0 "Off";
VAL_ 1098 EdmMsgTxt_D_Rq 15 "NotUsed_4" 14 "NotUsed_3" 13 "NotUsed_2" 12 "NotUsed_1" 11 "OverallGoodScore" 10 "WorkOnCompliance" 9 "GoodCompliance" 8 "WorkOnGearShifting" 7 "GoodGearShifting" 6 "WorkOnEfficientSpeed" 5 "GoodEfficientSpeed" 4 "WorkOnDeceleration" 3 "GoodDeceleration" 2 "WorkOnAcceleration" 1 "GoodAcceleration" 0 "NoMessage";
VAL_ 1098 EdmLamp_D_Dsply 15 "NotUsed_7" 14 "NotUsed_6" 13 "NotUsed_5" 12 "NotUsed_4" 11 "NotUsed_3" 10 "NotUsed_2" 9 "NotUsed_1" 8 "CoastingEngineBrake" 7 "CoastingShiftToNeutral" 6 "FreewayJunction" 5 "Curve2" 4 "Curve1" 3 "SpeedLimit" 2 "Crossing" 1 "FreewayExit" 0 "NoRecommendation";
VAL_ 1098 EdmCmplnc_B_Dsply 1 "Yes" 0 "No";
VAL_ 1086 FuelPumpPwr_B_Rq 1 "On" 0 "Off";
VAL_ 1086 ElLoadCtl_D_Rq 7 "Unused3" 6 "Unused2" 5 "Unused1" 4 "HoldAllDrvrInvisibleLoads" 3 "StdDriverInvisibleLoadsOn" 2 "AllDriverInvisibleLoadsOn" 1 "All_Possible_Loads_Off" 0 "No_Request";
VAL_ 1071 CluPdlPosPcMeas_D_Qf 3 "OK" 2 "Not_Within_Specifications" 1 "No_Data_Exists" 0 "Faulty";
VAL_ 1069 SlMde_D_Stat 3 "IsaNotConfigured" 2 "Manual_Mode" 1 "Auto_Mode" 0 "Null";
VAL_ 1069 SlMde_D_RqDsply 3 "NotUsed" 2 "ManualSpeed_LimiterSymbol" 1 "AutoSpeed_LimiterSymbol" 0 "NoSpeed_LimiterSymbol";
VAL_ 1069 IsaOffst_D_Stat 15 "Faulty" 14 "Null" 13 "Thirteen" 12 "Twelve" 11 "Eleven" 10 "Ten" 9 "Nine" 8 "Eight" 7 "Seven" 6 "Six" 5 "Five" 4 "Four" 3 "Three" 2 "Two" 1 "One" 0 "Zero";
VAL_ 1069 GrllShtrPos_D_Cmd 15 "Fully_Open" 14 "Position14" 13 "Position13" 12 "Position12" 11 "Position11" 10 "Position10" 9 "Position9" 8 "Position8" 7 "Position7" 6 "Position6" 5 "Position5" 4 "Position4" 3 "Position3" 2 "Position2" 1 "Position1" 0 "Fully_Closed";
VAL_ 1069 GrllShtrPos_B_Falt 1 "Fault" 0 "No_Fault";
VAL_ 1069 ObdWarmUp_B_Complt 1 "Yes" 0 "No";
VAL_ 1069 EngMsgTxt_D_Rq 3 "Undefined_2" 2 "Undefined_1" 1 "Power_Reduced_to_LowerTemp" 0 "No_Message";
VAL_ 1069 EngAirIn_Te_Actl 1023 "Fault" 1022 "Unknown";
VAL_ 1060 RearDiffOilTeWarn_B_Rq 1 "On" 0 "Off";
VAL_ 1060 RearDiffOil_Te_Actl 511 "Faulty";
VAL_ 1060 BpedDrvMsgTxt_B_Dsply 1 "On" 0 "Off";
VAL_ 1060 FuelLvlWarn_D_ActlEng 7 "DteLevel5Lowest" 6 "DteLevel4" 5 "DteLevel3" 4 "DteLevel2NonMyKey" 3 "DteLevel1MyKey" 2 "VeryLow" 1 "Low" 0 "OK";
VAL_ 1060 SelDrvMdePt_D_Stat 0 "NotAvailable" 1 "Available" 2 "TemporarilyNotAvailable" 3 "Faulty";
VAL_ 1057 FohEng_D_Rq 3 "AutoEnable_ParkEnable" 2 "AutoDisable_ParkEnable" 1 "AutoEnable_ParkDisable" 0 "Disable_Stop";
VAL_ 1057 EngIdlShutDwnTxt_D_Rq 3 "NotUsed" 2 "EngineShutdownOnPrevDrive" 1 "FeatureDisabledDueToFault" 0 "NoMessage";
VAL_ 1057 EngIdlShutDown_D_Stat 3 "Not_used" 2 "Engine_Shutdown" 1 "Initiated_Countdown" 0 "Normal_Operation";
VAL_ 1057 FUEL_ALCOHOL_PERCNT 255 "Invalid";
VAL_ 1057 TrnTotTq_Rt_Est 65535 "Fault" 65534 "Unknown";
VAL_ 1057 TrnTotLss_Tq_Est 255 "Fault" 254 "Unknown";
VAL_ 1057 ECMMILRequest 3 "Not_Used" 2 "Flash" 1 "On" 0 "Off";
VAL_ 1057 AirCondFluidHi_P_Actl 255 "Fault" 254 "Unknown";
VAL_ 1057 OilPressureWarning 1 "Low_Pressure_Lamp_On" 0 "Normal_Pressure_Lamp_Off";
VAL_ 1057 VehVLimStat_D_Actl 7 "Undefined_3" 6 "Undefined_2" 5 "Undefined_1" 4 "ASL_Fault_Condition" 3 "Active_and_Limiting" 2 "Active_but_Not_Limiting" 1 "Standby" 0 "Off";
VAL_ 1057 VehVLimActv_B_Actl 1 "Active" 0 "Inactive";
VAL_ 1057 CoolantFanStepAct 31 "Unused7" 30 "Unused6" 29 "Unused5" 28 "Unused4" 27 "Unused3" 26 "Unused2" 25 "Unused1" 23 "Step23" 22 "Step22" 21 "Step21" 20 "Step20" 19 "Step19" 18 "Step18" 17 "Step17" 16 "Step16" 15 "Step15" 14 "Step14" 13 "Step13" 12 "Step12" 11 "Step11" 10 "Step10" 9 "Step9" 8 "Step8" 7 "Step7" 6 "Step6" 5 "Step5" 4 "Step4" 3 "Step3" 2 "Step2" 1 "Step1" 24 "Max_Fan_Speed_Req" 0 "Fan_Cmd_Off";
VAL_ 1055 EcoCochInstNeg_B_Dsply 1 "True" 0 "False";
VAL_ 562 GearNtrl_D_Stat 3 "Faulty" 2 "NoDataExists" 1 "Yes" 0 "No";
VAL_ 523 EngAirFiltMsgTxt_D_Rq 7 "NotUsed_2" 6 "NotUsed_1" 5 "EngineAirFilterMonitorFalt" 4 "ResetComplete" 3 "Clogged" 2 "ReplaceNow" 1 "ReplaceSoon" 0 "NoMessage";
VAL_ 523 WaterInFuel_B_Falt 1 "Fault" 0 "No_Fault";
VAL_ 523 UreaMnAdd_L2_Actl 255 "Faulty";
VAL_ 523 UreaMxAdd_L2_Actl 511 "Faulty";
VAL_ 517 FapLc_B_Err 1 "Yes" 0 "No";
VAL_ 516 EngAoutNActl_D_QF 3 "OK" 2 "Not_Within_Specifications" 1 "No_Data_Exists" 0 "Faulty";
VAL_ 516 EngAout3_N_Actl 65535 "Invalid";
VAL_ 516 ApedPos_PcRate_ActlArb 255 "Fault" 254 "Unknown";
VAL_ 516 ApedPosPcActl_D_Qf 3 "OK" 2 "Not_Within_Specifications" 1 "No_Data_Exists" 0 "Faulty";
VAL_ 514 StrtrMtrDlyStrt_B_Stat 1 "Yes" 0 "No";
VAL_ 514 VehVTrlrAid_B_Avail 1 "Yes" 0 "No";
VAL_ 514 StrtrMtrCtlMsgTxt_D_Rq 7 "Start_In_Gear_Allowed" 6 "Pending_Start_Cancelled" 5 "Start_Pending_Please_Wait" 4 "Cranking_Limit_Exceeded" 3 "Press_Brk_and_Shift_to_P_N" 2 "Press_Clutch_and_Brake" 1 "Press_Clutch_To_Start" 0 "No_Display";
VAL_ 514 VehVActlEng_D_Qf 3 "OK" 2 "Not_Within_Specifications" 1 "No_Data_Exists" 0 "Faulty";
VAL_ 514 GearRvrse_D_Actl 7 "Fault" 6 "NotUsed_3" 5 "NotUsed_2" 4 "NotUsed_1" 3 "Active_confirmed" 2 "Active_not_confirmed" 1 "Inactive_confirmed" 0 "Inactive_not_confirmed";
VAL_ 514 StrtrMtrCtlMsgTxt_D2_Rq 3 "NoRequestPcmStartingMsgCtl" 2 "ShiftToNeutralToStart" 1 "ShiftToParkToStart" 0 "NoRequestBcmStartingMsgCtl";
VAL_ 512 PtDrvMde_D_Stat 15 "Faulty" 14 "NotUsed11" 13 "NotUsed10" 12 "NotUsed9" 11 "NotUsed8" 10 "NotUsed7" 9 "NotUsed6" 8 "NotUsed5" 7 "Drag" 6 "Rock" 5 "Baja" 4 "Sand" 3 "TowHaulGradeAssist" 2 "SnowWet" 1 "Sport" 0 "Normal";
VAL_ 381 EngOilSrvcMsgTxt_D_Rq 7 "NotUsed3" 6 "NotUsed2" 5 "NotUsed1" 4 "ResetComplete" 3 "ResetInProgress" 2 "ChangeOilNow" 1 "ChangeOilSoon" 0 "NoText";
VAL_ 381 RunDryPrevent_B_Stat 1 "True" 0 "False";
VAL_ 381 WaterInFuel 1 "On" 0 "Off";
VAL_ 381 GlowIndication 1 "On" 0 "Off";
VAL_ 380 EngOilLvlWarn_D_Rq1 7 "Undefined_3" 6 "Undefined_2" 5 "Engine_Oil_Monitor_Fault" 3 "Engine_Oil_High" 2 "Engine_Oil_Critical_Low" 1 "Engine_Oil_Low" 0 "No_Message" 4 "Engine_Oil_Critical_High";
VAL_ 380 EngExhBrkOnLamp_B_Rq 1 "On" 0 "Off";
VAL_ 380 EngExhBrkAutoLamp_B_Rq 1 "On" 0 "Off";
VAL_ 380 EngExhBrkMde_D_Actl 6 "ExhBrkDisable_NoError" 5 "ExhBrkActive_AUTO" 4 "ExhBrkActive_ON" 3 "ExhBrkRequest_AUTO" 2 "ExhBrkRequest_ON" 1 "ExhBrkNoRequest_OFF" 0 "ExhBrkUnavailable_Error";
VAL_ 377 HvacAirFullOut_B_Rq 1 "Yes" 0 "No";
VAL_ 377 FuelFillInlet_B_Dsply 1 "Yes" 0 "No";
VAL_ 377 EngSrvcRqd_B_Rq 1 "Engine_Service_Required" 0 "No_engine_service_required";
VAL_ 377 OdoCount 255 "Invalid";
VAL_ 377 FuelFilterLamp_B_Dsply 1 "On" 0 "Off";
VAL_ 377 AirCondRec_B_Rq 1 "Yes" 0 "No";
VAL_ 377 AirCondClutch_B_Stats 1 "Yes" 0 "No";
VAL_ 376 GasPrtc_D_RqDsply 7 "NotUsed_5" 6 "NotUsed_4" 5 "NotUsed_3" 4 "NotUsed_2" 3 "NotUsed_1" 2 "GpfOverLimit" 1 "GpfAtLimit" 0 "NormalOperation";
VAL_ 376 DynoMde_B_Cmd 1 "Two_Wheel_Dyno" 0 "Normal_Operation";
VAL_ 376 AslIconDsply_D_Rq 3 "On_Passive_Overridden" 2 "On_Active" 1 "On_Passive" 0 "Off";
VAL_ 376 AslChime_B_Rq 1 "Yes" 0 "No";
VAL_ 376 HvacHtrCore2_Te_Actl 1023 "Faulty";
VAL_ 376 EcssLamp_D_RqDsply 3 "Not_Used" 2 "Flash" 1 "On" 0 "Off";
VAL_ 376 AirAmbTe_D_Qf 3 "OK" 2 "Not_Within_Specifications" 1 "No_Data_Exists" 0 "Faulty";
VAL_ 376 AirAmb_P_Actl 63 "Fault" 62 "NoDataExists";
VAL_ 373 DieslPrtc2_D_RqDsply 15 "NotUsed4" 14 "NotUsed3" 13 "NotUsed2" 12 "NotUsed1" 11 "OCR_ExhFilterClean_Stopped" 10 "OCR_ExhFilterCleaned" 9 "RgnOff_AtLimit" 8 "RgnOff_Overloaded" 7 "RgnOff_Loaded" 6 "Exhaust_Filter_Full" 5 "DPF_Overlimit" 4 "DPF_AtLimit" 3 "ExhFilter_Drive_Completed" 2 "Cleaning_Exhaust_Filter" 1 "DPF_Overloaded" 0 "DPF_Normal_Operation";
VAL_ 373 DieslPrtcRgen_D_Actl 3 "Undefined" 2 "Regen_Level_2" 1 "Regen_Level_1" 0 "No_regen";
VAL_ 373 EngTeColdPrtct_D_Stats 3 "Engine_Warm_RdcPwr" 2 "OK_to_Drive" 1 "Engine_Warm_PlsWait" 0 "Normal_Operation";
VAL_ 373 EngExhOvrTe_B_RqDsply 1 "Active" 0 "Inactive";
VAL_ 359 PrplWhlRgenMn_Tq_Actl 8191 "Faulty";
VAL_ 359 ElPw_D_StatStrtStop 15 "NotUsed6" 14 "NotUsed5" 13 "NotUsed4" 12 "NotUsed3" 11 "NotUsed2" 10 "NotUsed1" 9 "Supported_Level_4" 8 "Supported_Level_3" 7 "Supported_Level_2" 6 "Supported_Level_1" 5 "Limited_Support" 4 "Fault_Limited" 3 "LV_Event_in_Progress" 2 "Not_Supported_Imminent" 1 "Supported_All" 0 "Not_Supported";
VAL_ 359 PrplWhlTot2_Tq_Actl 65535 "Fault" 65534 "NoDataExists";
VAL_ 359 PwPckTq_D_Stat 3 "PwPckOn_TqAvailable" 2 "StartInPrgrss_TqNotAvail" 1 "PwPckOn_TqNotAvailable" 0 "PwPckOff_TqNotAvailable";
VAL_ 359 Eng_D_Stat 3 "NotUsed" 2 "EngAutoStopped" 1 "EngOn" 0 "EngOff";
VAL_ 359 PlgActvArb_B_Actl 1 "On" 0 "Off";
VAL_ 359 ElPw_D_Stat 7 "NotUsed_3" 6 "NotUsed_2" 5 "NotUsed_1" 4 "Fault_Limited" 3 "LV_Event_In_Progress" 2 "Not_Supported_Imminent" 1 "Supported" 0 "Not_Supported";
VAL_ 359 TrnAinTq_D_Qf 3 "OK" 2 "Not_Within_Specifications" 1 "No_Data_Exists" 0 "Faulty";
VAL_ 358 StopStrtStdby_D_Indic 6 "NotUsed2" 5 "Telltale_Struck_Out" 4 "Telltale_Flashing_Amber" 3 "Telltale_On_Amber" 2 "Telltale_Flashing_Green" 1 "Telltale_On_Green" 0 "Telltale_Off" 7 "NotUsed3";
VAL_ 358 StopStrtIODTxt_D_Rq 31 "Message31" 30 "Message30" 29 "Message29" 28 "Message28" 27 "Message27" 26 "Message26" 25 "Message25" 24 "Message24" 23 "Message23" 22 "Message22" 21 "Message21" 20 "Message20" 19 "Message19" 18 "Message18" 17 "Message17" 16 "Message16" 15 "Message15" 14 "Message14" 13 "Message13" 12 "Message12" 11 "Message11" 10 "Message10" 9 "Message9" 8 "Message8" 7 "Message7" 6 "Message6" 5 "Message5" 4 "Message4" 3 "Message3" 2 "Message2" 1 "Message1" 0 "NoMessage";
VAL_ 358 StopStrtDrvMde_D_Indic 3 "NotUsed" 2 "StartStop_IndirectDeselect" 1 "StopStart_Deselected" 0 "StopStart_Selected";
VAL_ 358 StopStrtMsgTxt_D_Rq 15 "Message_15" 14 "Message_14" 13 "Message_13" 12 "Message_12" 11 "Message_11" 10 "Message_10" 9 "Message_9" 8 "Message_8" 7 "Message_7" 6 "Message_6" 5 "Message_5" 4 "Message_4" 3 "Message_3" 2 "Message_2" 1 "Message_1" 0 "NoMessage";
VAL_ 358 OdoTripVerify_L_Actl 16777215 "Fault";
VAL_ 358 HiElPwInhbt_B_Stat 1 "Inhibit" 0 "No_Inibit";
VAL_ 358 AutoStopPtDelta_I_Est 255 "Fault";
VAL_ 357 BPedDrvAppl_D_QF 3 "OK" 2 "Not_Within_Specifications" 1 "No_Data_Exists" 0 "Faulty";
VAL_ 357 CmbbDeny_B_ActlPrpl 1 "Yes" 0 "No";
VAL_ 357 PrplTqMnSat_B_Actl 1 "Yes" 0 "No";
VAL_ 357 BpedDrvAppl_D_Actl 3 "_Not_Allowed" 2 "Driver_Braking" 1 "Driver_Not_Braking" 0 "Not_Allowed";
VAL_ 357 CmbbEngTqMn_B_Actl 1 "Yes" 0 "No";
VAL_ 357 Veh_V_DsplyCcSet 255 "Fault" 254 "Unknown";
VAL_ 357 AccEngStat_D_Actl 7 "Undefined_2" 6 "Undefined_1" 5 "ACCSoonCancel_due_Low_Spd" 4 "Shift_Down_Recommendation" 3 "Shift_Up_Recommendation" 2 "ACCNotAllowedToBeActivated" 1 "ACCStandby_due_Auto_Cancel" 0 "Normal_Operation";
VAL_ 357 CcMde_D_Actl 7 "TapDownWaiting" 6 "TapUpWaiting" 5 "Resuming_Low" 4 "Resuming_High" 3 "Decelerating" 2 "Accelerating" 1 "Keeping_Speed" 0 "Not_Active";
VAL_ 357 CcStat_D_Actl 7 "Undefined_2" 6 "Undefined_1" 5 "Active" 4 "Active_Que_Assist" 3 "Standby" 2 "Standby_Denied" 1 "Denied" 0 "Off";
VAL_ 357 CcOvrrdActv_B_Actl 1 "Cruise_Overridden" 0 "Cruise_Req_Not_Overridden";
VAL_ 357 AccStopMde_D_Rq 3 "Stop_Mode_Active" 2 "EPBApplyOrBrakeReleaseWarn" 1 "Limit_Rolling_Speed" 0 "Stop_Mode_Not_Active";
VAL_ 355 AutoRgenTxt_B_RqDsply 1 "AutExhFilterCleanOFF" 0 "AutExhFilterCleanON";
VAL_ 355 AccFllwMdeActv_B_Actl 1 "Active" 0 "Inactive";
VAL_ 355 EngPtoMde_D_Actl 7 "Undefined" 6 "Split_Shaft_Stationary" 5 "Not_Used_2" 4 "PTO_Mobile" 3 "Not_Used_1" 2 "PTO_Stationary" 1 "BCP" 0 "Off";
VAL_ 355 ManRgenTxt_D_RqDsply 7 "NotUsed3" 6 "NotUsed2" 5 "NotUsed1" 4 "Cleaning_Aborted_Stopped" 3 "Cleaning_Completed" 2 "Cleaning_In_Progress" 1 "Cleaning_Allowed" 0 "Cleaning_Not_Allowed";
VAL_ 355 ManRgenSoot_Pc_RqDsply 127 "Fault";
VAL_ 355 DieslMsgTxt_D_Rq 3 "NotUsed2" 2 "NotUsed1" 1 "ReducedEnginePower" 0 "NoMessage";
VAL_ 342 EngOvrhtMitgActv_D_Ind 3 "Undefined" 2 "Mode2" 1 "Mode1" 0 "Normal_Mode";
VAL_ 342 EngClntTe_D_Qf 3 "OK" 2 "Not_Within_Specifications" 1 "No_Data_Exists" 0 "Faulty";
VAL_ 342 EngOil_Te_Actl 255 "Fault" 254 "Unknown";
VAL_ 71 immoTarget1Status 7 "Unused4" 6 "Unused3" 5 "Unused2" 4 "Unused1" 3 "DISABLED_RESET   " 2 "ENABLED_NONMOTIVE_START" 1 "ENABLED_MOTIVE_START" 0 "DISABLED";
VAL_ 71 immoTarget1Cmd 7 "Unused4" 6 "Unused3" 5 "Unused2" 4 "Unused1" 3 "TARGET1_IDBLOCK2" 2 "TARGET1_IDBLOCK1" 1 "CHALLENGE" 0 "IDLE";
VAL_ 1006 PersIndexIpmb_D_Actl 7 "Unused_3" 6 "Unused_2" 5 "Unused_1" 4 "Vehicle" 3 "PERS_4" 2 "PERS_3" 1 "PERS_2" 0 "PERS_1";
VAL_ 820 AhbStatGfhbFdbk_D_Actl 3 "GfhbHighBeamFullyOn" 2 "GfhbHighBeamPartlyOn" 1 "GfhbHighBeamOff" 0 "GfhbUnavailable";
VAL_ 820 HeadLghtDrvSide_B_Stat 1 "Left_Hand_Traffic" 0 "Right_Hand_Traffic";
VAL_ 820 HeadLghtHiOn_B_StatHcm 1 "On" 0 "Off";
VAL_ 820 Adaptive_Hdlmp_Fault 1 "Yes" 0 "No";
VAL_ 137 SteWhlOffstRq_D_Stat 3 "Faulty" 2 "NoDataExists" 1 "Allow_External_Angle_Req" 0 "Deny_External_Angle_Req";
VAL_ 137 SteWhlOffst_An_TotActl 32767 "Faulty" 32766 "NoDataExists";
VAL_ 137 SteWhlBrkOffst_An_Actl 32767 "Faulty" 32766 "NoDataExists";
VAL_ 129 SelDrvMdeSwtch_D_Stat4 3 "Faulty" 2 "SwitchState2" 1 "SwitchState1" 0 "NotPressed";
VAL_ 129 SteWhlSwtchView_B_Stat 1 "Pressed" 0 "Not_Pressed";
VAL_ 129 SteWhlSwtchSet_B_Stat 1 "Pressed" 0 "Not_Pressed";
VAL_ 129 SteWhlSwtchPhon_B_Stat 1 "Pressed" 0 "Not_Pressed";
VAL_ 129 SteWhlSwtchNav_B_Stat 1 "Pressed" 0 "Not_Pressed";
VAL_ 129 SteWhlSwtchMed_B_Stat 1 "Pressed" 0 "Not_Pressed";
VAL_ 129 SteWhlSwtchIod_B_Stat 1 "Pressed" 0 "Not_Pressed";
VAL_ 129 SteWhlSwtchHud_B_Stat 1 "Pressed" 0 "Not_Pressed";
VAL_ 129 SteWhlSwtchBack_B_Stat 1 "Pressed" 0 "Not_Pressed";
VAL_ 129 SteWhlSwtchMenu_B_Stat 1 "Pressed" 0 "Not_Pressed";
VAL_ 129 SteEffortInc_B_RqDrv 1 "Pressed" 0 "Not_Pressed";
VAL_ 129 SelDrvMdeInc_B_RqDrv 1 "Pressed" 0 "Not_Pressed";
VAL_ 129 SelDrvMdeDec_B_RqDrv 1 "Pressed" 0 "Not_Pressed";
VAL_ 129 SuspDampInc_B_RqDrv 1 "Pressed" 0 "Not_Pressed";
VAL_ 129 SteWhlSwtchUp_B_Stat 1 "Pressed" 0 "Not_Pressed";
VAL_ 129 SteWhlSwtchRght_B_Stat 1 "Pressed" 0 "Not_Pressed";
VAL_ 129 SteWhlSwtchOk_B_Stat 1 "Pressed" 0 "Not_Pressed";
VAL_ 129 SteWhlSwtchLeft_B_Stat 1 "Pressed" 0 "Not_Pressed";
VAL_ 129 SteWhlSwtchDown_B_Stat 1 "Pressed" 0 "Not_Pressed";
VAL_ 129 SteWhlSwtchHome_B_Stat 1 "Pressed" 0 "Not_Pressed";
VAL_ 129 SteWhlSwtchInfo_B_Stat 1 "Pressed" 0 "Not_Pressed";
VAL_ 935 SodRight_D_Stat 7 "NotUsed_3" 6 "NotUsed_2" 5 "NotUsed_1" 4 "Invalid" 3 "Disabled" 2 "On" 1 "Trailer_Tow_Off" 0 "Off";
VAL_ 935 CtaAlrtRight2_D_Stat 7 "NotUsed3" 6 "NotUsed2" 5 "NotUsed1" 4 "AlertZone4" 3 "AlertZone3" 2 "AlertZone2" 1 "AlertZone1" 0 "Off";
VAL_ 935 BttRight_D_Stat 7 "NotUsed" 6 "Disabled" 5 "Off" 4 "OffTemp" 3 "NotConnected" 2 "Pending" 1 "Connected" 0 "NotDetermined";
VAL_ 935 BttRight_D_RqDrv 3 "NotUsed" 2 "Request" 1 "NoRequest" 0 "Null";
VAL_ 935 CtaBrkRightMsgTxt_B_Rq 1 "Enable" 0 "Disable";
VAL_ 935 CtaRightBrkEnbl_B_Rq 1 "Enable" 0 "Disable";
VAL_ 935 CtaRightBrkDecel_B_Rq 1 "Enable" 0 "Disable";
VAL_ 935 CtaSnsRight_D_Stat 3 "Invalid" 2 "System_Failure" 1 "Blocked" 0 "Clear";
VAL_ 935 CtaAlrtRight_D_Stat 1 "On" 0 "Off";
VAL_ 935 CtaRight_D_Stat 7 "NotUsed_3" 6 "NotUsed_2" 5 "NotUsed_1" 4 "Invalid" 3 "Disabled" 2 "On" 1 "Trailer_Tow_Off" 0 "Off";
VAL_ 935 SodSnsRight_D_Stat 3 "Second_Warning_Audio" 2 "System_Failure" 1 "Blocked" 0 "Clear";
VAL_ 935 SodAlrtRight_D_Stat 3 "Bulb_Proveout" 2 "Flash" 1 "On" 0 "Off";
VAL_ 935 SodDetctRight_D_Stat 4 "Sensor_Blocked" 3 "Sensor_Fault" 2 "Flash_On" 1 "Alert_On" 0 "AlertOff_FlashOff_SensrClr";
VAL_ 1108 RCMSerialNoByte8 255 "Invalid" 254 "Unknown";
VAL_ 1108 RCMSerialNoByte7 255 "Invalid" 254 "Unknown";
VAL_ 1108 RCMSerialNoByte6 255 "Invalid" 254 "Unknown";
VAL_ 1108 RCMSerialNoByte5 255 "Invalid" 254 "Unknown";
VAL_ 1108 RCMSerialNoByte4 255 "Invalid" 254 "Unknown";
VAL_ 1108 RCMSerialNoByte3 255 "Invalid" 254 "Unknown";
VAL_ 1108 RCMSerialNoByte2 255 "Invalid" 254 "Unknown";
VAL_ 1108 RCMSerialNoByte1 255 "Invalid" 254 "Unknown";
VAL_ 261 ChrgStatDsply_D_Rq 3 "NotUsed_2" 2 "NotUsed_1" 1 "On" 0 "Off";
VAL_ 261 NextUsageTimeToggle_Rq 0 "Inactive" 2 "Disable" 1 "Enable";
VAL_ 261 LongTermParking_Rq 0 "Inactive" 1 "On" 2 "Off" 3 "NotUsed";
VAL_ 261 ModemReset_D_Rq 15 "NotUsed_11" 14 "NotUsed_10" 13 "NotUsed_9" 12 "NotUsed_8" 11 "NotUsed_7" 10 "NotUsed_6" 9 "NotUsed_5" 8 "NotUsed_4" 7 "NotUsed_3" 6 "BrandConnectReset2" 5 "BrandConnectReset1" 4 "CcsReset" 3 "OnlineTrafficReset" 2 "PaakReset" 1 "WifiHotspotReset" 0 "Null";
VAL_ 261 StopStrtDrvMde_B_RqBtn3 1 "Pressed" 0 "Not_Pressed";
VAL_ 261 TCU_ESN_D_Rq 3 "NotUsed" 2 "TCU_ESN_Request" 1 "NoRequest" 0 "Inactive";
VAL_ 261 FactoryReset_Rq 1 "ResetFactoryDefaults" 0 "Inactive";
VAL_ 1146 TrlrAidSwtch_D_RqDrv 3 "Faulty" 2 "NotUsed" 1 "Pressed" 0 "Not_Pressed";
VAL_ 1146 TrlrAidCtl_U_RqDrv 4095 "Faulty" 4094 "NoDataExists";
VAL_ 533 DcacGfciTestBttn_B_Stat 1 "Pressed" 0 "Not_Pressed";
VAL_ 533 DcacPwResetButtn_B_Stat 1 "Pressed" 0 "Not_Pressed";
VAL_ 533 DcacPwOffButtn_B_Stat 1 "Pressed" 0 "Not_Pressed";
VAL_ 533 DcacPwLoButtn_B_Stat 1 "Pressed" 0 "Not_Pressed";
VAL_ 533 DcacPwHiButtn_B_Stat 1 "Pressed" 0 "Not_Pressed";
VAL_ 533 DcacPwButtn_B_Falt 1 "Faulted" 0 "NotFaulted";
VAL_ 533 TrlrHitch_D_RqMnu 15 "NotUsed_10" 14 "NotUsed_9" 13 "NotUsed_8" 12 "NotUsed_7" 11 "NotUsed_6" 10 "NotUsed_5" 9 "NotUsed_4" 8 "NotUsed_3" 7 "NotUsed_2" 6 "NotUsed_1" 5 "GoToTraileringDomain" 4 "Confirm" 3 "TurnOnTba" 2 "TurnOnAutohitch" 1 "CancelAutohitch" 0 "NoRequest";
VAL_ 533 AutoEpbZoomView_B_Stat 1 "Active" 0 "Inactive";
VAL_ 533 AutoEpbButtn_B_Stat 1 "Pressed" 0 "Not_Pressed";
VAL_ 533 TrlrAidMde_D_Rq 3 "Mode_3" 2 "Mode_2" 1 "Mode_1" 0 "NoRequest";
VAL_ 533 TCU_Init_Actvtn_St 3 "NotUsed" 2 "InitialActivateDeny" 1 "InitialActivateAccept" 0 "Invalid";
VAL_ 533 TCU_Final_Actvtn_St 3 "NotUsed" 2 "FinalActivateDeny" 1 "FinalActivateAccept" 0 "Invalid";
VAL_ 533 OtaTrg_D_Stat 3 "NotUsed_1" 2 "Accepted" 1 "NotAccepted" 0 "Null";
VAL_ 533 OnbChrgGoTTouch_D_Rq 3 "NotUsed" 2 "On" 1 "Off" 0 "Null";
VAL_ 533 OnbChrgGoTPrcond_D_Rq 3 "High" 2 "Medium" 1 "Low" 0 "Off";
VAL_ 533 OnbChrgGoTOn_D_Rq 3 "NotUsed" 2 "On" 1 "Off" 0 "Null";
VAL_ 533 OnbChrgGoTMnte_D_Rq 15 "NotUsed_4" 14 "NotUsed_3" 13 "NotUsed_2" 12 "NotUsed_1" 11 "Minute_55" 10 "Minute_50" 9 "Minute_45" 8 "Minute_40" 7 "Minute_35" 6 "Minute_30" 5 "Minute_25" 4 "Minute_20" 3 "Minute_15" 2 "Minute_10" 1 "Minute_5" 0 "Minute_0";
VAL_ 533 OnbChrgGoTHr_T_Rq 31 "Faulty" 30 "NoDataExists";
VAL_ 533 OnbChrgGoTExtHtr_D_Rq 3 "NotUsed" 2 "On" 1 "Off" 0 "Null";
VAL_ 533 OnbChrgGoTDelete_B_Rq 1 "Request" 0 "NoRequest";
VAL_ 533 OnbChrgClearAll_B_Rq 1 "Request" 0 "NoRequest";
VAL_ 533 PaakMyKey_D_Rq 3 "NotUsed" 2 "ConfirmNewPaakMyKey" 1 "RequestNewPaakMyKey" 0 "None";
VAL_ 533 OnbChrgGoTUpdate_B_Rq 1 "Request" 0 "NoRequest";
VAL_ 1041 ElCmprUHi_D_Stat 3 "Overvoltage" 2 "Undervoltage" 1 "InRange" 0 "Undetermined";
VAL_ 1041 ElCmprOverTe_D_Stat 3 "OverTempStop" 2 "OverTempWarning" 1 "Normal" 0 "Undefined";
VAL_ 1041 ElCmpr_N_Actl 255 "Invalid";
VAL_ 1041 ElCmpr_Pw_Actl 255 "Invalid";
VAL_ 1041 ElCmpr_D_Stat 7 "Signal_Invalid" 6 "Comp_Off_ActlSpd_Abnormal" 5 "Comp_Off_TrgtSpd_OutRange" 4 "Comp_Shutdown" 3 "Comp_Stopped_Self_Protect" 2 "Comp_Degraded" 1 "Comp_On" 0 "Comp_Off";
VAL_ 1041 ElCmprPerfErr_D_Falt 3 "NotUsed" 2 "Pass" 1 "Fail" 0 "Not_Diagnose_Yet";
VAL_ 1041 ElCmprInnrErr_D_Falt 3 "NotUsed" 2 "Pass" 1 "Fail" 0 "Not_Diagnose_Yet";
VAL_ 1041 ElCmprLostComm_D_Falt 3 "NotUsed" 2 "Pass" 1 "Fail" 0 "Not_Diagnose_Yet";
VAL_ 1041 ElCmprOverLoad_D_Falt 3 "NotUsed" 2 "Pass" 1 "Fail" 0 "Not_Diagnose_Yet";
VAL_ 1041 ElCmprOverTe_D_Falt 3 "NotUsed" 2 "Pass" 1 "Fail" 0 "Not_Diagnose_Yet";
VAL_ 1041 ElCmprBattURng_D_Falt 3 "NotUsed" 2 "Pass" 1 "Fail" 0 "Not_Diagnose_Yet";
VAL_ 1041 ElCmprBattSysU_D_Falt 3 "NotUsed" 2 "Pass" 1 "Fail" 0 "Not_Diagnose_Yet";
VAL_ 1041 ElCmprSysU_D_Falt 3 "NotUsed" 2 "Pass" 1 "Fail" 0 "Not_Diagnose_Yet";
VAL_ 1067 BattULoAuxIsol_D_Rq 3 "Undefined" 2 "Retain" 1 "Close" 0 "Open";
VAL_ 1067 BattULoAux_U_Rq 4095 "Faulty";
VAL_ 1067 BattULoAux_I_Actl 4095 "Faulty";
VAL_ 1067 BattULoAux_D_Qlty 3 "OK" 2 "Not_Within_Specifications" 1 "Eval_In_Progress" 0 "Faulty";
VAL_ 1067 BattULoAux_U_Actl 255 "Faulty";
VAL_ 1067 BattULoAux_B_Falt 1 "Fault" 0 "No_Fault";
VAL_ 1112 BattTracChrgSustn_B_Rq 1 "Active" 0 "Inactive";
VAL_ 1112 BattTracCnnct_D_Cmd 7 "NotUsed_3" 6 "NotUsed_2" 5 "NotUsed_1" 4 "WeldCheck" 3 "OkToDischarge" 2 "Closed" 1 "Precharge" 0 "Open";
VAL_ 1112 BattTracHvilOpen_B_Stat 1 "Open" 0 "Closed";
VAL_ 1112 BattTracDcdcDis_B_Rq 1 "Yes" 0 "No";
VAL_ 1112 HtrnClntPump_D_Stat 3 "Faulty" 2 "No_Data_Exists" 1 "On" 0 "Off";
VAL_ 1112 BattTracClntPmp_D_Stat 3 "Faulty" 2 "No_Data_Exists" 1 "On" 0 "Off";
VAL_ 139 AfsPw_B_Rq 1 "Yes" 0 "No";
VAL_ 139 AccButtnGpTogglePress2 1 "Pressed" 0 "Not_Pressed";
VAL_ 139 TjaButtnOnOffPress2 1 "Pressed" 0 "Not_Pressed";
VAL_ 139 ActvFrontSteMsgTxt_D_Rq 7 "Message7" 6 "Message6" 5 "Message5" 4 "Message4" 3 "Message3" 2 "Message2" 1 "Message1" 0 "NoMessage";
VAL_ 139 ActvFrontSteLck_D_Stat 3 "Test_passed" 2 "Test_failed" 1 "Test_cannot_run" 0 "Test_incomplete";
VAL_ 139 SelDrvMdeAdptSte_D_Stat 3 "Faulty" 2 "TemporarilyNotAvailable" 1 "Available" 0 "NotAvailable";
VAL_ 139 AslButtnOnOffPress2 1 "Button_Pressed" 0 "Button_Not_Pressed";
VAL_ 139 AslButtnOnOffCnclPres2 1 "Button_Pressed" 0 "Button_Not_Pressed";
VAL_ 139 CcButtnOnPress2 1 "Button_Pressed" 0 "Button_Not_Pressed";
VAL_ 139 CcButtnOnOffPress2 1 "Button_Pressed" 0 "Button_Not_Pressed";
VAL_ 139 CcButtnOnOffCnclPress2 1 "Button_Pressed" 0 "Button_Not_Pressed";
VAL_ 139 CcButtnOffPress2 1 "Button_Pressed" 0 "Button_Not_Pressed";
VAL_ 139 CcAsllButtnResPress2 1 "Button_Pressed" 0 "Button_Not_Pressed";
VAL_ 139 CcAslButtnSetPress2 1 "Button_Pressed" 0 "Button_Not_Pressed";
VAL_ 139 CcAslButtnSetIncPress2 1 "Button_Pressed" 0 "Button_Not_Pressed";
VAL_ 139 CcAslButtnSetDecPress2 1 "Button_Pressed" 0 "Button_Not_Pressed";
VAL_ 139 CcAslButtnResIncPress2 1 "Button_Pressed" 0 "Button_Not_Pressed";
VAL_ 139 CcAslButtnResDecPress2 1 "Button_Pressed" 0 "Button_Not_Pressed";
VAL_ 139 CcAslButtnOnPress2 1 "Button_Pressed" 0 "Button_Not_Pressed";
VAL_ 139 CcAslButtnOnOffCncl2 1 "Button_Pressed" 0 "Button_Not_Pressed";
VAL_ 139 CcAslButtnOffCnclPres2 1 "Button_Pressed" 0 "Button_Not_Pressed";
VAL_ 139 CcAslButtnIndxIncPres2 1 "Button_Pressed" 0 "Button_Not_Pressed";
VAL_ 139 CcAslButtnIndxDecPres2 1 "Button_Pressed" 0 "Button_Not_Pressed";
VAL_ 139 CcAslButtnDeny_B_Actl2 1 "Yes" 0 "No";
VAL_ 139 CcAslButtnCnclResPres2 1 "Button_Pressed" 0 "Button_Not_Pressed";
VAL_ 139 CcAslButtnCnclPress2 1 "Button_Pressed" 0 "Button_Not_Pressed";
VAL_ 139 AccButtnGapIncPress2 1 "Button_Pressed" 0 "Button_Not_Pressed";
VAL_ 139 AccButtnGapDecPress2 1 "Button_Pressed" 0 "Button_Not_Pressed";
VAL_ 1121 SelDrvMdeSwtch_D_Stat 3 "Faulty" 2 "SwitchState2" 1 "SwitchState1" 0 "NotPressed";
VAL_ 1121 SelDrvMdeCnt_D_Stat 4 "FourCounts" 3 "ThreeCounts" 2 "TwoCounts" 1 "OneCount" 0 "ZeroCounts" 7 "SevenOrMoreCounts" 6 "SixCounts" 5 "FiveCounts";
VAL_ 1120 DrvSlipCtlMde_B_Rq3 1 "Pressed" 0 "Not_Pressed";
VAL_ 1120 HybMdeSwtch_B_Rq 1 "Pressed" 0 "Not_Pressed";
VAL_ 1120 TrailCtlSwtch_B_Stat3 1 "Pressed" 0 "Not_Pressed";
VAL_ 1120 RearDiffLck_D_RqDrv 3 "Faulty" 2 "NoRequest" 1 "On" 0 "Off";
VAL_ 1120 AwdMde_D_RqDrv 7 "Faulty" 6 "NotUsed2" 5 "NoRequest" 4 "Neutral" 3 "FourByFourLow" 2 "FourByFourHigh" 1 "FourByFourAuto" 0 "FourByTwo";
VAL_ 1120 HdcSwtchPos_B_Actl 1 "Pressed" 0 "Not_Pressed";
VAL_ 1050 AutoHoldSwtch_D_Stat 3 "Faulty" 2 "NotUsed" 1 "Pressed" 0 "Not_Pressed";
VAL_ 1050 LpdbPtc3_B_Rq 1 "On" 0 "Off";
VAL_ 1050 LpdbPtc2_B_Rq 1 "On" 0 "Off";
VAL_ 1050 LpdbPtc1_B_Rq 1 "On" 0 "Off";
VAL_ 1050 LpdbHeatWiprPrk_B_Rq 1 "On" 0 "Off";
VAL_ 1050 LpdbDfrstRearOn_B_Rq 1 "On" 0 "Off";
VAL_ 1050 SteWhlHeat_D_Rq 15 "NotUsed6" 14 "NotUsed5" 13 "NotUsed4" 12 "NotUsed3" 11 "NotUsed2" 10 "NotUsed1" 9 "Reserved_3" 8 "Reserved_2" 7 "Reserved_1" 6 "Level_3_Heating" 5 "Level_3_Heating_LS" 4 "Level_2_Heating" 3 "Level_2_Heating_LS" 2 "Level_1_Heating" 1 "Level_1_Heating_LS" 0 "Off";
VAL_ 1050 MirrorHeatOn_B_Rq 1 "True" 0 "False";
VAL_ 1050 Remote_Start_QuietMode 1 "Quiet" 0 "Not_Quiet";
VAL_ 1050 Outside_Air_Temp_Stat 255 "Invalid" 254 "Unknown";
VAL_ 1137 RngPerChrgAvg_L_Dsply 4095 "Faulty" 4094 "NoDataExists";
VAL_ 1255 BalrRight4Threat_D_Stat 1 "Yes" 0 "No";
VAL_ 1255 BalrRight4Fast_B_Stat 1 "Yes" 0 "No";
VAL_ 1255 BalrRight4Dsply_B_Stat 1 "Yes" 0 "No";
VAL_ 1254 BalrRight3Threat_D_Stat 1 "Yes" 0 "No";
VAL_ 1254 BalrRight3Fast_B_Stat 1 "Yes" 0 "No";
VAL_ 1254 BalrRight3Dsply_B_Stat 1 "Yes" 0 "No";
VAL_ 1253 BalrRight2Threat_D_Stat 1 "Yes" 0 "No";
VAL_ 1253 BalrRight2Fast_B_Stat 1 "Yes" 0 "No";
VAL_ 1253 BalrRight2Dsply_B_Stat 1 "Yes" 0 "No";
VAL_ 1252 BalrRight1Threat_D_Stat 1 "Yes" 0 "No";
VAL_ 1252 BalrRight1Fast_B_Stat 1 "Yes" 0 "No";
VAL_ 1252 BalrRight1Dsply_B_Stat 1 "Yes" 0 "No";
VAL_ 1251 BalrLeft4Threat_D_Stat 1 "Yes" 0 "No";
VAL_ 1251 BalrLeft4Fast_B_Stat 1 "Yes" 0 "No";
VAL_ 1251 BalrLeft4Dsply_B_Stat 1 "Yes" 0 "No";
VAL_ 1250 BalrLeft3Threat_D_Stat 1 "Yes" 0 "No";
VAL_ 1250 BalrLeft3Fast_B_Stat 1 "Yes" 0 "No";
VAL_ 1250 BalrLeft3Dsply_B_Stat 1 "Yes" 0 "No";
VAL_ 1249 BalrLeft2Threat_D_Stat 1 "Yes" 0 "No";
VAL_ 1249 BalrLeft2Fast_B_Stat 1 "Yes" 0 "No";
VAL_ 1249 BalrLeft2Dsply_B_Stat 1 "Yes" 0 "No";
VAL_ 1248 BalrLeft1Threat_D_Stat 1 "Yes" 0 "No";
VAL_ 1248 BalrLeft1Fast_B_Stat 1 "Yes" 0 "No";
VAL_ 1248 BalrLeft1Dsply_B_Stat 1 "Yes" 0 "No";
VAL_ 1113 TrlrTrgtAcquire_D_Stat 7 "Faulty" 6 "NotUsed_2" 5 "NotUsed_1" 4 "RVCforTBA_Activated" 3 "Processing" 2 "TargetNotAcquired" 1 "TargetAcquired" 0 "Null";
VAL_ 1113 TrlrAnOffstDir_D_Calc 3 "NotUSed" 2 "Right" 1 "Left_or_Center" 0 "Null";
VAL_ 1113 TrlrAnCalib_B_Complt 1 "Yes" 0 "No";
VAL_ 1113 TrlrRvrse_D_Stat 3 "Faulty" 2 "TrailerReverseGuidanceLite" 1 "On" 0 "Off";
VAL_ 1113 TrlrAid_D2_Stat 15 "Faulty" 14 "NotUsed_4" 13 "NotUsed_3" 12 "NotUsed_2" 11 "NotUsed_1" 10 "DirtyCamera" 9 "IncorrectLighting" 8 "TrackingLost" 7 "TrackingUnknownConfidence" 6 "TrackingHighConfidence" 5 "TrackingMediumConfidence" 4 "TrackingLowConfidence" 3 "TurnRequested" 2 "DriveStraighRequested" 1 "Initializing" 0 "NotTracking";
VAL_ 1113 TrlrAid_An3_Actl 2047 "Faulty";
VAL_ 1113 TrlrAid_AnRate2_Actl 1023 "Faulty";
VAL_ 1113 HitchToVehAxle_L_Calc 255 "Faulty";
VAL_ 1105 TrlrAidSwtchLamp_B_Rq 1 "On" 0 "Off";
VAL_ 1105 TrlrHitchMsgTxt_D_Rq 31 "Message31" 30 "Message30" 29 "Message29" 28 "Message28" 27 "Message27" 26 "Message26" 25 "Message25" 24 "Message24" 23 "Message23" 22 "Message22" 21 "Message21" 20 "Message20" 19 "Message19" 18 "Message18" 17 "Message17" 16 "Message16" 15 "Message15" 14 "Message14" 13 "Message13" 12 "Message12" 11 "Message11" 10 "Message10" 9 "Message9" 8 "Message8" 7 "Message7" 6 "Message6" 5 "Message5" 4 "Message4" 3 "Message3" 2 "Message2" 1 "Message1" 0 "NoMessage" 63 "Message63" 47 "Message47";
VAL_ 1105 TrlrHitchIcon_D_Rq 15 "Icon15" 14 "Icon14" 13 "Icon13" 12 "Icon12" 11 "Icon11" 10 "Icon10" 9 "Icon9" 8 "Icon8" 7 "Icon7" 6 "Icon6" 5 "Icon5" 4 "Icon4" 3 "Icon3" 2 "Icon2" 1 "Icon1" 0 "NoIcon";
VAL_ 1105 TrlrHitchChime_D_Rq 7 "NotUsed_1" 6 "NotUsed_1" 5 "WarningChime" 4 "NonCriticalAlertChime" 3 "StopNowChime" 2 "ManeuveringReadyChime" 1 "TrailerFoundChime" 0 "NoChime";
VAL_ 1105 TrlrAidEnbl_D_RqAdas 7 "NotUsed_4" 6 "NotUsed_3" 5 "NotUsed_2" 4 "NotUsed_1" 3 "Deactivate" 2 "NotAvailable" 1 "ActiveTba" 0 "Inactive";
VAL_ 1105 TrlrRvrseMsgTxt_D2_Rq 31 "Message31" 30 "Message30" 29 "Message29" 28 "Message28" 27 "Message27" 26 "Message26" 25 "Message25" 24 "Message24" 23 "Message23" 22 "Message22" 21 "Message21" 20 "Message20" 19 "Message19" 18 "Message18" 17 "Message17" 16 "Message16" 15 "Message15" 14 "Message14" 13 "Message13" 12 "Message12" 11 "Message11" 10 "Message10" 9 "Message9" 8 "Message8" 7 "Message7" 6 "Message6" 5 "Message5" 4 "Message4" 3 "Message3" 2 "Message2" 1 "Message1" 0 "NoMessage";
VAL_ 1105 TrlrRvrseEnbl_D2_Stat 7 "NotUsed" 6 "TbaActiveExpertActive" 5 "TbaActiveExpertAvail" 4 "TbaOffTrgActive" 3 "TbaOffTrgSetup" 2 "TbaSetup" 1 "TbaActive" 0 "Inactive";
VAL_ 1105 RbaMsg_D_Rq 3 "Faulty" 2 "Unavailable" 1 "Off" 0 "Null";
VAL_ 1105 BrkDecel_B_RqRba 1 "Enable" 0 "Disable";
VAL_ 1105 BrkEnbl_B_RqRba 1 "Enable" 0 "Disable";
VAL_ 1105 Rba_D_Stat 3 "NotUsed" 2 "Disabled" 1 "On" 0 "Off";
VAL_ 1105 RbaAlrt_D_Dsply 3 "Both" 2 "Text" 1 "Graphic" 0 "Off";
VAL_ 1105 RbaMnu_D_Rq 3 "NotUsed" 2 "Active" 1 "Inactive" 0 "None";
VAL_ 1105 CamraFrntStat_D_Stat 3 "No_Data_Present" 2 "NotUsed" 1 "On" 0 "Off";
VAL_ 1105 TrlrHitchLamp_D_Rq2 1 "On" 0 "Off";
VAL_ 938 SidePrkSnsR2_D_Stat 15 "NotUsed" 14 "NotFullyScannedYet" 13 "NoObjectInSector" 12 "Zone12" 11 "Zone11" 10 "Zone10" 9 "Zone9" 8 "Zone8" 7 "Zone7" 6 "Zone6" 5 "Zone5" 4 "Zone4" 3 "Zone3" 2 "Zone2" 1 "Zone1" 0 "Off";
VAL_ 938 SidePrkSnsR1_D_Stat 15 "NotUsed" 14 "NotFullyScannedYet" 13 "NoObjectInSector" 12 "Zone12" 11 "Zone11" 10 "Zone10" 9 "Zone9" 8 "Zone8" 7 "Zone7" 6 "Zone6" 5 "Zone5" 4 "Zone4" 3 "Zone3" 2 "Zone2" 1 "Zone1" 0 "Off";
VAL_ 938 SidePrkSnsL2_D_Stat 15 "NotUsed" 14 "NotFullyScannedYet" 13 "NoObjectInSector" 12 "Zone12" 11 "Zone11" 10 "Zone10" 9 "Zone9" 8 "Zone8" 7 "Zone7" 6 "Zone6" 5 "Zone5" 4 "Zone4" 3 "Zone3" 2 "Zone2" 1 "Zone1" 0 "Off";
VAL_ 938 ApaMde_D_Stat 7 "NotUsed3" 6 "NotUsed2" 5 "NotUsed1" 4 "POA" 3 "PPA" 2 "SAPP" 1 "Off" 0 "Null";
VAL_ 938 ApaActvSd_D_Actl 3 "Dirver_Side" 2 "Passenger_Side" 1 "No_Side" 0 "Null";
VAL_ 938 PrkAidSwtch_B_Stat 1 "Pressed" 0 "Not_Pressed";
VAL_ 938 ApaMde_D_Avail 15 "NotUsed7" 14 "NotUsed6" 13 "NotUsed5" 12 "NotUsed4" 11 "NotUsed3" 10 "NotUsed2" 9 "NotUsed1" 8 "PPA_POA" 7 "SAPP_POA" 6 "POA" 5 "PPA" 4 "SAPP" 3 "SAPP_PPA_POA" 2 "SAPP_PPA" 1 "None" 0 "Null";
VAL_ 938 PrkAidSnsFrCrnr_D_Stat 15 "Zone_15" 14 "Zone_14" 13 "Zone_13" 12 "Zone_12" 11 "Zone_11" 10 "Zone_10" 9 "Zone_9" 8 "Zone_8" 7 "Zone_7" 6 "Zone_6" 5 "Zone_5" 4 "Zone_4" 3 "Zone_3" 2 "Zone_2" 1 "Zone_1" 0 "Off";
VAL_ 938 PrkAidSnsFrCntr_D_Stat 15 "Zone_15" 14 "Zone_14" 13 "Zone_13" 12 "Zone_12" 11 "Zone_11" 10 "Zone_10" 9 "Zone_9" 8 "Zone_8" 7 "Zone_7" 6 "Zone_6" 5 "Zone_5" 4 "Zone_4" 3 "Zone_3" 2 "Zone_2" 1 "Zone_1" 0 "Off";
VAL_ 938 PrkAidSnsFlCrnr_D_Stat 15 "Zone_15" 14 "Zone_14" 13 "Zone_13" 12 "Zone_12" 11 "Zone_11" 10 "Zone_10" 9 "Zone_9" 8 "Zone_8" 7 "Zone_7" 6 "Zone_6" 5 "Zone_5" 4 "Zone_4" 3 "Zone_3" 2 "Zone_2" 1 "Zone_1" 0 "Off";
VAL_ 938 PrkAidSnsFlCntr_D_Stat 15 "Zone_15" 14 "Zone_14" 13 "Zone_13" 12 "Zone_12" 11 "Zone_11" 10 "Zone_10" 9 "Zone_9" 8 "Zone_8" 7 "Zone_7" 6 "Zone_6" 5 "Zone_5" 4 "Zone_4" 3 "Zone_3" 2 "Zone_2" 1 "Zone_1" 0 "Off";
VAL_ 938 PrkBrkEl_B_RqFap 1 "Yes" 0 "No";
VAL_ 938 RpaChime_D_Rq 15 "Zone15_Chime" 14 "Zone14_Chime" 13 "Zone13_Chime" 12 "Zone12_Chime" 11 "Zone11_Chime" 10 "Zone10_Chime" 9 "Zone9_Chime" 8 "Zone8_Chime" 7 "Zone7_Chime" 6 "Zone6_Chime" 5 "Zone5_Chime" 4 "Zone4_Chime" 3 "Zone3_Chime" 2 "Zone2_Chime" 1 "Zone1_Chime" 0 "No_Chime";
VAL_ 938 FpaChime_D_Rq 15 "Zone15_Chime" 14 "Zone14_Chime" 13 "Zone13_Chime" 12 "Zone12_Chime" 11 "Zone11_Chime" 10 "Zone10_Chime" 9 "Zone9_Chime" 8 "Zone8_Chime" 7 "Zone7_Chime" 6 "Zone6_Chime" 5 "Zone5_Chime" 4 "Zone4_Chime" 3 "Zone3_Chime" 2 "Zone2_Chime" 1 "Zone1_Chime" 0 "No_Chime";
VAL_ 938 PrkAidMsgTxt_D_Rq 15 "All_Sns_Blk" 14 "R_Sns_ON_F_Sns_Blk" 13 "R_Sns_Blk_F_Sns_ON" 12 "R_Sns_Inactive_Trlr_atch" 11 "Not_Avail_Trlr_attchd" 10 "Fail_Mode_no_Chime" 9 "Fail_Mode_with_Chime" 8 "R_Sns_Trlr_F_Sns_Blk" 7 "NotUsed3" 6 "Park_Sys_Alternate_Mode" 5 "R_Snsrs_On_F_Snsrs_On" 4 "NotUsed2" 3 "Reset_Message_Warn" 2 "R_Snsrs_Off_F_Snsrs_On" 1 "R_Snsrs_On_F_Snsrs_Off" 0 "All_Park_Sensors_Off";
VAL_ 938 SidePrkSnsL1_D_Stat 15 "NotUsed" 14 "NotFullyScannedYet" 13 "NoObjectInSector" 12 "Zone12" 11 "Zone11" 10 "Zone10" 9 "Zone9" 8 "Zone8" 7 "Zone7" 6 "Zone6" 5 "Zone5" 4 "Zone4" 3 "Zone3" 2 "Zone2" 1 "Zone1" 0 "Off";
VAL_ 938 PrkAidAudioMute_B_Rq 1 "Enable" 0 "Disable";
VAL_ 939 ApaBrk_D_Rq 3 "NotUsed" 2 "LowDecel" 1 "HighDecel" 0 "NoRequest";
VAL_ 939 SidePrkSnsR4_D_Stat 15 "NotUsed" 14 "NotFullyScannedYet" 13 "NoObjectInSector" 12 "Zone12" 11 "Zone11" 10 "Zone10" 9 "Zone9" 8 "Zone8" 7 "Zone7" 6 "Zone6" 5 "Zone5" 4 "Zone4" 3 "Zone3" 2 "Zone2" 1 "Zone1" 0 "Off";
VAL_ 939 SidePrkSnsR3_D_Stat 15 "NotUsed" 14 "NotFullyScannedYet" 13 "NoObjectInSector" 12 "Zone12" 11 "Zone11" 10 "Zone10" 9 "Zone9" 8 "Zone8" 7 "Zone7" 6 "Zone6" 5 "Zone5" 4 "Zone4" 3 "Zone3" 2 "Zone2" 1 "Zone1" 0 "Off";
VAL_ 939 SidePrkSnsL4_D_Stat 15 "NotUsed" 14 "NotFullyScannedYet" 13 "NoObjectInSector" 12 "Zone12" 11 "Zone11" 10 "Zone10" 9 "Zone9" 8 "Zone8" 7 "Zone7" 6 "Zone6" 5 "Zone5" 4 "Zone4" 3 "Zone3" 2 "Zone2" 1 "Zone1" 0 "Off";
VAL_ 939 SidePrkSnsL3_D_Stat 15 "NotUsed" 14 "NotFullyScannedYet" 13 "NoObjectInSector" 12 "Zone12" 11 "Zone11" 10 "Zone10" 9 "Zone9" 8 "Zone8" 7 "Zone7" 6 "Zone6" 5 "Zone5" 4 "Zone4" 3 "Zone3" 2 "Zone2" 1 "Zone1" 0 "Off";
VAL_ 939 PrkAidChime_D_Stat 3 "Fault" 2 "No_Data_Exists" 1 "On" 0 "Off";
VAL_ 939 PrkAidSnsRlCntr_D_Stat 15 "Zone_15" 14 "Zone_14" 13 "Zone_13" 12 "Zone_12" 11 "Zone_11" 10 "Zone_10" 9 "Zone_9" 8 "Zone_8" 7 "Zone_7" 6 "Zone_6" 5 "Zone_5" 4 "Zone_4" 3 "Zone_3" 2 "Zone_2" 1 "Zone_1" 0 "Off";
VAL_ 939 PrkAidSnsRrCrnr_D_Stat 15 "Zone_15" 14 "Zone_14" 13 "Zone_13" 12 "Zone_12" 11 "Zone_11" 10 "Zone_10" 9 "Zone_9" 8 "Zone_8" 7 "Zone_7" 6 "Zone_6" 5 "Zone_5" 4 "Zone_4" 3 "Zone_3" 2 "Zone_2" 1 "Zone_1" 0 "Off";
VAL_ 939 PrkAidSnsRrCntr_D_Stat 15 "Zone_15" 14 "Zone_14" 13 "Zone_13" 12 "Zone_12" 11 "Zone_11" 10 "Zone_10" 9 "Zone_9" 8 "Zone_8" 7 "Zone_7" 6 "Zone_6" 5 "Zone_5" 4 "Zone_4" 3 "Zone_3" 2 "Zone_2" 1 "Zone_1" 0 "Off";
VAL_ 939 PrkAidSnsRlCrnr_D_Stat 15 "Zone_15" 14 "Zone_14" 13 "Zone_13" 12 "Zone_12" 11 "Zone_11" 10 "Zone_10" 9 "Zone_9" 8 "Zone_8" 7 "Zone_7" 6 "Zone_6" 5 "Zone_5" 4 "Zone_4" 3 "Zone_3" 2 "Zone_2" 1 "Zone_1" 0 "Off";
VAL_ 939 PrkAidRear_D_Stat 3 "Faulted" 2 "Unused" 1 "Enabled" 0 "Disabled";
VAL_ 939 PrkAidFront_D_Stat 3 "Faulted" 2 "Unused" 1 "Enabled" 0 "Disabled";
VAL_ 939 PrkAid_D_Falt 7 "NotUsed2" 6 "NotUsed1" 5 "Failure_Front_PSM_Sensors" 4 "No_Data_Exists" 3 "Failure_Rear_Sensors" 2 "Speaker_Fault" 1 "ECU_Fault" 0 "No_Fault";
VAL_ 939 ApaLongCtrlEnbl_D_Rq 1 "Enable" 0 "Disable";
VAL_ 939 PrkAidLamp_D_Rq 3 "Not_Used" 2 "Flash" 1 "On" 0 "Off";
VAL_ 937 TrnRng_D_RqFap 7 "NotUsed3" 6 "NotUsed2" 5 "NotUsed1" 4 "Backwards" 3 "Forwards" 2 "NoMotion" 1 "Immobilize" 0 "NoRequest";
VAL_ 937 FapLcDistToObj_L_Actl 255 "Faulty" 254 "NoDataExists";
VAL_ 936 ApaButtnPrssd_B_Stat 1 "Pressed" 0 "Not_Pressed";
VAL_ 936 ApaSys_D_Stat 7 "Faulty" 6 "Finished" 5 "NotAccessible" 4 "ApaCancelled" 3 "Overspeed" 2 "On" 1 "Off" 0 "Null";
VAL_ 936 ApaSteWhl_D_RqDrv 3 "TakeControl" 2 "RemoveHands" 1 "NoRequest" 0 "Null";
VAL_ 936 ApaSteScanMde_D_Stat 3 "Steering" 2 "Scanning" 1 "NotScanning" 0 "Null";
VAL_ 936 ApaSelSapp_D_Stat 3 "NotConfigured" 2 "NotSelectable" 1 "Selectable" 0 "Null";
VAL_ 936 ApaSelPpa_D_Stat 3 "NotConfigured" 2 "NotSelectable" 1 "Selectable" 0 "Null";
VAL_ 936 ApaSelPoa_D_Stat 3 "NotConfigured" 2 "NotSelectable" 1 "Selectable" 0 "Null";
VAL_ 936 ApaScan_D_Stat 3 "ParkSlotReady" 2 "ParkSlotFound" 1 "NoParkSlot" 0 "Null";
VAL_ 936 ApaLongCtl_D_RqDrv 7 "NotUsed3" 6 "NotUsed2" 5 "ReleaseBrake" 4 "DriveBackward" 3 "DriveForward" 2 "Stop" 1 "NoRequest" 0 "Null";
VAL_ 936 ApaGearShif_D_RqDrv 7 "NotUSed2" 6 "NotUsed1" 5 "ShiftToP" 4 "ShiftToN" 3 "ShiftToD" 2 "ShiftToR" 1 "NoRequest" 0 "Null";
VAL_ 936 ApaActvSide2_D_Stat 3 "NoSide" 2 "Right" 1 "Left" 0 "Null";
VAL_ 936 ApaAcsy_D_RqDrv 7 "CloseDoor" 6 "SelectSideRight" 5 "SelectSideLeft" 4 "CheckForObject" 3 "PressApaButton" 2 "SelectSide" 1 "NoRequest" 0 "Null";
VAL_ 936 ApaTrgtDist_D_Stat 15 "Step15" 14 "Step14" 13 "Step13" 12 "Step12" 11 "Step11" 10 "Step10" 9 "Step9" 8 "Step8" 7 "Step7" 6 "Step6" 5 "Step5" 4 "Step4" 3 "Step3" 2 "Step2" 1 "Step1" 0 "Off";
VAL_ 936 ApaChime_D_Rq 7 "NotUsed2" 6 "NotUsed1" 5 "Warning_Chime" 4 "Finish_Chime" 3 "Stop_Now_Chime" 2 "Spot_Ready_Chime" 1 "Spot_Found_Chime" 0 "No_Chime";
VAL_ 936 EPASExtAngleStatReq 1 "Request" 0 "NoRequest";
VAL_ 936 ExtSteeringAngleReq2 32767 "Invalid" 32766 "Unknown";
VAL_ 877 VehElEffAvg_No_Dsply 127 "Faulty" 126 "NoDataExists";
VAL_ 877 PwFlwFuelDrv_D_Dsply 7 "NotUsed_4" 6 "NotUsed_3" 5 "NotUsed_2" 4 "NotUsed_1" 3 "FlwFromFuelToAllWhls" 2 "FlwFromFuelToFrontWhls" 1 "FlwFromFuelToRearWhls" 0 "NoFlow";
VAL_ 877 PwFlwFuelClimt_B_Dsply 1 "On" 0 "Off";
VAL_ 877 PwFlwFuelBatt_B_Dsply 1 "On" 0 "Off";
VAL_ 877 PwFlwBattClimt_B_Dsply 1 "On" 0 "Off";
VAL_ 877 PwFlwBatt_D_Dsply 15 "NotUsed_8" 14 "NotUsed_7" 13 "NotUsed_6" 12 "NotUsed_5" 11 "NotUsed_4" 10 "NotUsed_3" 9 "NotUsed_2" 8 "NotUsed_1" 7 "FlwFromWallToBatt" 6 "FlwFromAllWhlsToBatt" 5 "FlwFromBattToAllWhls" 4 "FlwFromFrontWhlsToBatt" 3 "FlwFromBattToFrontWhls" 2 "FlwFromRearWhlsToBatt" 1 "FlwFromBattToRearWhls" 0 "NoFlow";
VAL_ 588 BattTracSoc2_Pc_Actl 16383 "Faulty" 16382 "NoDataExists";
VAL_ 588 BattTrac_Te_Actl 1023 "Fault" 1022 "Unknown";
VAL_ 588 BattTracDiagClr_B_Rq 1 "On" 0 "Off";
VAL_ 587 BattTracWarnLamp_B_Rq 1 "On" 0 "Off";
VAL_ 587 BattTracSrvcRqd_B_Rq 1 "On" 0 "Off";
VAL_ 389 HtrnOvrTeLamp_B_Dsply 1 "On" 0 "Off";
VAL_ 389 HtrnMil_D_Rq 3 "Not_Used" 2 "Flash" 1 "On" 0 "Off";
VAL_ 389 HtrnAin_UHi_Actl 1023 "Fault" 1022 "Unknown";
VAL_ 389 HtrnSrvcRqd_B_Dsply 1 "On" 0 "Off";
VAL_ 389 HtrnHvilOpen_B_Actl 1 "HVIL_is_Open" 0 "Normal_Operation";
VAL_ 389 PtWakeupDeltaT_T_Rq 2047 "Fault" 2046 "NoDataExists";
VAL_ 389 PreCondActv_B_Actl 1 "On" 0 "Off";
VAL_ 389 DrvCondTpRrDefrs_B_Rq 1 "On" 0 "Off";
VAL_ 389 BattTrac_I_EstVsc 32767 "Fault" 32766 "NoDataExists";
VAL_ 1009 ChrgCordUnlock_B_Rq 1 "Request" 0 "NoRequest";
VAL_ 1009 AutoHoldSwtch_D_Stat3 3 "Faulty" 2 "NotUsed" 1 "Pressed" 0 "Not_Pressed";
VAL_ 1009 TrlrTrgtAcquire_D_Rq 7 "NotUsed_2" 6 "NotUsed_1" 5 "ActivateRVCforTBA" 4 "CancelAcquisition" 3 "RetryAcquisition" 2 "AcquisitionSuccessful" 1 "StartAcquisition" 0 "Inactive";
VAL_ 1009 TrlrAidCancl_B_Rq 1 "Cancel" 0 "Null";
VAL_ 1009 CenterStackRing_D_Actl 3 "LimitedOn" 2 "On" 1 "Off" 0 "Null";
VAL_ 1009 ValetMode_D_Stat 3 "NotUsed" 2 "On" 1 "Off" 0 "Null";
VAL_ 1009 TrlrAidSetup_D_Stat 7 "Faulty" 6 "NotUsed_3" 5 "NotUsed_2" 4 "NotUsed_1" 3 "EnterParameters" 2 "EndSetup" 1 "BeginSetup" 0 "Null";
VAL_ 360 GsmSrvcRqd_B_Rq 1 "Yes" 0 "No";
VAL_ 360 TrnGearPwmFalt_B_Actl 1 "Yes" 0 "No";
VAL_ 360 GearButtnStuck_B_Actl 1 "Yes" 0 "No";
VAL_ 122 VehStrtInhbt_B_RqBatt 1 "Yes" 0 "No";
VAL_ 122 BattTracOffFst_D_Actl 3 "Unexpected_Contactor_Open" 2 "Restraints_Impact_Event" 1 "Interlock_Open" 0 "Normal";
VAL_ 122 BattTracOff_B_Actl 1 "Yes" 0 "No";
VAL_ 122 BattTracMil_D_Rq 3 "Not_Used" 2 "Flash" 1 "On" 0 "Off";
VAL_ 122 BattTrac_U_Actl 1023 "Fault" 1022 "Unknown";
VAL_ 122 BattTrac_I_Actl 32767 "Fault" 32766 "Unknown";
VAL_ 90 TrnGsmNtmState_D_Actl 3 "Faulty" 2 "Neutral_Tow_Mode" 1 "Car_Wash_Mode" 0 "None";
VAL_ 90 DrQltyDrv_D_StatGsm 7 "Faulty" 6 "NoDataExists" 5 "NotUsed2" 4 "NotUsed1" 3 "ClosedDegraded" 2 "OpenDegraded" 1 "ClosedOkay" 0 "OpenOkay";
VAL_ 90 TrnBtsiOvrrd_B_Stat 1 "Override" 0 "Null";
VAL_ 90 GsmGearMsgTxt_D_Rq 3 "Message3" 2 "Message2" 1 "Message1" 0 "NoMessage";
VAL_ 90 TrnRng_D_RqGsm 15 "Fault" 14 "UnknownPosition" 13 "Undefined_2" 12 "Undefined_1" 11 "_6" 10 "_5" 9 "_4" 8 "_3" 7 "_2" 6 "_1" 5 "Low" 4 "Sport_DriveSport" 3 "Drive" 2 "Neutral" 1 "Reverse" 0 "Park";
VAL_ 90 PrkBrkActv_D_RqGsmGear 3 "NotUsed" 2 "RequestParkBrakeEngage" 1 "NoRequest" 0 "Null";
VAL_ 90 TrnValidGearRq_D_Stat 3 "Valid_Request" 2 "Valid_Degraded_Request" 1 "Invalid_Request" 0 "No_Request";
VAL_ 90 TrnGearButtn_U_Actl 255 "Fault";
VAL_ 90 TrnGearButtn_B_ActlR2 1 "Yes" 0 "No";
VAL_ 90 TrnGearButtn_B_ActlR1 1 "Yes" 0 "No";
VAL_ 90 TrnGearButtn_B_ActlR0 1 "Yes" 0 "No";
VAL_ 90 TrnGearButtn_B_ActlP2 1 "Yes" 0 "No";
VAL_ 90 TrnGearButtn_B_ActlP1 1 "Yes" 0 "No";
VAL_ 90 TrnGearButtn_B_ActlP0 1 "Yes" 0 "No";
VAL_ 90 TrnGearButtn_B_ActlN2 1 "Yes" 0 "No";
VAL_ 90 TrnGearButtn_B_ActlN1 1 "Yes" 0 "No";
VAL_ 90 TrnGearButtn_B_ActlN0 1 "Yes" 0 "No";
VAL_ 90 TrnGearButtn_B_ActlM2 1 "Yes" 0 "No";
VAL_ 90 TrnGearButtn_B_ActlM1 1 "Yes" 0 "No";
VAL_ 90 TrnGearButtn_B_ActlM0 1 "Yes" 0 "No";
VAL_ 90 TrnGearButtn_B_ActlD2 1 "Yes" 0 "No";
VAL_ 90 TrnGearButtn_B_ActlD1 1 "Yes" 0 "No";
VAL_ 90 TrnGearButtn_B_ActlD0 1 "Yes" 0 "No";
VAL_ 90 TrnGear_D_RqDrv 31 "Fault" 30 "NotUsed_25" 29 "NotUsed_24" 28 "NotUsed_23" 27 "NotUsed_22" 26 "Return_to_Park" 25 "NotUsed_20" 24 "NotUsed_19" 23 "NotUsed_18" 22 "NotUsed_17" 21 "Return_To_Park" 20 "NotUsed_15" 19 "NotUsed_14" 18 "NotUsed_13" 17 "NotUsed_12" 16 "Manual" 15 "Not_Used11" 14 "Not_Used10" 13 "NotUsed_9" 12 "NotUsed_8" 11 "NotUsed_7" 10 "NotUsed_6" 9 "NotUsed_5" 8 "Drive" 7 "NotUsed_4" 6 "NotUsed_3" 5 "NotUsed_2" 4 "Neutral" 3 "NotUsed_1" 2 "Reverse" 1 "Park" 0 "No_Gear";
VAL_ 90 BrkSwtchPos_B_ActlGsm 1 "Yes" 0 "No";
VAL_ 1091 ParkLampTrlrOut_B_Stat 1 "Out" 0 "Null";
VAL_ 1091 TrlrLampCtl_D_Stat 3 "NotUsed" 2 "TrlrLampCnnctDrvFailure" 1 "TrlrLampNotCnnctDrvFailure" 0 "Null";
VAL_ 1091 TrlrBattChrg_D_Stat 3 "Reverse" 2 "Normal" 1 "Low" 0 "Null";
VAL_ 1091 StopLampTrlrOut_B_Stat 1 "Out" 0 "Null";
VAL_ 1091 TurnLampTrlrRr_B_Stat 1 "Out" 0 "Null";
VAL_ 1091 TurnLampTrlrRl_B_Stat 1 "Out" 0 "Null";
VAL_ 1091 TrlrLampCnnct_B_Actl 1 "Yes" 0 "No";
VAL_ 138 SteWhlRelCalib_An_Sns 32767 "Fault" 32766 "NoDataExists";
VAL_ 131 AccButtnGapDecPress 1 "Button_Pressed" 0 "Button_Not_Pressed";
VAL_ 131 HeadLghtHiCtrl_D_RqAhb 7 "NotUsed2" 6 "NotUsed1" 5 "Auto_HiBeam" 4 "Auto_LoBeam" 3 "Flash" 2 "Man_HiBeam" 1 "Man_LoBeam" 0 "Null";
VAL_ 131 AhbStat_B_Dsply 1 "On" 0 "Off";
VAL_ 131 WiprFrontSwtch_D_Stat 15 "NotUsed6" 14 "NotUsed5" 13 "NotUsed4" 12 "NotUsed3" 11 "NotUsed2" 10 "NotUsed1" 9 "PositionNotDetermined" 8 "High" 7 "Low" 6 "Position6" 5 "Position5" 4 "Position4" 3 "Position3" 2 "Position2" 1 "Position1" 0 "Off";
VAL_ 131 HeadLghtHiOn_B_StatAhb 1 "On" 0 "Off";
VAL_ 131 HeadLghtHiFlash_D_Actl 3 "NotUsed" 2 "High" 1 "Flash_to_Pass" 0 "Null";
VAL_ 131 TjaButtnOnOffPress 1 "Pressed" 0 "Not_Pressed";
VAL_ 131 AccButtnGapTogglePress 1 "Pressed" 0 "Not_Pressed";
VAL_ 131 HeadLghtHiFlash_D_Stat 3 "NotUsed" 2 "High" 1 "Flash_to_Pass" 0 "Null";
VAL_ 131 WiprFront_D_Stat 15 "NO_DATA_EXISTS" 14 "STALLED" 13 "RESERVED" 12 "AUTO_ADJUST" 11 "COURTESYWIPE" 10 "AUTO_HIGH" 9 "AUTO_LOW" 8 "WASH" 7 "MIST_FLICK" 6 "MAN_HIGH" 5 "MAN_LOW" 4 "MAN_INT_ON" 3 "MAN_INT_OFF" 2 "OFF_MOVING" 1 "AUTO_OFF" 0 "OFF";
VAL_ 131 TurnLghtSwtch_D_Stat 3 "Unused_Treat_As_Off" 2 "Right" 1 "Left" 0 "Off";
VAL_ 131 LghtAmb_D_Sns 7 "No_Data_Exists" 6 "Unused2" 5 "Unused1" 4 "Tunnel_Off" 3 "Tunnel_On" 2 "Twilight" 1 "Light" 0 "Dark";
VAL_ 131 AccButtnGapIncPress 1 "Button_Pressed" 0 "Button_Not_Pressed";
VAL_ 131 AslButtnOnOffPress 1 "Button_Pressed" 0 "Button_Not_Pressed";
VAL_ 131 AslButtnOnOffCnclPress 1 "Button_Pressed" 0 "Button_Not_Pressed";
VAL_ 131 CcButtnOnPress 1 "Button_Pressed" 0 "Button_Not_Pressed";
VAL_ 131 CcButtnOnOffPress 1 "Button_Pressed" 0 "Button_Not_Pressed";
VAL_ 131 CcButtnOnOffCnclPress 1 "Button_Pressed" 0 "Button_Not_Pressed";
VAL_ 131 CcButtnOffPress 1 "Button_Pressed" 0 "Button_Not_Pressed";
VAL_ 131 CcAsllButtnResPress 1 "Button_Pressed" 0 "Button_Not_Pressed";
VAL_ 131 CcAslButtnSetPress 1 "Button_Pressed" 0 "Button_Not_Pressed";
VAL_ 131 CcAslButtnSetIncPress 1 "Button_Pressed" 0 "Button_Not_Pressed";
VAL_ 131 CcAslButtnSetDecPress 1 "Button_Pressed" 0 "Button_Not_Pressed";
VAL_ 131 CcAslButtnResIncPress 1 "Button_Pressed" 0 "Button_Not_Pressed";
VAL_ 131 CcAslButtnResDecPress 1 "Button_Pressed" 0 "Button_Not_Pressed";
VAL_ 131 CcAslButtnOnPress 1 "Button_Pressed" 0 "Button_Not_Pressed";
VAL_ 131 CcAslButtnOnOffCncl 1 "Button_Pressed" 0 "Button_Not_Pressed";
VAL_ 131 CcAslButtnOffCnclPress 1 "Button_Pressed" 0 "Button_Not_Pressed";
VAL_ 131 CcAslButtnIndxIncPress 1 "Button_Pressed" 0 "Button_Not_Pressed";
VAL_ 131 CcAslButtnIndxDecPress 1 "Button_Pressed" 0 "Button_Not_Pressed";
VAL_ 131 CcAslButtnDeny_B_Actl 1 "Yes" 0 "No";
VAL_ 131 CcAslButtnCnclResPress 1 "Button_Pressed" 0 "Button_Not_Pressed";
VAL_ 131 CcAslButtnCnclPress 1 "Button_Pressed" 0 "Button_Not_Pressed";
VAL_ 131 LaSwtchPos_D_Stat 3 "Fault" 2 "Unused" 1 "Pressed" 0 "Open";
VAL_ 787 DrTgateChime2_D_Rq 7 "NotUsed3" 6 "NotUsed2" 5 "NotUsed1" 4 "Long_Repeated" 3 "Fast" 2 "Short" 1 "Long" 0 "Off";
VAL_ 787 DrTGate_D_Rq 3 "NotUsed" 2 "Closing" 1 "Opening" 0 "Not_Moving";
VAL_ 787 PwLftgtIntSw_B_Stat 1 "Pressed" 0 "Null";
VAL_ 787 Power_Liftgate_Mode_Stt 2 "Unused" 3 "Not_Supported" 1 "Enabled" 0 "Disabled";
VAL_ 953 BattRgenLoDChrg_D_Rq 3 "DoNotCare" 2 "Retain" 1 "Closed" 0 "Open";
VAL_ 953 BattRgenLoChrg_D_Rq 3 "DoNotCare" 2 "Retain" 1 "Closed" 0 "Open";
VAL_ 953 ChrgCordLck_B_Stat 1 "Unlock" 0 "Null";
VAL_ 953 WakeAlarm3_D_Stat 3 "PublisherReset" 2 "Wake" 1 "AlarmRunning" 0 "AlarmOff";
VAL_ 953 WakeAlarm2_D_Stat 3 "PublisherReset" 2 "Wake" 1 "AlarmRunning" 0 "AlarmOff";
VAL_ 953 WakeAlarm1_D_Stat 3 "PublisherReset" 2 "Wake" 1 "AlarmRunning" 0 "AlarmOff";
VAL_ 953 WakeAlarm0_D_Stat 3 "PublisherReset" 2 "Wake" 1 "AlarmRunning" 0 "AlarmOff";
VAL_ 1093 TrlBrkInitOut_D_Stat 3 "Heavy" 2 "Medium" 1 "Light" 0 "Null";
VAL_ 1093 TrlrBrkMde_D_Actl 1 "Electric_Over_Hydraulic" 0 "Electric";
VAL_ 1093 TrlrBrkDsply_B_Rq 1 "Yes" 0 "No";
VAL_ 1093 TrlrBrkDcnnt_B_Actl 1 "Yes" 0 "No";
VAL_ 1093 TrlrBrkActCnnct_B_Actl 1 "Yes" 0 "No";
VAL_ 1093 StopLamp_B_RqTrlrBrk 1 "Yes" 0 "No";
VAL_ 1093 TrlrBrkCtl_B_Falt 1 "Yes" 0 "No";
VAL_ 1093 TrlrBrkActCirct_B_Falt 1 "Yes" 0 "No";
VAL_ 792 ElTrip_L_Dsply 65535 "Fault" 65534 "No_Data_Exists";
VAL_ 792 ElLongTerm_L_Dsply 16777215 "Fault" 16777214 "No_Data_Exists";
VAL_ 968 SlMde_D_Rq 3 "IsaNotConfigured" 2 "Manual_Mode" 1 "Auto_Mode" 0 "Null";
VAL_ 968 IsaOffst_D_Rq 15 "Faulty" 14 "Null" 13 "Thirteen" 12 "Twelve" 11 "Eleven" 10 "Ten" 9 "Nine" 8 "Eight" 7 "Seven" 6 "Six" 5 "Five" 4 "Four" 3 "Three" 2 "Two" 1 "One" 0 "Zero";
VAL_ 819 Memory_3_SwPsngr_Stat 1 "Pressed" 0 "Null";
VAL_ 819 Memory_2_SwPsngr_Stat 1 "Pressed" 0 "Null";
VAL_ 819 Memory_1_SwPsngr_Stat 1 "Pressed" 0 "Null";
VAL_ 819 BLISLEDStatPassSide 3 "Fault" 2 "Unused" 1 "On" 0 "Off";
VAL_ 819 WndwPsngrSide_D_Stat 3 "BothWindow_Operating" 2 "RearWindow_Operating" 1 "FrontWindow_Operating" 0 "NoWindows_Operating";
VAL_ 819 Pasngr_Lock_Sw_Stat 3 "Invalid" 2 "Unlock" 1 "Lock" 0 "Null";
VAL_ 819 ChildLckFdbckRp_B_Stat 1 "Locked" 0 "Unlock";
VAL_ 818 BLISLEDStatDriverSide 3 "Fault" 2 "Unused" 1 "On" 0 "Off";
VAL_ 818 WndwDrvSide_D_Stat 3 "BothWindow_Operating" 2 "RearWindow_Operating" 1 "FrontWindow_Operating" 0 "NoWindows_Operating";
VAL_ 818 KeyCylSwDrvDr_D_Stat 3 "NotUsed" 2 "Unlock" 1 "Lock" 0 "Null";
VAL_ 818 Driver_Lock_Sw_Stat 3 "Invalid" 2 "Unlock" 1 "Lock" 0 "Null";
VAL_ 818 ChildLckPw_D_Rq 1 "Active" 0 "Null";
VAL_ 818 ChildLckFdbckRd_B_Stat 1 "Locked" 0 "Unlock";
VAL_ 818 RvrseMirrorChime_B_Rq 1 "Yes" 0 "No";
VAL_ 806 SnowPlowMde_B_Enbl 1 "Enable" 0 "Disable";
VAL_ 806 StopStrtDrvMde_B_RqBtn 1 "Pressed" 0 "Not_Pressed";
VAL_ 806 ClimtHeat_D_Rq 7 "NotUsed4" 6 "NotUsed3" 5 "NotUsed2" 4 "PtcHtrTestMde" 3 "Defrost_Defog" 2 "FastTempPullDownHeatingReq" 1 "OpportunisticHeatingReq" 0 "NoHeatingRequest";
VAL_ 806 ClimtCool_D_Rq 7 "NotUsed4" 6 "NotUsed3" 5 "NotUsed2" 4 "ElACTestMde" 3 "Defrost_Defog" 2 "FastTempPullDownCoolReq" 1 "OpportunisticCoolingReq" 0 "NoCoolingRequest";
VAL_ 806 HvacEvap_Te_Actl 1023 "Fault";
VAL_ 806 HvacAirCond_B_Rq 1 "Yes" 0 "No";
VAL_ 806 ClimtPw_B_Rq 1 "Yes" 0 "No";
VAL_ 765 Mc_VehTimeFrmtUsrSel_St 2 "24h_mode" 1 "12h_mode" 0 "Invalid";
VAL_ 765 Running_Board_Cmd 3 "Unused" 2 "Manually_Deployed" 1 "All_Enabled" 0 "All_Disabled";
VAL_ 765 EngExhMdeQuiet_D2_Rq 7 "NotUsed_3" 6 "NotUsed_2" 5 "NotUsed_1" 4 "Track" 3 "Sport" 2 "Normal" 1 "Stealth" 0 "Null";
VAL_ 765 EdmSailMde_B_RqDrv 1 "On" 0 "Off";
VAL_ 765 DrvInputRequired_B_Rq 1 "Yes" 0 "No";
VAL_ 765 AwdRnge_D_ActlIpc 7 "Unknown" 6 "High_Range_2wd" 5 "High_Range_Auto" 4 "High_Range_Locked" 3 "Neutral" 2 "Low_Range_2wd" 1 "Low_Range_Auto" 0 "Low_Range_Locked";
VAL_ 765 BalrSwtch_D_Stat 3 "NotUsed" 2 "Pressed" 1 "NotPressed" 0 "Null";
VAL_ 765 BalrMde_D_Rq 3 "High" 2 "Medium" 1 "Low" 0 "Null";
VAL_ 765 WaitToStartLamp_D_Falt 3 "NotUsed" 2 "Wait_to_start_lamp_failed" 1 "Diagnosis_not_ready" 0 "Wait_to_start_lamp_OK";
VAL_ 765 EsaOn_B_Rq 1 "On" 0 "Off";
VAL_ 765 BttOn_B_Rq 1 "On" 0 "Off";
VAL_ 765 Btt_L_Actl 127 "Faulty" 126 "NoDataExists";
VAL_ 765 SelDrvMdeTxtReset_B_Rq 1 "Yes" 0 "No";
VAL_ 765 SelDrvMdeDsply_B_Avail 1 "Available" 0 "NotAvailable";
VAL_ 765 Mc_VehUntTrpCoUsrSel_St 0 "TripComputer_metric" 1 "TripComputer_imperial";
VAL_ 765 Mc_VehUnitTempUsrSel_St 0 "Temperature_deg_c" 1 "Temperature_deg_f";
VAL_ 765 Mc_VehLangUsrSel_St 30 "Slovak" 29 "Arabic" 28 "Cantonese" 27 "Mandarin_Chinese" 26 "Korean" 25 "Japanese_Kanji" 24 "Japanese_Katakana" 23 "Braz_Portuguese" 22 "EU_Portuguese" 21 "Finish" 20 "Norwegian" 19 "Danish" 18 "Swedish" 17 "Hungarian" 16 "Greek" 15 "Czech" 14 "Polish" 13 "Flemish" 12 "Dutch" 11 "Russian" 10 "Turkish" 9 "Mex_Spanish" 8 "EU_Spanish" 7 "Cana_French" 6 "EU_French" 5 "Italian" 4 "German" 3 "NA_English" 2 "UK_English" 1 "Unknown" 0 "Invalid";
VAL_ 934 CtaAlrtLeft2_D_Stat 7 "NotUsed3" 6 "NotUsed2" 5 "NotUsed1" 4 "AlertZone4" 3 "AlertZone3" 2 "AlertZone2" 1 "AlertZone1" 0 "Off";
VAL_ 934 CtaBrkLeftMsgTxt_B_Rq 1 "Enable" 0 "Disable";
VAL_ 934 CtaLeftBrkDecel_B_Rq 1 "Enable" 0 "Disable";
VAL_ 934 CtaLeftBrkEnbl_B_Rq 1 "Enable" 0 "Disable";
VAL_ 934 BttLeft_D_Stat 7 "NotUsed" 6 "Disabled" 5 "Off" 4 "OffTemp" 3 "NotConnected" 2 "Pending" 1 "Connected" 0 "NotDetermined";
VAL_ 934 BttLeft_D_RqDrv 3 "NotUsed" 2 "Request" 1 "NoRequest" 0 "Null";
VAL_ 934 CtaSnsLeft_D_Stat 3 "Invalid" 2 "System_Failure" 1 "Blocked" 0 "Clear";
VAL_ 934 SodDetctLeft_D_Stat 4 "Sensor_Blocked" 3 "Sensor_Fault" 2 "Flash_On" 1 "Alert_On" 0 "AlertOff_FlashOff_SensrClr";
VAL_ 934 CtaLeft_D_Stat 7 "NotUsed_3" 6 "NotUsed_2" 5 "NotUsed_1" 4 "Invalid" 3 "Disabled" 2 "On" 1 "Trailer_Tow_Off" 0 "Off";
VAL_ 934 CtaAlrtLeft_D_Stat 1 "On" 0 "Off";
VAL_ 934 SodLeft_D_Stat 7 "NotUsed_3" 6 "NotUsed_2" 5 "NotUsed_1" 4 "Invalid" 3 "Disabled" 2 "On" 1 "Trailer_Tow_Off" 0 "Off";
VAL_ 934 SodSnsLeft_D_Stat 3 "Second_Warning_Audio" 2 "System_Failure" 1 "Blocked" 0 "Clear";
VAL_ 934 SodAlrtLeft_D_Stat 3 "Bulb_Proveout" 2 "Flash" 1 "On" 0 "Off";
VAL_ 1072 LscmbbStat_B_Actl 1 "On" 0 "Off";
VAL_ 1072 HaDsplyCpblty_B_Stat 1 "Available" 0 "NotAvailable";
VAL_ 1072 AccDeny_B_RqIpc 1 "Yes" 0 "No";
VAL_ 1072 DrvSlipCtlMde_D_Rq 3 "App_Specific_Off_Mode_3" 2 "App_Specific_Off_Mode_2" 1 "App_Specific_Off_Mode_1" 0 "Default_Mode";
VAL_ 1072 EngIdlShutDown_B_RqDrv 1 "Inhibit" 0 "No_Inibit";
VAL_ 1072 HsaMde_D_Rq 3 "Undefined" 2 "Manual" 1 "Automatic" 0 "Off";
VAL_ 1072 NtrlTowMdeEnbl_B_RqDrv 1 "Yes" 0 "No";
VAL_ 1072 BulbChkActv_B_Stat 1 "Active" 0 "Inactive";
VAL_ 1072 ParkDetect_Stat 1 "Park" 0 "Not_Park";
VAL_ 1072 ReducedGuard_D_Rq 3 "NotUsed" 2 "On" 1 "Off" 0 "Null";
VAL_ 1072 TrlrBrkMde_D_Rq 1 "ElectricOverHydraulic" 0 "Electric";
VAL_ 1072 TRLR_SWAY_CONFIG_CMD 1 "On" 0 "Off";
VAL_ 1072 TRAILER_BRAKE_CONFIG 1 "Yes" 0 "No";
VAL_ 1072 Power_Liftgate_Mode_Cmd 1 "Enable" 0 "Disable";
VAL_ 1072 AccEnbl_B_RqDrv 1 "Adaptive_Cruise" 0 "Normal_Cruise";
VAL_ 1072 OdometerMasterValue 16777215 "Invalid";
VAL_ 1072 EngOilLife_B_RqReset 1 "Yes" 0 "No";
VAL_ 1072 ePRNDL_MODE 1 "On" 0 "Off";
VAL_ 1072 DrvSlipCtlMde_B_Rq2 1 "Pressed" 0 "Not_Pressed";
VAL_ 1072 MetricActv_B_Actl 1 "Active" 0 "Inactive";
VAL_ 1072 KeyTypeChngMykey_D_Rq 3 "Search_PE_BackupSlot" 2 "Clear_All_MyKeys" 1 "Request_New_MyKey" 0 "None";
VAL_ 1072 ManRgen_D_Rq 3 "NotUsed2" 2 "NotUsed1" 1 "CustInitManExhFilterClean" 0 "No_Customer_Request";
VAL_ 909 IgnPsswrdDsply_B_Rq 1 "Active" 0 "Inactive";
VAL_ 909 ElPwPoint_D_Rq 3 "On" 2 "Off2" 1 "Off1" 0 "Null";
VAL_ 909 PoliceIdlMde_D_Stat 15 "NotUsed_7" 14 "NotUsed_6" 13 "NotUsed_5" 12 "NotUsed_4" 11 "NotUsed_3" 10 "NotUsed_2" 9 "PepsActive" 8 "Decommissioned" 7 "ActiveFault" 6 "ArmFault" 5 "PrearmedFault" 4 "OffFault" 3 "Active" 2 "Arm" 1 "Prearmed" 0 "Off";
VAL_ 909 DrLatchMsgTxt_D_Rq 7 "Message7" 6 "Message6" 5 "Message5" 4 "Message4" 3 "Message3" 2 "Message2" 1 "Message1" 0 "NoMessage";
VAL_ 909 SecurityMsgTxt_D_Rq 3 "Message3" 2 "Message2" 1 "Message1" 0 "NoMessage";
VAL_ 909 PrmtrAlrmEvnt_D_Stat 15 "Diag_Tamper" 14 "Trailer" 13 "Shock_Sensor" 12 "Post_Crash" 11 "Panic" 10 "Intrusion" 9 "Inclination" 8 "Ign_Tamper" 7 "LG_Door" 6 "Decklid" 5 "Hood" 4 "PR_Door" 3 "PF_Door" 2 "DR_Door" 1 "DF_Door" 0 "Null";
VAL_ 909 HeadLghtHiPrmsn_D_Stat 3 "CancelAndSuppress" 2 "Cancel" 1 "Hold" 0 "AllowChange";
VAL_ 909 SteWhlLckMsgTxt_D_Rq 3 "NotUsed" 2 "Message_2" 1 "Message_1" 0 "No_Message";
VAL_ 909 immoMsgTxt_D_Rq 15 "Immo_Msg_15" 14 "Immo_Msg_14" 13 "Immo_Msg_13" 12 "Immo_Msg_12" 11 "Immo_Msg_11" 10 "Immo_Msg_10" 9 "Immo_Msg_9" 8 "Immo_Msg_8" 7 "Immo_Msg_7" 6 "Immo_Msg_6" 5 "Immo_Msg_5" 4 "Immo_Msg_4" 3 "Immo_Msg_3" 2 "Immo_Msg_2" 1 "Immo_Msg_1" 0 "Immo_Msg_0_Null";
VAL_ 909 PrsnlDevcChrgEnbl_B_Rq 1 "Active" 0 "Inactive";
VAL_ 909 TracKeyMde_D_Stat 3 "NotUsed" 2 "NotActive" 1 "Active" 0 "ModeNotDetermined";
VAL_ 909 PEBackupSlot_Stats 3 "No_Valid_FOB_In_Slot" 2 "MyKey_FOB_In_Slot" 1 "Standard_FOB_In_Slot" 0 "Null";
VAL_ 909 KeyMykeyTot_No_Cnt 13 "Thirteen" 12 "Twelve" 11 "Eleven" 10 "Ten" 9 "Nine" 8 "Eight" 7 "Seven" 6 "Six" 5 "Five" 4 "Four" 3 "Three" 2 "Two" 1 "One" 0 "Zero" 15 "Invalid" 14 "Unlimited";
VAL_ 909 KeyAdmnTot_No_Cnt 13 "Thirteen" 12 "Twelve" 11 "Eleven" 10 "Ten" 9 "Nine" 8 "Eight" 7 "Seven" 6 "Six" 5 "Five" 4 "Four" 3 "Three" 2 "Two" 1 "One" 0 "Zero" 15 "Invalid" 14 "Unlimited";
VAL_ 963 Illuminated_Entry_Stat 3 "Invalid" 2 "Unknown" 1 "On" 0 "Off";
VAL_ 963 Dr_Courtesy_Light_Stat 3 "Invalid" 2 "Unknown" 1 "On" 0 "Off";
VAL_ 963 Courtesy_Delay_Status 3 "Invalid" 2 "Unknown" 1 "On" 0 "Off";
VAL_ 963 ImpactEvntFdbck_D_Stat 3 "NotUsed" 2 "EventComplete" 1 "EventInProgress" 0 "Normal";
VAL_ 963 WrlssAcsyChrgInhbt_B_Rq 1 "Yes" 0 "No";
VAL_ 963 PudLampPsngr_D_Rq 3 "Ramp_Down" 2 "Ramp_Up" 1 "On" 0 "Off";
VAL_ 963 HeadLampLoOut_B_Stat 1 "Out" 0 "Null";
VAL_ 963 HeadLghtHiFdbck_D_Stat 3 "NotUsed" 2 "Cancel" 1 "Hold" 0 "Allow_Change";
VAL_ 963 PudLampDrv_D_Rq 3 "Ramp_Down" 2 "Ramp_Up" 1 "On" 0 "Off";
VAL_ 963 TrnNotInPrkChime_B_Rq 1 "On" 0 "Off";
VAL_ 963 PrkLightChime_B_Rq 1 "On" 0 "Off";
VAL_ 963 KeyInIgnWarn_B_Cmd 1 "On" 0 "Off";
VAL_ 963 HomeSafeLtChime_B_Rq 1 "On" 0 "Off";
VAL_ 963 StopLghtOn_B_Stat 1 "On" 0 "Off";
VAL_ 963 RvrseLghtOn_B_Stat 1 "On" 0 "Off";
VAL_ 963 PrkLght_D_Stat 3 "Park_Both" 2 "Park_Right" 1 "Park_Left" 0 "Off";
VAL_ 963 HeadLghtSwtch_D_Stat 3 "Autolamp" 2 "Headlamp" 1 "Parklamp" 0 "Off";
VAL_ 963 HeadLampLoFrOn_B_Stat 1 "Low" 0 "Not_Low";
VAL_ 963 HeadLampLoFlOn_B_Stat 1 "Low" 0 "Not_Low";
VAL_ 963 HeadLampLoActv_B_Stat 1 "On" 0 "Off";
VAL_ 963 Headlamp_On_Wrning_Cmd 1 "On" 0 "Off";
VAL_ 963 Park_Brake_Chime_Rqst 1 "On" 0 "Off";
VAL_ 963 HeadLghtHiOn_B_Stat 1 "On" 0 "Off";
VAL_ 963 BrkWarnInd_B_Rq 1 "On" 0 "Off";
VAL_ 963 Brk_Fluid_Lvl_Low 3 "Invalid" 2 "Unknown" 1 "Low" 0 "OK";
VAL_ 963 ReducedGuard_D_Stat 3 "NotUsed" 2 "Alarm_On" 1 "Alarm_Off_Previously_On" 0 "Alarm_Off";
VAL_ 963 Perimeter_Alarm_Status 3 "Activated" 2 "Armed" 1 "Prearmed" 0 "Disarmed";
VAL_ 963 Courtesy_BSave_Stat 3 "Invalid" 2 "Unknown" 1 "No_Effect" 0 "Off";
VAL_ 963 DrTgateLck_D_Stat 3 "NotUsed" 2 "Unlock" 1 "Lock" 0 "Null";
VAL_ 963 WndwGlbl_D_Cmd 7 "NotUsed3" 6 "NotUsed2" 5 "NotUsed1" 4 "GLEARN" 3 "GCLOSE" 2 "GOPEN" 1 "GSTOP" 0 "Null";
VAL_ 963 PudLamp_D_Rq 3 "RAMP_DOWN" 2 "RAMP_UP" 1 "ON" 0 "OFF";
VAL_ 963 DayRnngLampOn_B_Stat 1 "On" 0 "Off";
VAL_ 963 PerimeterAlarmChimeRq 1 "On" 0 "Off";
VAL_ 145 VehYawWActl_D_Qf 3 "OK" 2 "Not_Within_Specifications" 1 "No_Data_Exists" 0 "Faulty";
VAL_ 145 VehRolWActl_D_Qf 3 "OK" 2 "Not_Within_Specifications" 1 "No_Data_Exists" 0 "Faulty";
VAL_ 145 VehYaw_W_Actl 65535 "Faulty" 65534 "NoDataExists";
VAL_ 145 VehRol_W_Actl 65535 "Faulty" 65534 "NoDataExists";
VAL_ 76 FirstRowBuckleMid 3 "Unknown" 2 "Unbelted" 1 "Belted" 0 "Faulty";
VAL_ 76 SecondRowBucklePsngr 3 "Unknown" 2 "Unbelted" 1 "Belted" 0 "Faulty";
VAL_ 76 SecondRowBuckleMid 3 "Unknown" 2 "Unbelted" 1 "Belted" 0 "Faulty";
VAL_ 76 SecondRowBuckleDriver 3 "Unknown" 2 "Unbelted" 1 "Belted" 0 "Faulty";
VAL_ 76 FirstRowBuckleDriver 3 "Unknown" 2 "Unbelted" 1 "Belted" 0 "Faulty";
VAL_ 76 RILReq 3 "Not_Used" 2 "Plant_Mode" 1 "On" 0 "Off";
VAL_ 76 FirstRowBucklePsngr 3 "Unknown" 2 "Unbelted" 1 "Belted" 0 "Faulty";
VAL_ 76 RstrnImpactEvntStatus 7 "Invalid" 6 "Not_Used_4" 5 "Threshold_2_Exceeded" 4 "Not_Used_3" 3 "Threshold_1_Exceeded" 2 "Not_Used_2" 1 "Not_Used_1" 0 "Normal";
VAL_ 76 PsngrFrntDetct_D_Actl 3 "Unknown" 2 "Empty" 0 "Faulty" 1 "Occupied";
VAL_ 76 EDRTriggerEvntSync 1 "Threshold_Exceeded" 0 "Normal";
VAL_ 76 PassRstrnInd_Req 3 "ABOnNotIllum_OffNotIllum" 2 "AirbagOnNot_Illum_OffIllum" 1 "AirbagOn_Illum_OffNotIllum" 0 "AirbagOn_Illum_Off_Illum";
VAL_ 65 immoControlCmd_T1 0 "IDLE" 1 "MOTIVE_START_RQST" 2 "NONMOTIVE_START_RQST" 3 "RQST_TARGET1_IDBLOCK1" 4 "RQST_TARGET1_IDBLOCK2" 5 "Unused" 6 "ECHO_TARGET1_IDBLOCK2" 7 "SHUTDOWN";
VAL_ 1076 HILL_DESC_SW 1 "On" 0 "Off";
VAL_ 1076 AutoRgen_D_Rq 3 "NotUsed" 2 "AutExhFilterCleanOFF" 1 "AutExhFilterCleanON" 0 "No_Mode_Selected";
VAL_ 1076 W2S_LAMP_OK 1 "Yes" 0 "No";
VAL_ 1076 OdoTripRx_B_Actl 1 "Yes" 0 "No";
VAL_ 1076 DrvSlipCtlMde_B_RqMyKey 1 "On" 0 "Off";
VAL_ 1076 FuelLvlWarn_D_Actl 3 "NotUsed" 2 "VeryLow" 1 "Low" 0 "OK";
VAL_ 1076 FuelSecndActv_B_Actl 1 "Yes" 0 "No";
VAL_ 1076 FUEL_SENSOR_NUM 1 "Dual_Sensors" 0 "Single_Sensor";
VAL_ 862 AutoStpHvacDelta_I_Est 255 "Fault";
VAL_ 862 HvacBlwrFront_D_Stat 31 "Not_Used" 20 "Full_On" 19 "95_Percent" 18 "90_Percent" 17 "85_Percent" 16 "80_Percent" 15 "75_Percent" 14 "70_Percent" 13 "65_Percent" 12 "60_Percent" 11 "55_Percent" 10 "50_Percent" 9 "45_Percent" 8 "40_Percent" 7 "35_Percent" 6 "30_Percent" 5 "25_Percent" 4 "20_Percent" 3 "15_Percent" 2 "10_Percent" 1 "5_Percent" 0 "Off";
VAL_ 862 CabnAmb_Te_Actl 255 "Fault";
VAL_ 862 ClimtThrmlLoad_No_Actl 255 "Fault";
VAL_ 931 PtWakeReas_D_Stat 15 "NotUsed_9" 14 "NotUsed_8" 13 "NotUsed_7" 12 "NotUsed_6" 11 "NotUsed_5" 10 "NotUsed_4" 9 "NotUsed_3" 8 "NotUsed_2" 7 "NotUsed_1" 6 "ElapsedTime" 5 "ThirdPartyWakeup" 4 "DoorAjar" 3 "EarlyWake" 2 "NonMotiveStart" 1 "MotiveStart" 0 "Null";
VAL_ 931 VehOnSrc_D_Stat 15 "NotUsed_11" 14 "NotUsed_10" 13 "NotUsed_9" 12 "NotUsed_8" 11 "NotUsed_7" 10 "NotUsed_6" 9 "NotUsed_5" 8 "NotUsed_4" 7 "NotUsed_3" 6 "NotUsed_2" 5 "NotUsed_1" 4 "OverTheAir" 3 "RemoteParkAssist" 2 "RemoteStart" 1 "Manual" 0 "Off";
VAL_ 931 EngStrtActv_B_Stat 1 "Active" 0 "Inactive";
VAL_ 931 EngStrt_B_Rq 1 "Request" 0 "NoRequest";
VAL_ 931 DrvInCtl_B_Stat 1 "Yes" 0 "No";
VAL_ 931 AdvStrt_D_Stat 15 "NotUsed_15" 14 "NotUsed_14" 13 "NotUsed_13" 12 "NotUsed_12" 11 "NotUsed_11" 10 "NotUsed_10" 9 "NotUsed_9" 8 "NotUsed_8" 7 "NotUsed_7" 6 "NotUsed_6" 5 "NotUsed_5" 4 "NotUsed_4" 3 "NotUsed_3" 2 "NotUsed_2" 1 "NotUsed_1" 0 "NoAction";
VAL_ 931 CrnkInhbt_B_Stat 1 "Inhibit" 0 "NoInhibit";
VAL_ 931 IgnPreOffActv_B_Stat 1 "Active" 0 "Inactive";
VAL_ 578 PtLatchActv_B_RqBcm 1 "On" 0 "Off";
VAL_ 578 immoSecureIdleMode 3 "NotUsed2" 2 "NotUsed1" 1 "Active" 0 "Inactive";
VAL_ 578 ReFuelSwtchStat_D_Actl 3 "NotUsed2" 2 "NotUsed1" 1 "On" 0 "Off";
VAL_ 578 FuelPumpPwr_D_Stat 7 "NotUsed3" 6 "NotUsed2" 5 "NotUsed1" 4 "Power_Off_Default" 3 "Power_Off_Command" 2 "Power_Off_Service" 1 "Power_Off_Impact" 0 "Power_On";
VAL_ 578 BattULo_U_Actl 255 "Fault";
VAL_ 578 PrkLckCtl_B_Enbl 1 "Enable" 0 "Disable";
VAL_ 578 PrkLckCtlMsgTxt_D_Rq 3 "BTSI_DI_3" 2 "BTSI_DI_2" 1 "BTSI_DI_1" 0 "Null_BTSI_DI";
VAL_ 578 BrkTrnShifLck_B_Stat 1 "Shift" 0 "NoShift";
VAL_ 578 PrkLckCtlUnlck_D_Stat 3 "Trans_And_Steer_Unlckd" 2 "Steering_Unlckd" 1 "Transmission_Unlckd" 0 "Null";
VAL_ 578 PrkLckCtlTow_B_Enbl 1 "Enable" 0 "Disable";
VAL_ 578 DriverCrankingReq 1 "Crank_Request" 0 "No_Crank_Request";
VAL_ 578 EngOff_T_Actl 65535 "Invalid";
VAL_ 578 DcacElPw_D_Rq 3 "NotUsed" 2 "AC_HighPower_Requested" 1 "AC_LowPower_Requested" 0 "AC_Power_NotRequested";
VAL_ 578 BattULo_I_Actl 16383 "Fault";
VAL_ 947 ValetMode_D_Mem 1 "On" 0 "Off";
VAL_ 947 DrStatDrvErrCnt_B_Stat 1 "Yes" 0 "No";
VAL_ 947 TurnLghtRight_D_Rq 3 "Seq" 2 "On" 1 "Off" 0 "Null";
VAL_ 947 TurnLghtRightOn_B_Stat 1 "On" 0 "Off";
VAL_ 947 TurnLghtLeftOn_B_Stat 1 "On" 0 "Off";
VAL_ 947 FogLghtRearOn_B_Stat 1 "On" 0 "Off";
VAL_ 947 Backlit_LED_Status 15 "Unused3" 14 "Unused2" 13 "Unused1" 12 "Night_12" 11 "Night_11" 10 "Night_10" 9 "Night_9" 8 "Night_8" 7 "Night_7" 6 "Night_6" 5 "Night_5" 4 "Night_4" 3 "Night_3" 2 "Night_2" 1 "Night_1" 0 "Off";
VAL_ 947 TurnLghtLeft_D_Rq 3 "Seq" 2 "On" 1 "Off" 0 "Null";
VAL_ 947 FogLghtFrontOn_B_Stat 1 "On" 0 "Off";
VAL_ 947 IgnKeyType_D_Actl 15 "Invalid" 14 "Unknown" 3 "Key_Not_Prgrm_Read_Failure" 2 "Key_In_Ign_My_Key" 1 "Key_In_Ign_Standard_Key" 0 "Key_Read_In_Progress";
VAL_ 947 Parklamp_Status 3 "Invalid" 2 "Unknown" 1 "On" 0 "Off";
VAL_ 947 Litval 255 "Invalid" 254 "Unknown" 5 "Day" 4 "Twilight_4" 3 "Twilight_3" 2 "Twilight_2" 1 "Twilight_1" 0 "Night";
VAL_ 947 Key_In_Ignition_Stat 1 "In" 0 "Out";
VAL_ 947 Ignition_Status 0 "Unknown" 1 "Off" 15 "Invalid" 8 "Start" 4 "Run" 2 "Accessory";
VAL_ 947 Dimming_Lvl 255 "Invalid" 254 "Unknown" 18 "Day_6" 17 "Day_5" 16 "Day_4" 15 "Day_3" 14 "Day_2" 13 "Day_1" 12 "Night_12" 11 "Night_11" 10 "Night_10" 9 "Night_9" 8 "Night_8" 7 "Night_7" 6 "Night_6" 5 "Night_5" 4 "Night_4" 3 "Night_3" 2 "Night_2" 1 "Night_1" 0 "Off";
VAL_ 947 Day_Night_Status 3 "NotUsed" 2 "Night" 1 "Day" 0 "Null";
VAL_ 947 Remote_Start_Status 3 "Invalid" 2 "Unknown" 1 "Remote" 0 "Null";
VAL_ 947 DrStatTgate_B_Actl 1 "Ajar" 0 "Closed";
VAL_ 947 DrStatRr_B_Actl 1 "Ajar" 0 "Closed";
VAL_ 947 DrStatRl_B_Actl 1 "Ajar" 0 "Closed";
VAL_ 947 DrStatPsngr_B_Actl 1 "Ajar" 0 "Closed";
VAL_ 947 DrStatInnrTgate_B_Actl 1 "Ajar" 0 "Closed";
VAL_ 947 DrStatHood_B_Actl 1 "Ajar" 0 "Closed";
VAL_ 947 DrStatDrv_B_Actl 1 "Ajar" 0 "Closed";
VAL_ 947 PrkBrkActv_B_Actl 1 "Active" 0 "Inactive";
VAL_ 947 LifeCycMde_D_Actl 3 "Transport" 2 "NotUsed" 1 "Factory" 0 "Normal";
VAL_ 947 Delay_Accy 1 "On" 0 "Off";
VAL_ 947 CrashEvnt_D_Stat 3 "Invalid" 2 "Fuel_Cutoff_Event" 1 "Deploy_Event" 0 "No_Event";
VAL_ 947 FuelPmpInhbt_B_Stat 1 "Inhibit" 0 "No_Inibit";
VAL_ 947 BodySrvcRqd_B_Rq 1 "Yes" 0 "No";
VAL_ 1084 BattULoState_D_Qlty 3 "OK" 2 "Not_Within_Specifications" 1 "Eval_In_Progress" 0 "Fault";
VAL_ 1084 BSFault 1 "Fault" 0 "No_Fault";
VAL_ 1084 BattULo2_Te_Actl 127 "Fault";
VAL_ 1068 EngStrtInhbt_B_RqBatt 1 "Start_Inhibit" 0 "Dont_Care";
VAL_ 1068 BattULoChrg_D_Rq 3 "Low_Battery_Temperature" 2 "Charging_Requested" 1 "Chrg_Requested_HighCurrent" 0 "No_Request";
VAL_ 1068 PwSysULoFalt_D_Stat 15 "Not_Used_6" 14 "LowBatterySOC" 13 "PSS_Shed2_Contin" 12 "Not_Used_4" 11 "Not_Used_3" 10 "Not_Used_2" 9 "BattMonitoringSensorFault" 8 "LowBattVoltDuringPwSrcOn" 7 "LowBatt2_PowerSaveMode" 6 "LowBatt1_Warning" 5 "Overvoltage" 4 "Fault_NoOutput" 3 "Fault_ReducedOutput" 2 "Fault_Nonspecific" 1 "Cluster_Proveout" 0 "No_Fault";
VAL_ 1068 Shed_T_Eng_Off_B 1 "Active" 0 "Inactive";
VAL_ 1068 Shed_Feature_Group_ID 16 "PtcHeater" 14 "HtdMirr" 13 "HvacRearBlwr_Third" 12 "HvacRearBlwr_Second" 11 "HvacRearBlwr_First" 31 "All LSHED1 Features" 10 "Htd_Windscrn" 9 "SpltHtdBcklight_HtdMirr" 8 "HtdBcklight_HtdMirr" 7 "HtdCoolSeat_FrtDriver" 6 "HtdCoolSeat_FrtPass" 5 "HtdCoolSeat_RearPass" 4 "HtdCoolSeat_RearDriver" 3 "SmartTrlrTowBattCharge" 2 "Htd_StrWhl" 1 "Htd_Washer_Fluid" 0 "No_LSHED1_Features" 15 "Engine_Coolant_Fan";
VAL_ 1068 Shed_Drain_Eng_Off_B 1 "Active" 0 "Inactive";
VAL_ 1068 Shed_Level_Req 7 "Unused_2" 6 "Loads_On" 5 "SHED_ENG_OFF" 4 "SOON_ENG_OFF" 3 "SHED2_CONTIN" 2 "SHED2_TRANS" 1 "SHED1" 0 "NO_SHED";
VAL_ 1068 ULoRgenTestMde_B_Rq 1 "Request" 0 "NoRequest";
VAL_ 1068 ChargeMode 7 "Undefined_2" 6 "Undefined_1" 5 "Battery_Identify" 4 "Battery_Refresh" 3 "SlowRegenAllowNoDischarge" 2 "Fast_Regen_Allowed" 1 "Slow_Regen_Allowed" 0 "Conventional_Charging";
VAL_ 1068 IdleSpeedIncrease_El 1 "Yes" 0 "No";
VAL_ 1068 Batt_Lo_SoC_B 1 "Active" 0 "Inactive";
VAL_ 1068 PeriodicElLoad_B_Stat 1 "Active" 0 "Inactive";
VAL_ 1068 Batt_Crit_SoC_B 1 "Active" 0 "Inactive";
VAL_ 146 VehVert2_A_Actl 8191 "Faulty" 8190 "NoDataExists";
VAL_ 146 VehLong2_A_Actl 8191 "Faulty" 8190 "NoDataExists";
VAL_ 146 VehLat2_A_Actl 8191 "Faulty" 8190 "NoDataExists";
VAL_ 146 VehVertAActl_D_Qf 3 "OK" 2 "Not_Within_Specifications" 1 "No_Data_Exists" 0 "Faulty";
VAL_ 146 VehLongAActl_D_Qf 3 "OK" 2 "Not_Within_Specifications" 1 "No_Data_Exists" 0 "Faulty";
VAL_ 146 VehLatAActl_D_Qf 3 "OK" 2 "Not_Within_Specifications" 1 "No_Data_Exists" 0 "Faulty";
VAL_ 997 PersIndexCcm_D_Actl 7 "Unused_3" 6 "Unused_2" 5 "Unused_1" 4 "Vehicle" 3 "PERS_4" 2 "PERS_3" 1 "PERS_2" 0 "PERS_1";
VAL_ 983 CmbbObjRelLong_V_Actl 1023 "Faulty" 1022 "NoDataExists";
VAL_ 983 CmbbObjRelLat_V_Actl 511 "Faulty" 510 "NoDataExists";
VAL_ 983 CmbbObjDistLong_L_Actl 1023 "Faulty" 1022 "NoDataExists";
VAL_ 983 CmbbObjDistLat_L_Actl 511 "Faulty" 510 "NoDataExists";
VAL_ 983 CmbbObjConfdnc_D_Stat 3 "High" 2 "Medium" 1 "Low" 0 "NotDetermined";
VAL_ 983 CmbbObjColl_T_Actl 127 "Faulty" 126 "NoDataExists";
VAL_ 983 CmbbObjClass_D_Stat 15 "NotUsed_9" 14 "NotUsed_8" 13 "NotUsed_7" 12 "NotUsed_6" 11 "NotUsed_5" 10 "NotUsed_4" 9 "NotUsed_3" 8 "NotUsed_2" 7 "NotUsed_1" 6 "Unclassified_Vehicle" 5 "Bicycle" 4 "Pedestrian" 3 "Truck" 2 "Motorcycle" 1 "Vehicle" 0 "Undetermined";
VAL_ 983 EsaEnbl_D2_Rq 3 "NotConfigured" 2 "Enabled" 1 "Pending" 0 "Disabled";
VAL_ 980 AdbBrdr1DistRigh_D_Stat 15 "DistGreater800m" 14 "Dist700mTo800m" 13 "Dist600mTo700m" 12 "Dist500mTo600m" 11 "Dist400mTo500m" 10 "Dist300mTo400m" 9 "Dist200mTo300m" 8 "Dist175mTo200m" 7 "Dist150mTo175m" 6 "Dist125mTo150m" 5 "Dist100mTo125m" 4 "Dist75mTo100m" 3 "Dist50mTo75m" 2 "Dist25mTo50m" 1 "Dist15mTo25m" 0 "Dist0mTo15m";
VAL_ 980 AdbBrdr1DistLeft_D_Stat 15 "DistGreater800m" 14 "Dist700mTo800m" 13 "Dist600mTo700m" 12 "Dist500mTo600m" 11 "Dist400mTo500m" 10 "Dist300mTo400m" 9 "Dist200mTo300m" 8 "Dist175mTo200m" 7 "Dist150mTo175m" 6 "Dist125mTo150m" 5 "Dist100mTo125m" 4 "Dist75mTo100m" 3 "Dist50mTo75m" 2 "Dist25mTo50m" 1 "Dist15mTo25m" 0 "Dist0mTo15m";
VAL_ 980 AdbMde1_D_Rq 3 "MarkerLightFlashing" 2 "MarkerLightConstant" 1 "Spot" 0 "None";
VAL_ 980 AdbIntns1_D_Rq 3 "Maximum" 2 "Medium" 1 "Low" 0 "Off";
VAL_ 980 AdbBrdr1Up_An_Rq 511 "Faulty" 510 "NoDataExists";
VAL_ 980 AdbBrdr1Right_An_Rq 2047 "Faulty" 2046 "NoDataExists";
VAL_ 980 AdbBrdr1Low_An_Rq 511 "Faulty" 510 "NoDataExists";
VAL_ 980 AdbBrdr1Left_An_Rq 2047 "Faulty" 2046 "NoDataExists";
VAL_ 979 HandsOffCnfm_B_Rq 1 "Active" 0 "Inactive";
VAL_ 979 LatCtl_D_Rq 7 "NotUsed4" 6 "NotUsed3" 5 "NotUsed2" 4 "NotUsed1" 3 "InterventionRight" 2 "InterventionLeft" 1 "ContinuousPathFollowing" 0 "NoLateralControl";
VAL_ 979 LatCtlRampType_D_Rq 3 "Immediately" 2 "Fast" 1 "Medium" 0 "Slow";
VAL_ 979 LatCtlPrecision_D_Rq 3 "NotUsed2" 2 "NotUsed1" 1 "Precise" 0 "Comfortable";
VAL_ 976 SuspClkSync_No_Actl 255 "Faulty" 254 "NoDataExists";
VAL_ 976 SrpSigValid_B_Stat 1 "True" 0 "False";
VAL_ 976 SrpHghtRight_L_Actl 511 "Faulty" 510 "NoDataExists";
VAL_ 976 SrpHghtLeft_L_Actl 511 "Faulty" 510 "NoDataExists";
VAL_ 976 SrpEventRight_D_Stat 3 "Faulty" 2 "Bump" 1 "Pothole" 0 "NoEvent";
VAL_ 976 SrpEventLeft_D_Stat 3 "Faulty" 2 "Bump" 1 "Pothole" 0 "NoEvent";
VAL_ 976 SrpDistRight_L_Actl 511 "Faulty" 510 "NoDataExists";
VAL_ 976 SrpDistLeft_L_Actl 511 "Faulty" 510 "NoDataExists";
VAL_ 973 TsrVl2PrmntMsgTxt_D_Rq 3 "NotUsed" 2 "ShowPermanentlyWithSupp" 1 "ShowPermanentlyWithoutSupp" 0 "DoNotShowSignPermanent";
VAL_ 973 TsrVl1PrmntMsgTxt_D_Rq 3 "NotUsed" 2 "ShowPermanentlyWithSupp" 1 "ShowPermanentlyWithoutSupp" 0 "DoNotShowSignPermanent";
VAL_ 973 TsrVl2RstrcMsgTxt2_D_Rq 7 "NotUsed" 6 "Time" 5 "Trailer" 4 "Snow" 3 "RainWet" 2 "NoRecognizableRestrictn" 1 "NoSpeedLimitRestrictn" 0 "Null";
VAL_ 973 TsrVl1RstrcMsgTxt2_D_Rq 7 "NotUsed" 6 "Time" 5 "Trailer" 4 "Snow" 3 "RainWet" 2 "NoRecognizableRestrictn" 1 "NoSpeedLimitRestrictn" 0 "Null";
VAL_ 973 TsrOvtkMsgTxt2_D_Rq 15 "NotUsed5" 14 "NotUsed4" 13 "NotUsed3" 12 "NotUsed2" 11 "NotUsed1" 10 "LimForTrucksCancelled" 9 "LimForTrucksWoQlfdRstrc" 8 "LimForTrucksWithoutRstrc" 7 "LimAllCancelled" 6 "LimAllWithRstrcTime" 5 "LimAllWithRstrcTrailer" 4 "LimAllWithRstrcSnow" 3 "LimAllWithRstrcRain" 2 "LimAllWithoutQlfdRstrc" 1 "LimAllWithoutRestriction" 0 "OvertakingAllowed";
VAL_ 973 WwaWarn_B_Rq 1 "On" 0 "Off";
VAL_ 973 TsrVlUnitMsgTxt_D_Rq 3 "NoDataExists" 2 "Mph" 1 "Kph" 0 "Null";
VAL_ 973 TsrVLim2MsgTxt_D_Rq 255 "NoLimit" 254 "NotUsed2" 253 "NotUsed1" 252 "NotToBeDisplayed" 251 "LimitCancelled" 31 "1F_FA_Message31_250" 30 "Message30" 29 "Message29" 28 "Message28" 27 "Message27" 26 "Message26" 25 "Message25" 24 "Message24" 23 "Message23" 22 "Message22" 21 "Message21" 20 "Message20" 19 "Message19" 18 "Message18" 17 "Message17" 16 "Message16" 15 "Message15" 14 "Message14" 13 "Message13" 12 "Message12" 11 "Message11" 10 "Message10" 9 "Message9" 8 "Message8" 7 "Message7" 6 "Message6" 5 "Message5" 4 "Message4" 3 "Message3" 2 "Message2" 1 "Message1" 0 "Null";
VAL_ 973 TsrVLim1MsgTxt_D_Rq 255 "NoLimit" 254 "NotUsed2" 253 "NotUsed1" 252 "NotToBeDisplayed" 251 "LimitCancelled" 31 "1F_FA_Message31_250" 30 "Message30" 29 "Message29" 28 "Message28" 27 "Message27" 26 "Message26" 25 "Message25" 24 "Message24" 23 "Message23" 22 "Message22" 21 "Message21" 20 "Message20" 19 "Message19" 18 "Message18" 17 "Message17" 16 "Message16" 15 "Message15" 14 "Message14" 13 "Message13" 12 "Message12" 11 "Message11" 10 "Message10" 9 "Message9" 8 "Message8" 7 "Message7" 6 "Message6" 5 "Message5" 4 "Message4" 3 "Message3" 2 "Message2" 1 "Message1" 0 "Null";
VAL_ 973 TsrVl2StatMsgTxt_D_Rq 3 "LimitOutdated" 2 "LimitReiable" 1 "LimitChanged" 0 "Null";
VAL_ 973 TsrVl2RstrcMsgTxt_D_Rq 3 "NotUsed" 2 "NoRecognizableRestriction" 1 "NoSpeedLimitRestriction" 0 "Null";
VAL_ 973 TsrVl1StatMsgTxt_D_Rq 3 "LimitOutdated" 2 "LimitReiable" 1 "LimitChanged" 0 "Null";
VAL_ 973 TsrVl1RstrcMsgTxt_D_Rq 3 "NotUsed" 2 "NoRecognizableRestriction" 1 "NoSpeedLimitRestriction" 0 "Null";
VAL_ 973 TsrStatMsgTxt_D_Rq 7 "NotUsed" 6 "NoDataExists" 5 "TSR_Error" 4 "Available_NavigationOnly" 3 "Available_CameraOnly" 2 "Available_FusionMode" 1 "TSR_Off" 0 "Null";
VAL_ 973 TsrOvtkStatMsgTxt_D_Rq 3 "LimitOutdated" 2 "LimitReiable" 1 "LimitChanged" 0 "Null";
VAL_ 973 TsrOvtkMsgTxt_D_Rq 7 "LimForTrucksCancelled" 6 "LimForTrucksWoQlfdRstrc" 5 "LimForTrucksWithoutRstrc" 4 "LimAllCancelled" 3 "LimAllWithoutQlfdRstrc" 2 "LimAllWithoutRestriction" 1 "OvertakingAllowed" 0 "Null";
VAL_ 973 TsrOswWarnMsgTxt_D_Rq 3 "NotUsed" 2 "True" 1 "False" 0 "Null";
VAL_ 973 TsrMsgTxt_D_Rq 15 "NotUsed6" 14 "NotUsed5" 13 "NotUsed4" 12 "NotUsed3" 11 "NotUsed2" 10 "NotUsed1" 9 "RecgnzdSignNotUsblForDsply" 8 "LimitedSystemPerformance" 7 "OffRoad" 6 "RegionNotSupported" 5 "CountryNotSupported" 4 "WrngNavDatIncompDatCarrier" 3 "NoNavDataAvailable" 2 "NoNavAvailableSwitchedOff" 1 "NoInformationAllOK" 0 "Null";
VAL_ 970 LkaDrvOvrrd_D_Rq 3 "Level_3" 2 "Level_2" 1 "Level_1" 0 "Level_0";
VAL_ 970 LkaActvStats_D2_Req 7 "NotUsed" 6 "LkaIncrIntervRight" 5 "LkaSupprRight" 4 "LkaStandIntervRight" 3 "LkaSupprLeft" 2 "LkaStandIntervLeft" 1 "LkaIncrIntervLeft" 0 "LkaNoInterv";
VAL_ 970 LaRefAng_No_Req 4095 "Fault";
VAL_ 970 LaRampType_B_Req 1 "Quick" 0 "Smooth";
VAL_ 970 LaCurvature_No_Calc 4095 "Fault";
VAL_ 970 LdwActvStats_D_Req 7 "LDW_Suppress_Right_Left" 6 "Not_Used2" 5 "LDW_Suppress_Right" 4 "LDW_Warning_Right" 3 "LDW_Suppress_Left" 2 "LDW_Warning_Left" 1 "LDW_DemoVibration" 0 "LDW_Idle";
VAL_ 970 LdwActvIntns_D_Req 3 "High" 2 "Medium" 1 "Low" 0 "None";
VAL_ 962 AdbBrdr3DistRigh_D_Stat 15 "DistGreater800m" 14 "Dist700mTo800m" 13 "Dist600mTo700m" 12 "Dist500mTo600m" 11 "Dist400mTo500m" 10 "Dist300mTo400m" 9 "Dist200mTo300m" 8 "Dist175mTo200m" 7 "Dist150mTo175m" 6 "Dist125mTo150m" 5 "Dist100mTo125m" 4 "Dist75mTo100m" 3 "Dist50mTo75m" 2 "Dist25mTo50m" 1 "Dist15mTo25m" 0 "Dist0mTo15m";
VAL_ 962 AdbBrdr3DistLeft_D_Stat 15 "DistGreater800m" 14 "Dist700mTo800m" 13 "Dist600mTo700m" 12 "Dist500mTo600m" 11 "Dist400mTo500m" 10 "Dist300mTo400m" 9 "Dist200mTo300m" 8 "Dist175mTo200m" 7 "Dist150mTo175m" 6 "Dist125mTo150m" 5 "Dist100mTo125m" 4 "Dist75mTo100m" 3 "Dist50mTo75m" 2 "Dist25mTo50m" 1 "Dist15mTo25m" 0 "Dist0mTo15m";
VAL_ 962 AdbMde3_D_Rq 3 "MarkerLightFlashing" 2 "MarkerLightConstant" 1 "Spot" 0 "None";
VAL_ 962 AdbIntns3_D_Rq 3 "Maximum" 2 "Medium" 1 "Low" 0 "Off";
VAL_ 962 AdbBrdr3Up_An_Rq 511 "Faulty" 510 "NoDataExists";
VAL_ 962 AdbBrdr3Right_An_Rq 2047 "Faulty" 2046 "NoDataExists";
VAL_ 962 AdbBrdr3Low_An_Rq 511 "Faulty" 510 "NoDataExists";
VAL_ 962 AdbBrdr3Left_An_Rq 2047 "Faulty" 2046 "NoDataExists";
VAL_ 961 AdbBrdr2DistRigh_D_Stat 15 "DistGreater800m" 14 "Dist700mTo800m" 13 "Dist600mTo700m" 12 "Dist500mTo600m" 11 "Dist400mTo500m" 10 "Dist300mTo400m" 9 "Dist200mTo300m" 8 "Dist175mTo200m" 7 "Dist150mTo175m" 6 "Dist125mTo150m" 5 "Dist100mTo125m" 4 "Dist75mTo100m" 3 "Dist50mTo75m" 2 "Dist25mTo50m" 1 "Dist15mTo25m" 0 "Dist0mTo15m";
VAL_ 961 AdbBrdr2DistLeft_D_Stat 15 "DistGreater800m" 14 "Dist700mTo800m" 13 "Dist600mTo700m" 12 "Dist500mTo600m" 11 "Dist400mTo500m" 10 "Dist300mTo400m" 9 "Dist200mTo300m" 8 "Dist175mTo200m" 7 "Dist150mTo175m" 6 "Dist125mTo150m" 5 "Dist100mTo125m" 4 "Dist75mTo100m" 3 "Dist50mTo75m" 2 "Dist25mTo50m" 1 "Dist15mTo25m" 0 "Dist0mTo15m";
VAL_ 961 AdbMde2_D_Rq 3 "MarkerLightFlashing" 2 "MarkerLightConstant" 1 "Spot" 0 "None";
VAL_ 961 AdbIntns2_D_Rq 3 "Maximum" 2 "Medium" 1 "Low" 0 "Off";
VAL_ 961 AdbBrdr2Up_An_Rq 511 "Faulty" 510 "NoDataExists";
VAL_ 961 AdbBrdr2Right_An_Rq 2047 "Faulty" 2046 "NoDataExists";
VAL_ 961 AdbBrdr2Low_An_Rq 511 "Faulty" 510 "NoDataExists";
VAL_ 961 AdbBrdr2Left_An_Rq 2047 "Faulty" 2046 "NoDataExists";
VAL_ 394 AccStopStat_D_Dsply 3 "PressResume" 2 "Stopped" 1 "ResumeReady" 0 "NoDisplay";
VAL_ 394 AccTrgDist2_D_Dsply 15 "DIST_ACTIVE_13_Farthest" 14 "DIST_ACTIVE_12" 13 "DIST_ACTIVE_11" 12 "DIST_ACTIVE_10" 11 "DIST_ACTIVE_9" 10 "DIST_ACTIVE_8" 9 "DIST_ACTIVE_7" 8 "DIST_ACTIVE_6" 7 "DIST_ACTIVE_5" 6 "DIST_ACTIVE_4" 5 "DIST_ACTIVE_3" 4 "DIST_ACTIVE_2" 3 "DIST_ACTIVE_1_Closest" 2 "DIST_ACTIVE_No_Target" 1 "DIST_STANDBY" 0 "DIST_OFF";
VAL_ 394 AccStopRes_B_Dsply 1 "Yes" 0 "No";
VAL_ 394 TjaWarn_D_Rq 7 "NotUsed_4" 6 "NotUsed_3" 5 "NotUsed_2" 4 "NotUsed_1" 3 "HardTakeOverLevel2" 2 "HardTakeOverLevel1" 1 "TrafficJamAssistCancel" 0 "NoWarning";
VAL_ 394 Tja_D_Stat 7 "NotUsed_1" 6 "ActiveWarningRight" 5 "ActiveWarningLeft" 4 "ActiveInterventionRight" 3 "ActiveInterventionLeft" 2 "Active" 1 "Standby" 0 "Off";
VAL_ 394 TjaMsgTxt_D_Dsply 7 "NotUsed_4" 6 "NotUsed_3" 5 "NotUsed_2" 4 "NotUsed_1" 3 "TurnOnAdaptCruiseControl" 2 "TrafficJamAssistSelected" 1 "TrafficJamAssistUnavailabl" 0 "NoMessage";
VAL_ 394 IaccLamp_D_Rq 3 "NotUsed_2" 2 "NotUsed_1" 1 "DisplayIaccIcon" 0 "DoNotDisplayIaccIcon";
VAL_ 394 AccMsgTxt_D2_Rq 15 "NotUsed_1" 14 "NCC_Enabled_Warning" 13 "IACC_TJA_Selected" 12 "ACC_TJA_Selected" 11 "IACC_Selected" 10 "Press_Brake_To_Hold" 9 "Only_Following_In_Low_Spd" 8 "TJA_Unavailable" 7 "Shift_Down" 6 "IACC_Unavailable" 5 "ACC_Selected" 4 "ACC_Overridden" 3 "Brake_Capacity_Warning" 2 "ACC_Cancelled" 1 "ACC_Unavailable" 0 "No_Text";
VAL_ 394 FcwDeny_B_Dsply 1 "Yes" 0 "No";
VAL_ 394 FcwMemStat_B_Actl 1 "On" 0 "Off";
VAL_ 394 AccTGap_B_Dsply 1 "Yes" 0 "No";
VAL_ 394 CadsAlignIncplt_B_Actl 1 "Yes" 0 "No";
VAL_ 394 AccFllwMde_B_Dsply 1 "Yes" 0 "No";
VAL_ 394 CadsRadrBlck_B_Actl 1 "Yes" 0 "No";
VAL_ 394 CmbbPostEvnt_B_Dsply 1 "Yes" 0 "No";
VAL_ 394 AccStopMde_B_Dsply 1 "Yes" 0 "No";
VAL_ 394 FcwMemSens_D_Actl 3 "FCW_Sensitivity_3" 2 "FCW_Sensitivity_2" 1 "FCW_Sensitivity_1" 0 "Not_Used";
VAL_ 394 FcwMsgTxt_D_Rq 7 "Undefined_3" 6 "Undefined_2" 5 "Low_Visibility" 4 "Unavailable_DueTo_LowSpeed" 3 "Available" 2 "Unavailable" 1 "Off" 0 "No_Text";
VAL_ 394 AccWarn_D_Dsply 3 "BrakeReleaseWarn_In_StopMd" 2 "Brake_Capacity_Warning" 1 "Cancel_Warning" 0 "No_Warning";
VAL_ 394 FcwVisblWarn_B_Rq 1 "On" 0 "Off";
VAL_ 394 FcwAudioWarn_B_Rq 1 "On" 0 "Off";
VAL_ 394 AccTGap_D_Dsply 7 "Undefined_2" 6 "Undefined_1" 5 "Time_Gap_5" 4 "Time_Gap_4" 3 "Time_Gap_3" 2 "Time_Gap_2" 1 "Time_Gap_1" 0 "Not_Used";
VAL_ 394 AccMemEnbl_B_RqDrv 1 "Adaptive_Cruise" 0 "Normal_Cruise";
VAL_ 394 FdaMem_B_Stat 1 "On" 0 "Off";
VAL_ 391 HudBlk3_B_Rq 1 "Yes" 0 "No";
VAL_ 391 HudBlk2_B_Rq 1 "Yes" 0 "No";
VAL_ 391 HudBlk1_B_Rq 1 "Yes" 0 "No";
VAL_ 391 HudFlashRate_D_Actl 3 "Unused" 2 "Flash_4Hz_50Prct_DutyCycle" 1 "On" 0 "Off";
VAL_ 391 CmbbBrkPrchg_D_Rq 3 "Undefined" 2 "Level_2_PreCharge_Request" 1 "Level_1_PreCharge_Request" 0 "No_PreCharge_Request";
VAL_ 391 CmbbBrkDecel_B_Rq 1 "Yes" 0 "No";
VAL_ 391 CmbbBaSens_D_Rq 3 "Level_3" 2 "Level_2" 1 "Level_1" 0 "Normal";
VAL_ 390 AccBrkPulse_B_Rq 1 "True" 0 "False";
VAL_ 390 AccAutoResum_D_Rq 3 "NotUsed" 2 "Active" 1 "Pending" 0 "Off";
VAL_ 390 AccBrkPrkEl_B_Rq 1 "Yes" 0 "No";
VAL_ 390 Cmbb_B_Enbl 1 "Yes" 0 "No";
VAL_ 390 CmbbOvrrd_B_RqDrv 1 "Yes" 0 "No";
VAL_ 390 CmbbDeny_B_Actl 1 "Yes" 0 "No";
VAL_ 390 CmbbEngTqMn_B_Rq 1 "Yes" 0 "No";
VAL_ 390 AccDeny_B_Rq 1 "Yes" 0 "No";
VAL_ 390 AccResumEnbl_B_Rq 1 "Yes" 0 "No";
VAL_ 390 AccCancl_B_Rq 1 "Yes" 0 "No";
VAL_ 390 AccBrkPrchg_B_Rq 1 "Yes" 0 "No";
VAL_ 390 AccBrkDecel_B_Rq 1 "Active" 0 "Inactive";
VAL_ 390 AccStopStat_B_Rq 1 "Yes" 0 "No";
VAL_ 1153 TerrMde_D_RqDrv 7 "Fail_Safe_Default" 6 "Dynamic_Mode" 5 "Rock_Crawl_Mode" 4 "Mud_Ruts_Mode" 3 "Sand_Mode" 2 "Undefined" 1 "Low_Mu_Mode" 0 "Special_Operating_Mode_Off";
VAL_ 942 PrkAidDrvDir_D_Stat 7 "NotUsed_2" 6 "NotUsed_1" 5 "BackwardNegative" 4 "ForwardNegative" 3 "BackwardPositive" 2 "ForwardPositive" 1 "NoMotion" 0 "DirectionNotKnown";
VAL_ 942 PrkAidAcsyRear_D_Stat 3 "NotUsed" 2 "On" 1 "Off" 0 "Null";
VAL_ 942 PrkAidAcsyFront_D_Stat 3 "NotUsed" 2 "On" 1 "Off" 0 "Null";
VAL_ 930 BalrWndwRight_B_Stat 1 "Enable" 0 "Disable";
VAL_ 930 BalrSnsRight_D_Falt 3 "Invalid" 2 "SystemFailure" 1 "Blocked" 0 "Clear";
VAL_ 930 WndwPsngrRear_D_RqBalrr 3 "NotUsed" 2 "Stop" 1 "AutoUp" 0 "NoRequest";
VAL_ 930 WndwPsngr_D_RqBalrr 3 "NotUsed" 2 "Stop" 1 "AutoUp" 0 "NoRequest";
VAL_ 930 WndwDrvRear_D_RqBalrr 3 "NotUsed" 2 "Stop" 1 "AutoUp" 0 "NoRequest";
VAL_ 930 WndwDrv_D_RqBalrr 3 "NotUsed" 2 "Stop" 1 "AutoUp" 0 "NoRequest";
VAL_ 930 BalrRight_D_Stat 3 "Inhibited" 2 "Disabled" 1 "On" 0 "Off";
VAL_ 930 BalrMdeSelRight_B_Stat 1 "Enable" 0 "Disable";
VAL_ 930 BalrMdeRight_D_Stat 3 "NotUsed" 2 "High" 1 "Medium" 0 "Low";
VAL_ 930 BalrLckRight_B_Stat 1 "Enable" 0 "Disable";
VAL_ 930 BalrChimeRight_D_Rq 3 "NotUsed" 2 "Soft" 1 "Normal" 0 "Off";
VAL_ 930 CamraRearOn_B_RqBalrr 1 "Active" 0 "Inactive";
VAL_ 930 DrLckActv_B_RqBalrr 1 "Active" 0 "Null";
VAL_ 929 BalrChimeLeft_D_Rq 3 "NotUsed" 2 "Soft" 1 "Normal" 0 "Off";
VAL_ 929 BalrLeft_D_Stat 3 "Inhibited" 2 "Disabled" 1 "On" 0 "Off";
VAL_ 929 BalrWndwLeft_B_Stat 1 "Enable" 0 "Disable";
VAL_ 929 WndwPsngrRear_D_RqBalrl 3 "NotUsed" 2 "Stop" 1 "AutoUp" 0 "NoRequest";
VAL_ 929 WndwPsngr_D_RqBalrl 3 "NotUsed" 2 "Stop" 1 "AutoUp" 0 "NoRequest";
VAL_ 929 WndwDrvRear_D_RqBalrl 3 "NotUsed" 2 "Stop" 1 "AutoUp" 0 "NoRequest";
VAL_ 929 WndwDrv_D_RqBalrl 3 "NotUsed" 2 "Stop" 1 "AutoUp" 0 "NoRequest";
VAL_ 929 BalrSnsLeft_D_Falt 3 "Invalid" 2 "SystemFailure" 1 "Blocked" 0 "Clear";
VAL_ 929 BalrMdeSelLeft_B_Stat 1 "Enable" 0 "Disable";
VAL_ 929 BalrMdeLeft_D_Stat 3 "NotUsed" 2 "High" 1 "Medium" 0 "Low";
VAL_ 929 BalrLckLeft_B_Stat 1 "Enable" 0 "Disable";
VAL_ 929 CamraRearOn_B_RqBalrl 1 "Active" 0 "Inactive";
VAL_ 929 DrLckActv_B_RqBalrl 1 "Active" 0 "Null";
VAL_ 402 PrkAidSwtch_D_RqMnu 1 "Pressed" 0 "Not_Pressed";
VAL_ 402 ApaSwtch_D_RqMnu 3 "NotUsed2" 2 "NotUsed1" 1 "Pressed" 0 "Not_Pressed";
VAL_ 402 ApaMdeStat_D_RqDrv 7 "Faulty" 6 "Off" 5 "NotUsed2" 4 "NotUsed1" 3 "POA" 2 "PPA" 1 "SAPP" 0 "Inactive";
VAL_ 402 CamraViewSplit_B_Rq 1 "On" 0 "Off";
VAL_ 402 CamraZoomMan_D_Rq 7 "Unknown" 6 "Invalid" 5 "Zoom_Level_V" 4 "Zoom_Level_IV" 3 "Zoom_Level_III" 2 "Zoom_Level_II" 1 "Zoom_Level_I" 0 "Off";
VAL_ 402 CamraOvrlStat_D_Rq 1 "On" 0 "Off";
VAL_ 402 CamraOvrlDyn_D_Rq 1 "On" 0 "Off";
VAL_ 402 CamAutoTowbarZoom 1 "On" 0 "Off";
VAL_ 402 DistanceBarSetting 1 "On" 0 "Off";
VAL_ 924 DcacOut_Pw_Mx 2047 "Faulty" 2046 "NoDataExists";
VAL_ 924 DcacOut2_Pw_Actl 8191 "Faulty" 8190 "NoDataExists";
VAL_ 924 DcacOut1_Pw_Actl 8191 "Faulty" 8190 "NoDataExists";
VAL_ 924 DcacIn_Pw_Mx 2047 "Faulty" 2046 "NoDataExists";
VAL_ 923 DcacIn_U2_Actl 4095 "Faulty" 4094 "NoDataExists";
VAL_ 923 DcacIn_U_Actl 4095 "Fault" 4094 "NoDataExists";
VAL_ 923 DcacIn_I_Actl 2047 "Faulty" 2046 "NoDataExists";
VAL_ 923 Dcac_Te_Actl 255 "Faulty" 254 "NoDataExists";
VAL_ 922 DcacBp2BrkrOpn_B_Falt 1 "Faulted" 0 "NotFaulted";
VAL_ 922 DcacBp1BrkrOpn_B_Falt 1 "Faulted" 0 "NotFaulted";
VAL_ 922 DcacIpRcBrkrOpn_B_Falt 1 "Faulted" 0 "NotFaulted";
VAL_ 922 DcacRdy_D2_Stat 3 "Faulted" 2 "RecoverableFault" 1 "Active" 0 "Idle";
VAL_ 922 DcacOvrld_B_Falt 1 "Faulted" 0 "NotFaulted";
VAL_ 922 DcacOverTe_B_Falt 1 "Faulted" 0 "NotFaulted";
VAL_ 922 DcacGfci_B_Falt 1 "Faulted" 0 "NotFaulted";
VAL_ 922 DcacErr_B_Stat 1 "Faulted" 0 "NotFaulted";
VAL_ 922 DcacAcUDetct_B_Falt 1 "Faulted" 0 "NotFaulted";
VAL_ 922 DcacRdy_D_Stat 7 "NotUsed_2" 6 "NotUsed_1" 5 "Faulted" 4 "ProtectionTempearture" 3 "ProtectionOverload" 2 "ProtectionGfci" 1 "Active" 0 "Idle";
VAL_ 922 DcacPlugPrsnt_B_Stat 1 "Yes" 0 "No";
VAL_ 922 DcacClntFlw_D_Rq 3 "High" 2 "Medium" 1 "Low" 0 "Off";
